VERSION "WangHu V1.0"

NS_ :

BS_:

BU_: SBCU MBCU Tester Monitor01

BO_ 2551357615 SBCU15_State_Inf6: 8 SBCU
 SG_ SBCU15_Reports_Set_Status : 18|3@0+ (1,0) [0|0] ""  MBCU
 SG_ SBCU15_Confirms_Faultcode : 7|16@0+ (1,0) [0|0] ""  MBCU

BO_ 2551357614 SBCU14_State_Inf6: 8 SBCU
 SG_ SBCU14_Reports_Set_Status : 18|3@0+ (1,0) [0|0] ""  MBCU
 SG_ SBCU14_Confirms_Faultcode : 7|16@0+ (1,0) [0|0] ""  MBCU

BO_ 2551357613 SBCU13_State_Inf6: 8 SBCU
 SG_ SBCU13_Reports_Set_Status : 18|3@0+ (1,0) [0|0] ""  MBCU
 SG_ SBCU13_Confirms_Faultcode : 7|16@0+ (1,0) [0|0] ""  MBCU

BO_ 2551357612 SBCU12_State_Inf6: 8 SBCU
 SG_ SBCU12_Reports_Set_Status : 18|3@0+ (1,0) [0|0] ""  MBCU
 SG_ SBCU12_Confirms_Faultcode : 7|16@0+ (1,0) [0|0] ""  MBCU

BO_ 2551357611 SBCU11_State_Inf6: 8 SBCU
 SG_ SBCU11_Reports_Set_Status : 18|3@0+ (1,0) [0|0] ""  MBCU
 SG_ SBCU11_Confirms_Faultcode : 7|16@0+ (1,0) [0|0] ""  MBCU

BO_ 2551357610 SBCU10_State_Inf6: 8 SBCU
 SG_ SBCU10_Reports_Set_Status : 18|3@0+ (1,0) [0|0] ""  MBCU
 SG_ SBCU10_Confirms_Faultcode : 7|16@0+ (1,0) [0|0] ""  MBCU

BO_ 2551357609 SBCU9_State_Inf6: 8 SBCU
 SG_ SBCU9_Reports_Set_Status : 18|3@0+ (1,0) [0|0] ""  MBCU
 SG_ SBCU9_Confirms_Faultcode : 7|16@0+ (1,0) [0|0] ""  MBCU

BO_ 2551357608 SBCU8_State_Inf6: 8 SBCU
 SG_ SBCU8_Reports_Set_Status : 18|3@0+ (1,0) [0|0] ""  MBCU
 SG_ SBCU8_Confirms_Faultcode : 7|16@0+ (1,0) [0|0] ""  MBCU

BO_ 2551357607 SBCU7_State_Inf6: 8 SBCU
 SG_ SBCU7_Reports_Set_Status : 18|3@0+ (1,0) [0|0] ""  MBCU
 SG_ SBCU7_Confirms_Faultcode : 7|16@0+ (1,0) [0|0] ""  MBCU

BO_ 2551357606 SBCU6_State_Inf6: 8 SBCU
 SG_ SBCU6_Reports_Set_Status : 18|3@0+ (1,0) [0|0] ""  MBCU
 SG_ SBCU6_Confirms_Faultcode : 7|16@0+ (1,0) [0|0] ""  MBCU

BO_ 2551357605 SBCU5_State_Inf6: 8 SBCU
 SG_ SBCU5_Reports_Set_Status : 18|3@0+ (1,0) [0|0] ""  MBCU
 SG_ SBCU5_Confirms_Faultcode : 7|16@0+ (1,0) [0|0] ""  MBCU

BO_ 2551357604 SBCU4_State_Inf6: 8 SBCU
 SG_ SBCU4_Reports_Set_Status : 18|3@0+ (1,0) [0|0] ""  MBCU
 SG_ SBCU4_Confirms_Faultcode : 7|16@0+ (1,0) [0|0] ""  MBCU

BO_ 2551357603 SBCU3_State_Inf6: 8 SBCU
 SG_ SBCU3_Reports_Set_Status : 18|3@0+ (1,0) [0|0] ""  MBCU
 SG_ SBCU3_Confirms_Faultcode : 7|16@0+ (1,0) [0|0] ""  MBCU

BO_ 2551357602 SBCU2_State_Inf6: 8 SBCU
 SG_ SBCU2_Reports_Set_Status : 18|3@0+ (1,0) [0|0] ""  MBCU
 SG_ SBCU2_Confirms_Faultcode : 7|16@0+ (1,0) [0|0] ""  MBCU

BO_ 2551357601 SBCU1_State_Inf6: 8 SBCU
 SG_ SBCU1_Reports_Set_Status : 18|3@0+ (1,0) [0|0] ""  MBCU
 SG_ SBCU1_Confirms_Faultcode : 7|16@0+ (1,0) [0|0] ""  MBCU

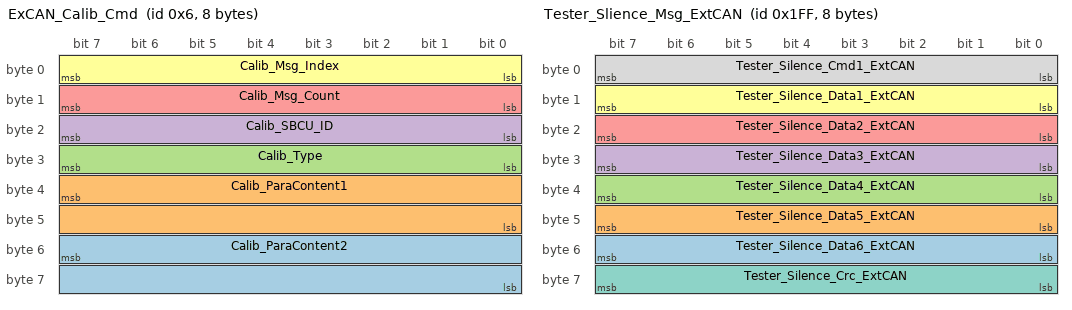
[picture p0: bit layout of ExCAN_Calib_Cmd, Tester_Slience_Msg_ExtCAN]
BO_ 6 ExCAN_Calib_Cmd: 8 MBCU
 SG_ Calib_ParaContent2 : 55|16@0+ (1,0) [0|0] ""  SBCU
 SG_ Calib_ParaContent1 : 39|16@0+ (1,0) [0|0] ""  SBCU
 SG_ Calib_Type : 31|8@0+ (1,0) [0|0] ""  SBCU
 SG_ Calib_SBCU_ID : 23|8@0+ (1,0) [0|0] ""  SBCU
 SG_ Calib_Msg_Count : 15|8@0+ (1,0) [0|0] ""  SBCU
 SG_ Calib_Msg_Index : 7|8@0+ (1,0) [0|0] ""  SBCU

BO_ 2551292079 SBCU15_State_Inf5: 8 SBCU
 SG_ SBCU15_ReleaseVersion : 7|32@0+ (1,0) [0|4294967295] ""  MBCU
 SG_ SBCU15_BMU_ReleaseVersion : 47|24@0+ (1,0) [0|0] ""  MBCU
 SG_ SBCU15_BMU_Index : 39|8@0+ (1,0) [0|0] ""  MBCU

BO_ 2551292078 SBCU14_State_Inf5: 8 SBCU
 SG_ SBCU14_ReleaseVersion : 7|32@0+ (1,0) [0|4294967295] ""  MBCU
 SG_ SBCU14_BMU_ReleaseVersion : 47|24@0+ (1,0) [0|0] ""  MBCU
 SG_ SBCU14_BMU_Index : 39|8@0+ (1,0) [0|0] ""  MBCU

BO_ 2551292077 SBCU13_State_Inf5: 8 SBCU
 SG_ SBCU13_ReleaseVersion : 7|32@0+ (1,0) [0|4294967295] ""  MBCU
 SG_ SBCU13_BMU_ReleaseVersion : 47|24@0+ (1,0) [0|0] ""  MBCU
 SG_ SBCU13_BMU_Index : 39|8@0+ (1,0) [0|0] ""  MBCU

BO_ 2551292076 SBCU12_State_Inf5: 8 SBCU
 SG_ SBCU12_ReleaseVersion : 7|32@0+ (1,0) [0|4294967295] ""  MBCU
 SG_ SBCU12_BMU_ReleaseVersion : 47|24@0+ (1,0) [0|0] ""  MBCU
 SG_ SBCU12_BMU_Index : 39|8@0+ (1,0) [0|0] ""  MBCU

BO_ 2551292075 SBCU11_State_Inf5: 8 SBCU
 SG_ SBCU11_ReleaseVersion : 7|32@0+ (1,0) [0|4294967295] ""  MBCU
 SG_ SBCU11_BMU_ReleaseVersion : 47|24@0+ (1,0) [0|0] ""  MBCU
 SG_ SBCU11_BMU_Index : 39|8@0+ (1,0) [0|0] ""  MBCU

BO_ 2551292074 SBCU10_State_Inf5: 8 SBCU
 SG_ SBCU10_ReleaseVersion : 7|32@0+ (1,0) [0|4294967295] ""  MBCU
 SG_ SBCU10_BMU_ReleaseVersion : 47|24@0+ (1,0) [0|0] ""  MBCU
 SG_ SBCU10_BMU_Index : 39|8@0+ (1,0) [0|0] ""  MBCU

BO_ 2551292073 SBCU9_State_Inf5: 8 SBCU
 SG_ SBCU9_ReleaseVersion : 7|32@0+ (1,0) [0|4294967295] ""  MBCU
 SG_ SBCU9_BMU_ReleaseVersion : 47|24@0+ (1,0) [0|0] ""  MBCU
 SG_ SBCU9_BMU_Index : 39|8@0+ (1,0) [0|0] ""  MBCU

BO_ 2551292072 SBCU8_State_Inf5: 8 SBCU
 SG_ SBCU8_ReleaseVersion : 7|32@0+ (1,0) [0|4294967295] ""  MBCU
 SG_ SBCU8_BMU_ReleaseVersion : 47|24@0+ (1,0) [0|0] ""  MBCU
 SG_ SBCU8_BMU_Index : 39|8@0+ (1,0) [0|0] ""  MBCU

BO_ 2551292071 SBCU7_State_Inf5: 8 SBCU
 SG_ SBCU7_ReleaseVersion : 7|32@0+ (1,0) [0|4294967295] ""  MBCU
 SG_ SBCU7_BMU_ReleaseVersion : 47|24@0+ (1,0) [0|0] ""  MBCU
 SG_ SBCU7_BMU_Index : 39|8@0+ (1,0) [0|0] ""  MBCU

BO_ 2551292070 SBCU6_State_Inf5: 8 SBCU
 SG_ SBCU6_ReleaseVersion : 7|32@0+ (1,0) [0|4294967295] ""  MBCU
 SG_ SBCU6_BMU_ReleaseVersion : 47|24@0+ (1,0) [0|0] ""  MBCU
 SG_ SBCU6_BMU_Index : 39|8@0+ (1,0) [0|0] ""  MBCU

BO_ 2551292069 SBCU5_State_Inf5: 8 SBCU
 SG_ SBCU5_ReleaseVersion : 7|32@0+ (1,0) [0|4294967295] ""  MBCU
 SG_ SBCU5_BMU_ReleaseVersion : 47|24@0+ (1,0) [0|0] ""  MBCU
 SG_ SBCU5_BMU_Index : 39|8@0+ (1,0) [0|0] ""  MBCU

BO_ 2551292068 SBCU4_State_Inf5: 8 SBCU
 SG_ SBCU4_ReleaseVersion : 7|32@0+ (1,0) [0|4294967295] ""  MBCU
 SG_ SBCU4_BMU_ReleaseVersion : 47|24@0+ (1,0) [0|0] ""  MBCU
 SG_ SBCU4_BMU_Index : 39|8@0+ (1,0) [0|0] ""  MBCU

BO_ 2551292067 SBCU3_State_Inf5: 8 SBCU
 SG_ SBCU3_ReleaseVersion : 7|32@0+ (1,0) [0|4294967295] ""  MBCU
 SG_ SBCU3_BMU_ReleaseVersion : 47|24@0+ (1,0) [0|0] ""  MBCU
 SG_ SBCU3_BMU_Index : 39|8@0+ (1,0) [0|0] ""  MBCU

BO_ 2551292066 SBCU2_State_Inf5: 8 SBCU
 SG_ SBCU2_ReleaseVersion : 7|32@0+ (1,0) [0|4294967295] ""  MBCU
 SG_ SBCU2_BMU_ReleaseVersion : 47|24@0+ (1,0) [0|0] ""  MBCU
 SG_ SBCU2_BMU_Index : 39|8@0+ (1,0) [0|0] ""  MBCU

BO_ 2551292065 SBCU1_State_Inf5: 8 SBCU
 SG_ SBCU1_BMU_ReleaseVersion : 47|24@0+ (1,0) [0|0] ""  MBCU
 SG_ SBCU1_BMU_Index : 39|8@0+ (1,0) [0|0] ""  MBCU
 SG_ SBCU1_ReleaseVersion : 7|32@0+ (1,0) [0|4294967295] ""  MBCU

BO_ 511 Tester_Slience_Msg_ExtCAN: 8 MBCU
 SG_ Tester_Silence_Data6_ExtCAN : 55|8@0+ (1,0) [0|0] ""  SBCU
 SG_ Tester_Silence_Data5_ExtCAN : 47|8@0+ (1,0) [0|0] ""  SBCU
 SG_ Tester_Silence_Data4_ExtCAN : 39|8@0+ (1,0) [0|0] ""  SBCU
 SG_ Tester_Silence_Data3_ExtCAN : 31|8@0+ (1,0) [0|0] ""  SBCU
 SG_ Tester_Silence_Data2_ExtCAN : 23|8@0+ (1,0) [0|0] ""  SBCU
 SG_ Tester_Silence_Data1_ExtCAN : 15|8@0+ (1,0) [0|0] ""  SBCU
 SG_ Tester_Silence_Crc_ExtCAN : 63|8@0+ (1,0) [0|0] ""  SBCU
 SG_ Tester_Silence_Cmd1_ExtCAN : 7|8@0+ (1,0) [0|0] ""  SBCU

BO_ 2551226543 SBCU15_State_Inf4: 8 SBCU
 SG_ SBCU15_CutOff_Relay_Pack_Volt : 23|16@0+ (0.1,0) [0|2000] "V"  MBCU
 SG_ SBCU15_CutOff_Relay_Current : 7|16@0+ (0.1,-3200) [0|0] "A"  MBCU

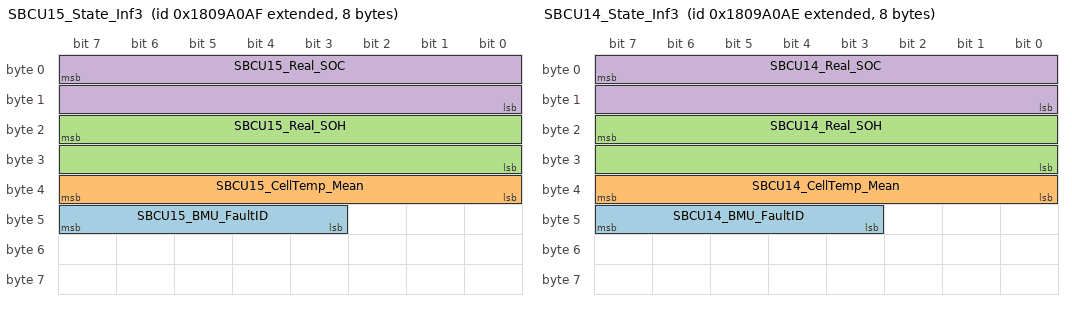
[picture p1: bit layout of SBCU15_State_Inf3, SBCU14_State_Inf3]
BO_ 2550767791 SBCU15_State_Inf3: 8 SBCU
 SG_ SBCU15_BMU_FaultID : 47|5@0+ (1,0) [0|0] ""  MBCU
 SG_ SBCU15_CellTemp_Mean : 39|8@0+ (1,-40) [0|0] "��"  MBCU
 SG_ SBCU15_Real_SOH : 23|16@0+ (0.1,0) [0|100] "%"  MBCU
 SG_ SBCU15_Real_SOC : 7|16@0+ (0.1,0) [0|100] "%"  MBCU

BO_ 2551226542 SBCU14_State_Inf4: 8 SBCU
 SG_ SBCU14_CutOff_Relay_Pack_Volt : 23|16@0+ (0.1,0) [0|2000] "V"  MBCU
 SG_ SBCU14_CutOff_Relay_Current : 7|16@0+ (0.1,-3200) [0|0] "A"  MBCU

BO_ 2550767790 SBCU14_State_Inf3: 8 SBCU
 SG_ SBCU14_BMU_FaultID : 47|5@0+ (1,0) [0|0] ""  MBCU
 SG_ SBCU14_CellTemp_Mean : 39|8@0+ (1,-40) [0|0] "��"  MBCU
 SG_ SBCU14_Real_SOH : 23|16@0+ (0.1,0) [0|100] "%"  MBCU
 SG_ SBCU14_Real_SOC : 7|16@0+ (0.1,0) [0|100] "%"  MBCU

BO_ 2551226541 SBCU13_State_Inf4: 8 SBCU
 SG_ SBCU13_CutOff_Relay_Pack_Volt : 23|16@0+ (0.1,0) [0|2000] "V"  MBCU
 SG_ SBCU13_CutOff_Relay_Current : 7|16@0+ (0.1,-3200) [0|0] "A"  MBCU

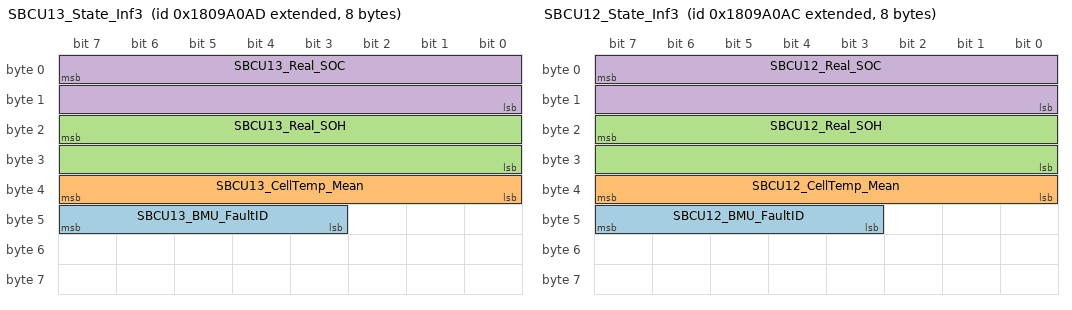
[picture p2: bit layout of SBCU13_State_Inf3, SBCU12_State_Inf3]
BO_ 2550767789 SBCU13_State_Inf3: 8 SBCU
 SG_ SBCU13_BMU_FaultID : 47|5@0+ (1,0) [0|0] ""  MBCU
 SG_ SBCU13_CellTemp_Mean : 39|8@0+ (1,-40) [0|0] "��"  MBCU
 SG_ SBCU13_Real_SOH : 23|16@0+ (0.1,0) [0|100] "%"  MBCU
 SG_ SBCU13_Real_SOC : 7|16@0+ (0.1,0) [0|100] "%"  MBCU

BO_ 2551226540 SBCU12_State_Inf4: 8 SBCU
 SG_ SBCU12_CutOff_Relay_Pack_Volt : 23|16@0+ (0.1,0) [0|2000] "V"  MBCU
 SG_ SBCU12_CutOff_Relay_Current : 7|16@0+ (0.1,-3200) [0|0] "A"  MBCU

BO_ 2550767788 SBCU12_State_Inf3: 8 SBCU
 SG_ SBCU12_BMU_FaultID : 47|5@0+ (1,0) [0|0] ""  MBCU
 SG_ SBCU12_CellTemp_Mean : 39|8@0+ (1,-40) [0|0] "��"  MBCU
 SG_ SBCU12_Real_SOH : 23|16@0+ (0.1,0) [0|100] "%"  MBCU
 SG_ SBCU12_Real_SOC : 7|16@0+ (0.1,0) [0|100] "%"  MBCU

BO_ 2551226539 SBCU11_State_Inf4: 8 SBCU
 SG_ SBCU11_CutOff_Relay_Pack_Volt : 23|16@0+ (0.1,0) [0|2000] "V"  MBCU
 SG_ SBCU11_CutOff_Relay_Current : 7|16@0+ (0.1,-3200) [0|0] "A"  MBCU

BO_ 2550767787 SBCU11_State_Inf3: 8 SBCU
 SG_ SBCU11_BMU_FaultID : 47|5@0+ (1,0) [0|0] ""  MBCU
 SG_ SBCU11_CellTemp_Mean : 39|8@0+ (1,-40) [0|0] "��"  MBCU
 SG_ SBCU11_Real_SOH : 23|16@0+ (0.1,0) [0|100] "%"  MBCU
 SG_ SBCU11_Real_SOC : 7|16@0+ (0.1,0) [0|100] "%"  MBCU

BO_ 2551226538 SBCU10_State_Inf4: 8 SBCU
 SG_ SBCU10_CutOff_Relay_Pack_Volt : 23|16@0+ (0.1,0) [0|2000] "V"  MBCU
 SG_ SBCU10_CutOff_Relay_Current : 7|16@0+ (0.1,-3200) [0|0] "A"  MBCU

BO_ 2550767786 SBCU10_State_Inf3: 8 SBCU
 SG_ SBCU10_BMU_FaultID : 47|5@0+ (1,0) [0|0] ""  MBCU
 SG_ SBCU10_CellTemp_Mean : 39|8@0+ (1,-40) [0|0] "��"  MBCU
 SG_ SBCU10_Real_SOH : 23|16@0+ (0.1,0) [0|100] "%"  MBCU
 SG_ SBCU10_Real_SOC : 7|16@0+ (0.1,0) [0|100] "%"  MBCU

BO_ 2551226537 SBCU9_State_Inf4: 8 SBCU
 SG_ SBCU9_CutOff_Relay_Pack_Volt : 23|16@0+ (0.1,0) [0|2000] "V"  MBCU
 SG_ SBCU9_CutOff_Relay_Current : 7|16@0+ (0.1,-3200) [0|0] "A"  MBCU

BO_ 2550767785 SBCU9_State_Inf3: 8 SBCU
 SG_ SBCU9_BMU_FaultID : 47|5@0+ (1,0) [0|0] ""  MBCU
 SG_ SBCU9_CellTemp_Mean : 39|8@0+ (1,-40) [0|0] "��"  MBCU
 SG_ SBCU9_Real_SOH : 23|16@0+ (0.1,0) [0|100] "%"  MBCU
 SG_ SBCU9_Real_SOC : 7|16@0+ (0.1,0) [0|100] "%"  MBCU

BO_ 2551226536 SBCU8_State_Inf4: 8 SBCU
 SG_ SBCU8_CutOff_Relay_Pack_Volt : 23|16@0+ (0.1,0) [0|2000] "V"  MBCU
 SG_ SBCU8_CutOff_Relay_Current : 7|16@0+ (0.1,-3200) [0|0] "A"  MBCU

BO_ 2550767784 SBCU8_State_Inf3: 8 SBCU
 SG_ SBCU8_BMU_FaultID : 47|5@0+ (1,0) [0|0] ""  MBCU
 SG_ SBCU8_CellTemp_Mean : 39|8@0+ (1,-40) [0|0] "��"  MBCU
 SG_ SBCU8_Real_SOH : 23|16@0+ (0.1,0) [0|100] "%"  MBCU
 SG_ SBCU8_Real_SOC : 7|16@0+ (0.1,0) [0|100] "%"  MBCU

BO_ 2551226535 SBCU7_State_Inf4: 8 SBCU
 SG_ SBCU7_CutOff_Relay_Pack_Volt : 23|16@0+ (0.1,0) [0|2000] "V"  MBCU
 SG_ SBCU7_CutOff_Relay_Current : 7|16@0+ (0.1,-3200) [0|0] "A"  MBCU

BO_ 2550767783 SBCU7_State_Inf3: 8 SBCU
 SG_ SBCU7_BMU_FaultID : 47|5@0+ (1,0) [0|0] ""  MBCU
 SG_ SBCU7_CellTemp_Mean : 39|8@0+ (1,-40) [0|0] "��"  MBCU
 SG_ SBCU7_Real_SOH : 23|16@0+ (0.1,0) [0|100] "%"  MBCU
 SG_ SBCU7_Real_SOC : 7|16@0+ (0.1,0) [0|100] "%"  MBCU

BO_ 2551226534 SBCU6_State_Inf4: 8 SBCU
 SG_ SBCU6_CutOff_Relay_Pack_Volt : 23|16@0+ (0.1,0) [0|2000] "V"  MBCU
 SG_ SBCU6_CutOff_Relay_Current : 7|16@0+ (0.1,-3200) [0|0] "A"  MBCU

BO_ 2550767782 SBCU6_State_Inf3: 8 SBCU
 SG_ SBCU6_BMU_FaultID : 47|5@0+ (1,0) [0|0] ""  MBCU
 SG_ SBCU6_CellTemp_Mean : 39|8@0+ (1,-40) [0|0] "��"  MBCU
 SG_ SBCU6_Real_SOH : 23|16@0+ (0.1,0) [0|100] "%"  MBCU
 SG_ SBCU6_Real_SOC : 7|16@0+ (0.1,0) [0|100] "%"  MBCU

BO_ 2551226533 SBCU5_State_Inf4: 8 SBCU
 SG_ SBCU5_CutOff_Relay_Pack_Volt : 23|16@0+ (0.1,0) [0|2000] "V"  MBCU
 SG_ SBCU5_CutOff_Relay_Current : 7|16@0+ (0.1,-3200) [0|0] "A"  MBCU

BO_ 2550767781 SBCU5_State_Inf3: 8 SBCU
 SG_ SBCU5_BMU_FaultID : 47|5@0+ (1,0) [0|0] ""  MBCU
 SG_ SBCU5_CellTemp_Mean : 39|8@0+ (1,-40) [0|0] "��"  MBCU
 SG_ SBCU5_Real_SOH : 23|16@0+ (0.1,0) [0|100] "%"  MBCU
 SG_ SBCU5_Real_SOC : 7|16@0+ (0.1,0) [0|100] "%"  MBCU

BO_ 2551226532 SBCU4_State_Inf4: 8 SBCU
 SG_ SBCU4_CutOff_Relay_Pack_Volt : 23|16@0+ (0.1,0) [0|2000] "V"  MBCU
 SG_ SBCU4_CutOff_Relay_Current : 7|16@0+ (0.1,-3200) [0|0] "A"  MBCU

BO_ 2550767780 SBCU4_State_Inf3: 8 SBCU
 SG_ SBCU4_BMU_FaultID : 47|5@0+ (1,0) [0|0] ""  MBCU
 SG_ SBCU4_CellTemp_Mean : 39|8@0+ (1,-40) [0|0] "��"  MBCU
 SG_ SBCU4_Real_SOH : 23|16@0+ (0.1,0) [0|100] "%"  MBCU
 SG_ SBCU4_Real_SOC : 7|16@0+ (0.1,0) [0|100] "%"  MBCU

BO_ 2551226531 SBCU3_State_Inf4: 8 SBCU
 SG_ SBCU3_CutOff_Relay_Pack_Volt : 23|16@0+ (0.1,0) [0|2000] "V"  MBCU
 SG_ SBCU3_CutOff_Relay_Current : 7|16@0+ (0.1,-3200) [0|0] "A"  MBCU

BO_ 2550767779 SBCU3_State_Inf3: 8 SBCU
 SG_ SBCU3_BMU_FaultID : 47|5@0+ (1,0) [0|0] ""  MBCU
 SG_ SBCU3_CellTemp_Mean : 39|8@0+ (1,-40) [0|0] "��"  MBCU
 SG_ SBCU3_Real_SOH : 23|16@0+ (0.1,0) [0|100] "%"  MBCU
 SG_ SBCU3_Real_SOC : 7|16@0+ (0.1,0) [0|100] "%"  MBCU

BO_ 2551226530 SBCU2_State_Inf4: 8 SBCU
 SG_ SBCU2_CutOff_Relay_Pack_Volt : 23|16@0+ (0.1,0) [0|2000] "V"  MBCU
 SG_ SBCU2_CutOff_Relay_Current : 7|16@0+ (0.1,-3200) [0|0] "A"  MBCU

BO_ 2550767778 SBCU2_State_Inf3: 8 SBCU
 SG_ SBCU2_BMU_FaultID : 47|5@0+ (1,0) [0|0] ""  MBCU
 SG_ SBCU2_CellTemp_Mean : 39|8@0+ (1,-40) [0|0] "��"  MBCU
 SG_ SBCU2_Real_SOH : 23|16@0+ (0.1,0) [0|100] "%"  MBCU
 SG_ SBCU2_Real_SOC : 7|16@0+ (0.1,0) [0|100] "%"  MBCU

BO_ 2551226529 SBCU1_State_Inf4: 8 SBCU
 SG_ SBCU1_CutOff_Relay_Pack_Volt : 23|16@0+ (0.1,0) [0|2000] "V"  MBCU
 SG_ SBCU1_CutOff_Relay_Current : 7|16@0+ (0.1,-3200) [0|0] "A"  MBCU

BO_ 2550767777 SBCU1_State_Inf3: 8 SBCU
 SG_ SBCU1_BMU_FaultID : 47|5@0+ (1,0) [0|0] ""  MBCU
 SG_ SBCU1_CellTemp_Mean : 39|8@0+ (1,-40) [0|0] "��"  MBCU
 SG_ SBCU1_Real_SOH : 23|16@0+ (0.1,0) [0|100] "%"  MBCU
 SG_ SBCU1_Real_SOC : 7|16@0+ (0.1,0) [0|100] "%"  MBCU

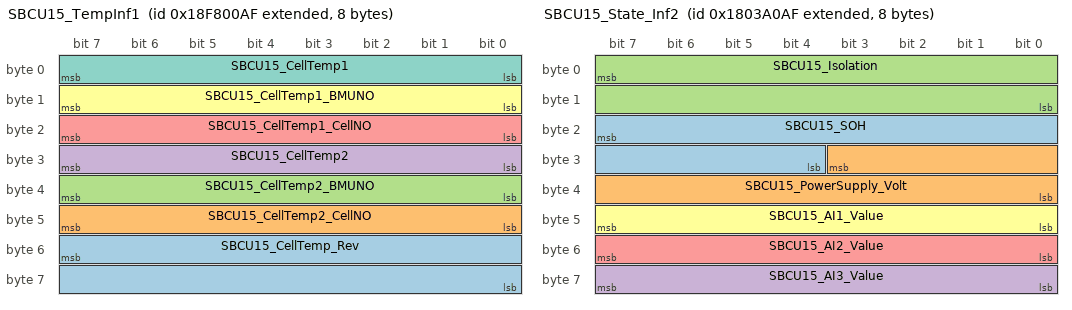
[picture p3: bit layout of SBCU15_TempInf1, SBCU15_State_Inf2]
BO_ 2566389935 SBCU15_TempInf1: 8 SBCU
 SG_ SBCU15_CellTemp_Rev : 55|16@0+ (1,0) [0|65535] ""  MBCU
 SG_ SBCU15_CellTemp2_CellNO : 47|8@0+ (1,0) [0|0] ""  MBCU
 SG_ SBCU15_CellTemp2_BMUNO : 39|8@0+ (1,0) [0|0] ""  MBCU
 SG_ SBCU15_CellTemp2 : 31|8@0+ (1,-40) [0|0] "��"  MBCU
 SG_ SBCU15_CellTemp1_CellNO : 23|8@0+ (1,0) [0|0] ""  MBCU
 SG_ SBCU15_CellTemp1_BMUNO : 15|8@0+ (1,0) [0|0] ""  MBCU
 SG_ SBCU15_CellTemp1 : 7|8@0+ (1,-40) [0|0] "��"  MBCU

BO_ 2550898863 SBCU15_Statis_AccumEng: 8 SBCU
 SG_ SBCU15_Accum_DchEng : 7|32@0+ (0.1,0) [0|4000000000] "kWh"  MBCU
 SG_ SBCU15_Accum_ChgEng : 39|32@0+ (0.1,0) [0|4000000000] "kWh"  MBCU

BO_ 2550833327 SBCU15_Statis_AccumCap: 8 SBCU
 SG_ SBCU15_Accum_DchCap : 7|32@0+ (0.1,0) [0|4000000000] "Ah"  MBCU
 SG_ SBCU15_Accum_ChgCap : 39|32@0+ (0.1,0) [0|4000000000] "Ah"  MBCU

BO_ 2550374575 SBCU15_State_Inf2: 8 SBCU
 SG_ SBCU15_SOH : 23|12@0+ (0.1,0) [0|0] "%"  MBCU
 SG_ SBCU15_PowerSupply_Volt : 27|12@0+ (0.1,0) [0|0] "V"  MBCU
 SG_ SBCU15_Isolation : 7|16@0+ (1,0) [0|65535] "kOhm"  MBCU
 SG_ SBCU15_AI3_Value : 63|8@0+ (1,0) [0|255] ""  MBCU
 SG_ SBCU15_AI2_Value : 55|8@0+ (1,0) [0|255] ""  MBCU
 SG_ SBCU15_AI1_Value : 47|8@0+ (1,0) [0|255] ""  MBCU

BO_ 2348982447 SBCU15_State_Inf1: 8 SBCU
 SG_ SBCU15_WorkMode : 11|4@0+ (1,0) [0|0] ""  MBCU
 SG_ SBCU15_Ready : 1|2@0+ (1,0) [0|0] ""  MBCU
 SG_ SBCU15_PreChgRelay_Status : 29|2@0+ (1,0) [0|0] ""  MBCU
 SG_ SBCU15_PosRelay_Status : 25|2@0+ (1,0) [0|0] ""  MBCU
 SG_ SBCU15_PosIso_Optical : 56|1@0+ (1,0) [0|0] ""  MBCU
 SG_ SBCU15_NegRelay_Status : 27|2@0+ (1,0) [0|0] ""  MBCU
 SG_ SBCU15_NegIso_Optical : 57|1@0+ (1,0) [0|0] ""  MBCU
 SG_ SBCU15_Life : 63|4@0+ (1,0) [0|0] ""  MBCU
 SG_ SBCU15_ISO_Status : 7|2@0+ (1,0) [0|3] ""  MBCU
 SG_ SBCU15_ISO_Allow : 5|2@0+ (1,0) [0|3] ""  MBCU
 SG_ SBCU15_HVOff_Req : 3|2@0+ (1,0) [0|0] ""  MBCU
 SG_ SBCU15_HV_Step : 15|4@0+ (1,0) [0|0] ""  MBCU
 SG_ SBCU15_HeatRelay_Status : 23|2@0+ (1,0) [0|0] ""  MBCU
 SG_ SBCU15_FcgRelay_Status : 31|2@0+ (1,0) [0|0] ""  MBCU
 SG_ SBCU15_FaultLevel : 59|2@0+ (1,0) [0|3] ""  MBCU
 SG_ SBCU15_FaultCode : 47|16@0+ (1,0) [0|65535] ""  MBCU
 SG_ SBCU15_FanRelay_Status : 21|2@0+ (1,0) [0|0] ""  MBCU
 SG_ SBCU15_DO3_Ctrl : 39|1@0+ (1,0) [0|0] ""  MBCU
 SG_ SBCU15_DO2_Ctrl : 38|1@0+ (1,0) [0|0] ""  MBCU
 SG_ SBCU15_DO1_Ctrl : 37|1@0+ (1,0) [0|0] ""  MBCU
 SG_ SBCU15_DI5_Status : 36|1@0+ (1,0) [0|0] ""  MBCU
 SG_ SBCU15_DI4_Status : 35|1@0+ (1,0) [0|0] ""  MBCU
 SG_ SBCU15_DI3_Status : 34|1@0+ (1,0) [0|0] ""  MBCU
 SG_ SBCU15_DI2_Status : 33|1@0+ (1,0) [0|0] ""  MBCU
 SG_ SBCU15_DI1_Status : 32|1@0+ (1,0) [0|0] ""  MBCU
 SG_ SBCU15_BMS_RunStatus : 19|4@0+ (1,0) [0|0] ""  MBCU

BO_ 2550505647 SBCU15_SOP_Inf2: 8 SBCU
 SG_ SBCU15_DchPeakPower_Limit : 7|16@0+ (0.1,0) [0|1000] "kW"  MBCU
 SG_ SBCU15_DchContinuousPower_Limit : 23|16@0+ (0.1,0) [0|1000] "kW"  MBCU
 SG_ SBCU15_ChgPeakPower_Limit : 39|16@0+ (0.1,0) [0|1000] "kW"  MBCU
 SG_ SBCU15_ChgContinuousPower_Limit : 55|16@0+ (0.1,0) [0|1000] "kW"  MBCU

BO_ 2550440111 SBCU15_SOP_Inf1: 8 SBCU
 SG_ SBCU15_DchPeakCurr_Limit : 7|16@0+ (0.1,0) [0|3200] "A"  MBCU
 SG_ SBCU15_DchContinuousCurr_Limit : 23|16@0+ (0.1,0) [0|3200] "A"  MBCU
 SG_ SBCU15_ChgPeakCurr_Limit : 39|16@0+ (0.1,0) [0|3200] "A"  MBCU
 SG_ SBCU15_ChgContinuousCurr_Limit : 55|16@0+ (0.1,0) [0|3200] "A"  MBCU

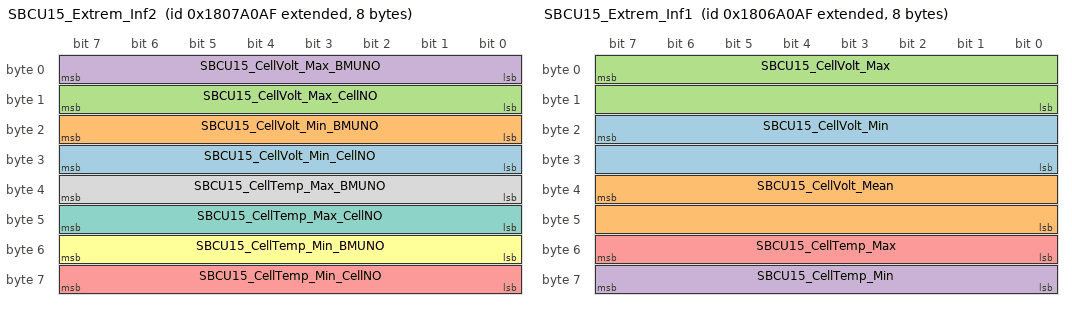
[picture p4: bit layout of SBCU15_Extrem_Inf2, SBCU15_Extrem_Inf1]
BO_ 2550636719 SBCU15_Extrem_Inf2: 8 SBCU
 SG_ SBCU15_CellVolt_Min_CellNO : 31|8@0+ (1,0) [0|255] ""  MBCU
 SG_ SBCU15_CellVolt_Min_BMUNO : 23|8@0+ (1,0) [0|16] ""  MBCU
 SG_ SBCU15_CellVolt_Max_CellNO : 15|8@0+ (1,0) [0|255] ""  MBCU
 SG_ SBCU15_CellVolt_Max_BMUNO : 7|8@0+ (1,0) [0|16] ""  MBCU
 SG_ SBCU15_CellTemp_Min_CellNO : 63|8@0+ (1,0) [0|255] ""  MBCU
 SG_ SBCU15_CellTemp_Min_BMUNO : 55|8@0+ (1,0) [0|16] ""  MBCU
 SG_ SBCU15_CellTemp_Max_CellNO : 47|8@0+ (1,0) [0|255] ""  MBCU
 SG_ SBCU15_CellTemp_Max_BMUNO : 39|8@0+ (1,0) [0|16] ""  MBCU

BO_ 2550571183 SBCU15_Extrem_Inf1: 8 SBCU
 SG_ SBCU15_CellVolt_Min : 23|16@0+ (0.001,0) [0|15] "V"  MBCU
 SG_ SBCU15_CellVolt_Mean : 39|16@0+ (0.001,0) [0|15] "V"  MBCU
 SG_ SBCU15_CellVolt_Max : 7|16@0+ (0.001,0) [0|15] "V"  MBCU
 SG_ SBCU15_CellTemp_Min : 63|8@0+ (1,-40) [0|0] "��"  MBCU
 SG_ SBCU15_CellTemp_Max : 55|8@0+ (1,-40) [0|0] "��"  MBCU

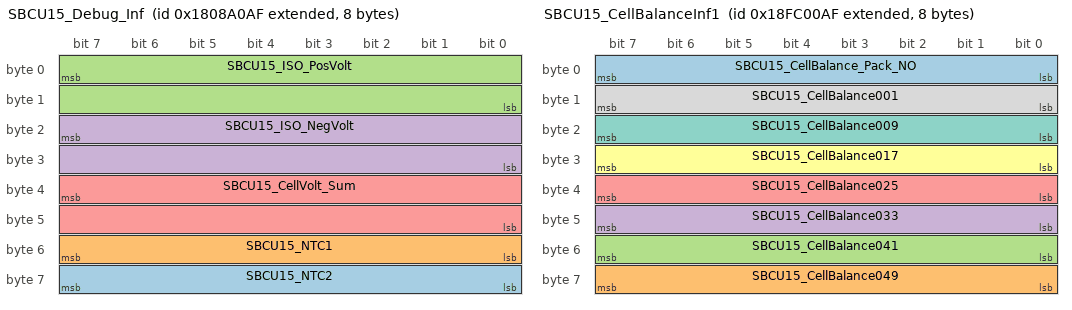
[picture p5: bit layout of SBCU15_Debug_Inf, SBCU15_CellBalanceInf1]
BO_ 2550702255 SBCU15_Debug_Inf: 8 SBCU
 SG_ SBCU15_NTC2 : 63|8@0+ (1,-40) [0|0] "��"  MBCU
 SG_ SBCU15_NTC1 : 55|8@0+ (1,-40) [0|0] "��"  MBCU
 SG_ SBCU15_ISO_PosVolt : 7|16@0+ (1,0) [0|65535] "mV"  MBCU
 SG_ SBCU15_ISO_NegVolt : 23|16@0+ (1,0) [0|65535] "mV"  MBCU
 SG_ SBCU15_CellVolt_Sum : 39|16@0+ (0.1,0) [0|0] "V"  MBCU

BO_ 2566652079 SBCU15_CellBalanceInf1: 8 SBCU
 SG_ SBCU15_CellBalance_Pack_NO : 7|8@0+ (1,0) [0|255] ""  MBCU
 SG_ SBCU15_CellBalance049 : 63|8@0+ (1,0) [0|255] ""  MBCU
 SG_ SBCU15_CellBalance041 : 55|8@0+ (1,0) [0|255] ""  MBCU
 SG_ SBCU15_CellBalance033 : 47|8@0+ (1,0) [0|255] ""  MBCU
 SG_ SBCU15_CellBalance025 : 39|8@0+ (1,0) [0|255] ""  MBCU
 SG_ SBCU15_CellBalance017 : 31|8@0+ (1,0) [0|255] ""  MBCU
 SG_ SBCU15_CellBalance009 : 23|8@0+ (1,0) [0|255] ""  MBCU
 SG_ SBCU15_CellBalance001 : 15|8@0+ (1,0) [0|255] ""  MBCU

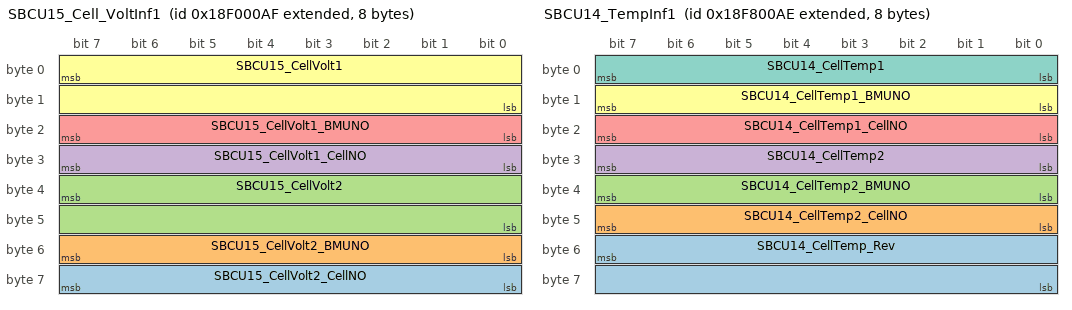
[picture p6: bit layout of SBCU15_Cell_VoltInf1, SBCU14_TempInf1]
BO_ 2565865647 SBCU15_Cell_VoltInf1: 8 SBCU
 SG_ SBCU15_CellVolt2_CellNO : 63|8@0+ (1,0) [0|0] ""  MBCU
 SG_ SBCU15_CellVolt2_BMUNO : 55|8@0+ (1,0) [0|0] ""  MBCU
 SG_ SBCU15_CellVolt2 : 39|16@0+ (0.001,0) [0|0] "V"  MBCU
 SG_ SBCU15_CellVolt1_CellNO : 31|8@0+ (1,0) [0|0] ""  MBCU
 SG_ SBCU15_CellVolt1_BMUNO : 23|8@0+ (1,0) [0|0] ""  MBCU
 SG_ SBCU15_CellVolt1 : 7|16@0+ (0.001,0) [0|0] "V"  MBCU

BO_ 2550243503 SBCU15_Basic_Inf: 8 SBCU
 SG_ SBCU15_SOC : 55|16@0+ (0.1,0) [0|100] "%"  MBCU
 SG_ SBCU15_Pack_Volt : 7|16@0+ (0.1,0) [0|2000] "V"  MBCU
 SG_ SBCU15_LinkVolt : 23|16@0+ (0.1,0) [0|2000] "V"  MBCU
 SG_ SBCU15_BusCurrent : 39|16@0+ (0.1,-3200) [0|0] "A"  MBCU

BO_ 2566389934 SBCU14_TempInf1: 8 SBCU
 SG_ SBCU14_CellTemp_Rev : 55|16@0+ (1,0) [0|65535] ""  MBCU
 SG_ SBCU14_CellTemp2_CellNO : 47|8@0+ (1,0) [0|0] ""  MBCU
 SG_ SBCU14_CellTemp2_BMUNO : 39|8@0+ (1,0) [0|0] ""  MBCU
 SG_ SBCU14_CellTemp2 : 31|8@0+ (1,-40) [0|0] "��"  MBCU
 SG_ SBCU14_CellTemp1_CellNO : 23|8@0+ (1,0) [0|0] ""  MBCU
 SG_ SBCU14_CellTemp1_BMUNO : 15|8@0+ (1,0) [0|0] ""  MBCU
 SG_ SBCU14_CellTemp1 : 7|8@0+ (1,-40) [0|0] "��"  MBCU

BO_ 2550898862 SBCU14_Statis_AccumEng: 8 SBCU
 SG_ SBCU14_Accum_DchEng : 7|32@0+ (0.1,0) [0|4000000000] "kWh"  MBCU
 SG_ SBCU14_Accum_ChgEng : 39|32@0+ (0.1,0) [0|4000000000] "kWh"  MBCU

BO_ 2550833326 SBCU14_Statis_AccumCap: 8 SBCU
 SG_ SBCU14_Accum_DchCap : 7|32@0+ (0.1,0) [0|4000000000] "Ah"  MBCU
 SG_ SBCU14_Accum_ChgCap : 39|32@0+ (0.1,0) [0|4000000000] "Ah"  MBCU

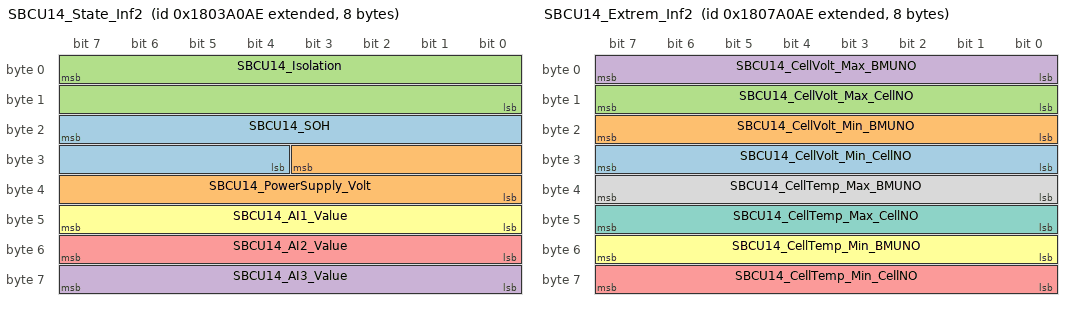
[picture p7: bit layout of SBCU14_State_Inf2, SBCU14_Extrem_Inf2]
BO_ 2550374574 SBCU14_State_Inf2: 8 SBCU
 SG_ SBCU14_SOH : 23|12@0+ (0.1,0) [0|0] "%"  MBCU
 SG_ SBCU14_PowerSupply_Volt : 27|12@0+ (0.1,0) [0|0] "V"  MBCU
 SG_ SBCU14_Isolation : 7|16@0+ (1,0) [0|65535] "kOhm"  MBCU
 SG_ SBCU14_AI3_Value : 63|8@0+ (1,0) [0|255] ""  MBCU
 SG_ SBCU14_AI2_Value : 55|8@0+ (1,0) [0|255] ""  MBCU
 SG_ SBCU14_AI1_Value : 47|8@0+ (1,0) [0|255] ""  MBCU

BO_ 2348982446 SBCU14_State_Inf1: 8 SBCU
 SG_ SBCU14_WorkMode : 11|4@0+ (1,0) [0|0] ""  MBCU
 SG_ SBCU14_Ready : 1|2@0+ (1,0) [0|0] ""  MBCU
 SG_ SBCU14_PreChgRelay_Status : 29|2@0+ (1,0) [0|0] ""  MBCU
 SG_ SBCU14_PosRelay_Status : 25|2@0+ (1,0) [0|0] ""  MBCU
 SG_ SBCU14_PosIso_Optical : 56|1@0+ (1,0) [0|0] ""  MBCU
 SG_ SBCU14_NegRelay_Status : 27|2@0+ (1,0) [0|0] ""  MBCU
 SG_ SBCU14_NegIso_Optical : 57|1@0+ (1,0) [0|0] ""  MBCU
 SG_ SBCU14_Life : 63|4@0+ (1,0) [0|0] ""  MBCU
 SG_ SBCU14_ISO_Status : 7|2@0+ (1,0) [0|3] ""  MBCU
 SG_ SBCU14_ISO_Allow : 5|2@0+ (1,0) [0|3] ""  MBCU
 SG_ SBCU14_HVOff_Req : 3|2@0+ (1,0) [0|0] ""  MBCU
 SG_ SBCU14_HV_Step : 15|4@0+ (1,0) [0|0] ""  MBCU
 SG_ SBCU14_HeatRelay_Status : 23|2@0+ (1,0) [0|0] ""  MBCU
 SG_ SBCU14_FcgRelay_Status : 31|2@0+ (1,0) [0|0] ""  MBCU
 SG_ SBCU14_FaultLevel : 59|2@0+ (1,0) [0|3] ""  MBCU
 SG_ SBCU14_FaultCode : 47|16@0+ (1,0) [0|65535] ""  MBCU
 SG_ SBCU14_FanRelay_Status : 21|2@0+ (1,0) [0|0] ""  MBCU
 SG_ SBCU14_DO3_Ctrl : 39|1@0+ (1,0) [0|0] ""  MBCU
 SG_ SBCU14_DO2_Ctrl : 38|1@0+ (1,0) [0|0] ""  MBCU
 SG_ SBCU14_DO1_Ctrl : 37|1@0+ (1,0) [0|0] ""  MBCU
 SG_ SBCU14_DI5_Status : 36|1@0+ (1,0) [0|0] ""  MBCU
 SG_ SBCU14_DI4_Status : 35|1@0+ (1,0) [0|0] ""  MBCU
 SG_ SBCU14_DI3_Status : 34|1@0+ (1,0) [0|0] ""  MBCU
 SG_ SBCU14_DI2_Status : 33|1@0+ (1,0) [0|0] ""  MBCU
 SG_ SBCU14_DI1_Status : 32|1@0+ (1,0) [0|0] ""  MBCU
 SG_ SBCU14_BMS_RunStatus : 19|4@0+ (1,0) [0|0] ""  MBCU

BO_ 2550505646 SBCU14_SOP_Inf2: 8 SBCU
 SG_ SBCU14_DchPeakPower_Limit : 7|16@0+ (0.1,0) [0|1000] "kW"  MBCU
 SG_ SBCU14_DchContinuousPower_Limit : 23|16@0+ (0.1,0) [0|1000] "kW"  MBCU
 SG_ SBCU14_ChgPeakPower_Limit : 39|16@0+ (0.1,0) [0|1000] "kW"  MBCU
 SG_ SBCU14_ChgContinuousPower_Limit : 55|16@0+ (0.1,0) [0|1000] "kW"  MBCU

BO_ 2550440110 SBCU14_SOP_Inf1: 8 SBCU
 SG_ SBCU14_DchPeakCurr_Limit : 7|16@0+ (0.1,0) [0|3200] "A"  MBCU
 SG_ SBCU14_DchContinuousCurr_Limit : 23|16@0+ (0.1,0) [0|3200] "A"  MBCU
 SG_ SBCU14_ChgPeakCurr_Limit : 39|16@0+ (0.1,0) [0|3200] "A"  MBCU
 SG_ SBCU14_ChgContinuousCurr_Limit : 55|16@0+ (0.1,0) [0|3200] "A"  MBCU

BO_ 2550636718 SBCU14_Extrem_Inf2: 8 SBCU
 SG_ SBCU14_CellVolt_Min_CellNO : 31|8@0+ (1,0) [0|255] ""  MBCU
 SG_ SBCU14_CellVolt_Min_BMUNO : 23|8@0+ (1,0) [0|16] ""  MBCU
 SG_ SBCU14_CellVolt_Max_CellNO : 15|8@0+ (1,0) [0|255] ""  MBCU
 SG_ SBCU14_CellVolt_Max_BMUNO : 7|8@0+ (1,0) [0|16] ""  MBCU
 SG_ SBCU14_CellTemp_Min_CellNO : 63|8@0+ (1,0) [0|255] ""  MBCU
 SG_ SBCU14_CellTemp_Min_BMUNO : 55|8@0+ (1,0) [0|16] ""  MBCU
 SG_ SBCU14_CellTemp_Max_CellNO : 47|8@0+ (1,0) [0|255] ""  MBCU
 SG_ SBCU14_CellTemp_Max_BMUNO : 39|8@0+ (1,0) [0|16] ""  MBCU

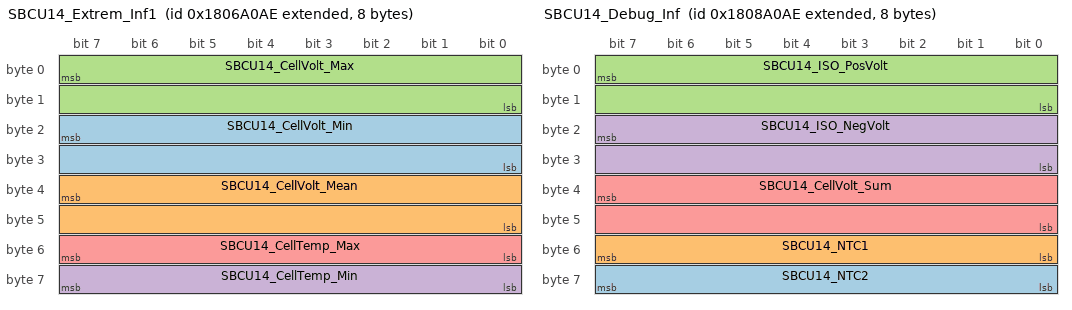
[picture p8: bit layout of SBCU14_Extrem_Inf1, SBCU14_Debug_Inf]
BO_ 2550571182 SBCU14_Extrem_Inf1: 8 SBCU
 SG_ SBCU14_CellVolt_Min : 23|16@0+ (0.001,0) [0|15] "V"  MBCU
 SG_ SBCU14_CellVolt_Mean : 39|16@0+ (0.001,0) [0|15] "V"  MBCU
 SG_ SBCU14_CellVolt_Max : 7|16@0+ (0.001,0) [0|15] "V"  MBCU
 SG_ SBCU14_CellTemp_Min : 63|8@0+ (1,-40) [0|0] "��"  MBCU
 SG_ SBCU14_CellTemp_Max : 55|8@0+ (1,-40) [0|0] "��"  MBCU

BO_ 2550702254 SBCU14_Debug_Inf: 8 SBCU
 SG_ SBCU14_NTC2 : 63|8@0+ (1,-40) [0|0] "��"  MBCU
 SG_ SBCU14_NTC1 : 55|8@0+ (1,-40) [0|0] "��"  MBCU
 SG_ SBCU14_ISO_PosVolt : 7|16@0+ (1,0) [0|65535] "mV"  MBCU
 SG_ SBCU14_ISO_NegVolt : 23|16@0+ (1,0) [0|65535] "mV"  MBCU
 SG_ SBCU14_CellVolt_Sum : 39|16@0+ (0.1,0) [0|0] "V"  MBCU

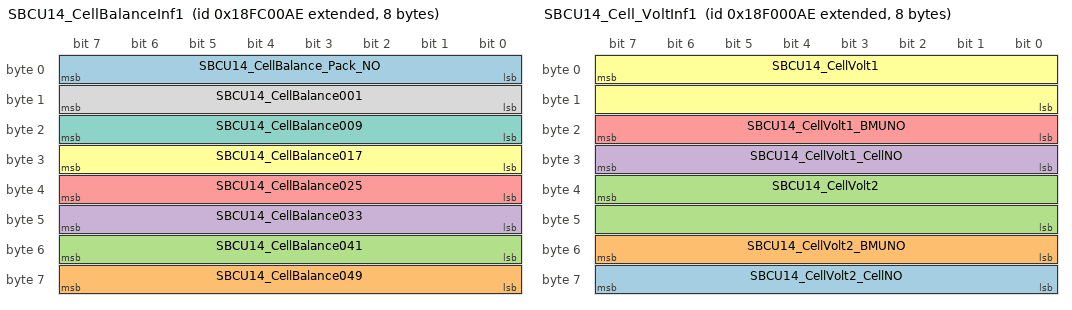
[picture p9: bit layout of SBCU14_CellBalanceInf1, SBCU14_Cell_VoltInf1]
BO_ 2566652078 SBCU14_CellBalanceInf1: 8 SBCU
 SG_ SBCU14_CellBalance_Pack_NO : 7|8@0+ (1,0) [0|255] ""  MBCU
 SG_ SBCU14_CellBalance049 : 63|8@0+ (1,0) [0|255] ""  MBCU
 SG_ SBCU14_CellBalance041 : 55|8@0+ (1,0) [0|255] ""  MBCU
 SG_ SBCU14_CellBalance033 : 47|8@0+ (1,0) [0|255] ""  MBCU
 SG_ SBCU14_CellBalance025 : 39|8@0+ (1,0) [0|255] ""  MBCU
 SG_ SBCU14_CellBalance017 : 31|8@0+ (1,0) [0|255] ""  MBCU
 SG_ SBCU14_CellBalance009 : 23|8@0+ (1,0) [0|255] ""  MBCU
 SG_ SBCU14_CellBalance001 : 15|8@0+ (1,0) [0|255] ""  MBCU

BO_ 2565865646 SBCU14_Cell_VoltInf1: 8 SBCU
 SG_ SBCU14_CellVolt2_CellNO : 63|8@0+ (1,0) [0|0] ""  MBCU
 SG_ SBCU14_CellVolt2_BMUNO : 55|8@0+ (1,0) [0|0] ""  MBCU
 SG_ SBCU14_CellVolt2 : 39|16@0+ (0.001,0) [0|0] "V"  MBCU
 SG_ SBCU14_CellVolt1_CellNO : 31|8@0+ (1,0) [0|0] ""  MBCU
 SG_ SBCU14_CellVolt1_BMUNO : 23|8@0+ (1,0) [0|0] ""  MBCU
 SG_ SBCU14_CellVolt1 : 7|16@0+ (0.001,0) [0|0] "V"  MBCU

BO_ 2550243502 SBCU14_Basic_Inf: 8 SBCU
 SG_ SBCU14_SOC : 55|16@0+ (0.1,0) [0|100] "%"  MBCU
 SG_ SBCU14_Pack_Volt : 7|16@0+ (0.1,0) [0|2000] "V"  MBCU
 SG_ SBCU14_LinkVolt : 23|16@0+ (0.1,0) [0|2000] "V"  MBCU
 SG_ SBCU14_BusCurrent : 39|16@0+ (0.1,-3200) [0|0] "A"  MBCU

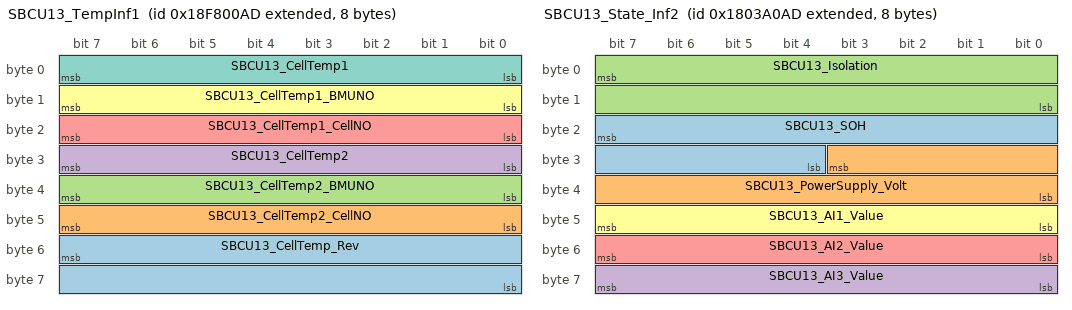
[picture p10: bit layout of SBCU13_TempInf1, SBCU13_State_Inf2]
BO_ 2566389933 SBCU13_TempInf1: 8 SBCU
 SG_ SBCU13_CellTemp_Rev : 55|16@0+ (1,0) [0|65535] ""  MBCU
 SG_ SBCU13_CellTemp2_CellNO : 47|8@0+ (1,0) [0|0] ""  MBCU
 SG_ SBCU13_CellTemp2_BMUNO : 39|8@0+ (1,0) [0|0] ""  MBCU
 SG_ SBCU13_CellTemp2 : 31|8@0+ (1,-40) [0|0] "��"  MBCU
 SG_ SBCU13_CellTemp1_CellNO : 23|8@0+ (1,0) [0|0] ""  MBCU
 SG_ SBCU13_CellTemp1_BMUNO : 15|8@0+ (1,0) [0|0] ""  MBCU
 SG_ SBCU13_CellTemp1 : 7|8@0+ (1,-40) [0|0] "��"  MBCU

BO_ 2550898861 SBCU13_Statis_AccumEng: 8 SBCU
 SG_ SBCU13_Accum_DchEng : 7|32@0+ (0.1,0) [0|4000000000] "kWh"  MBCU
 SG_ SBCU13_Accum_ChgEng : 39|32@0+ (0.1,0) [0|4000000000] "kWh"  MBCU

BO_ 2550833325 SBCU13_Statis_AccumCap: 8 SBCU
 SG_ SBCU13_Accum_DchCap : 7|32@0+ (0.1,0) [0|4000000000] "Ah"  MBCU
 SG_ SBCU13_Accum_ChgCap : 39|32@0+ (0.1,0) [0|4000000000] "Ah"  MBCU

BO_ 2550374573 SBCU13_State_Inf2: 8 SBCU
 SG_ SBCU13_SOH : 23|12@0+ (0.1,0) [0|0] "%"  MBCU
 SG_ SBCU13_PowerSupply_Volt : 27|12@0+ (0.1,0) [0|0] "V"  MBCU
 SG_ SBCU13_Isolation : 7|16@0+ (1,0) [0|65535] "kOhm"  MBCU
 SG_ SBCU13_AI3_Value : 63|8@0+ (1,0) [0|255] ""  MBCU
 SG_ SBCU13_AI2_Value : 55|8@0+ (1,0) [0|255] ""  MBCU
 SG_ SBCU13_AI1_Value : 47|8@0+ (1,0) [0|255] ""  MBCU

BO_ 2348982445 SBCU13_State_Inf1: 8 SBCU
 SG_ SBCU13_WorkMode : 11|4@0+ (1,0) [0|0] ""  MBCU
 SG_ SBCU13_Ready : 1|2@0+ (1,0) [0|0] ""  MBCU
 SG_ SBCU13_PreChgRelay_Status : 29|2@0+ (1,0) [0|0] ""  MBCU
 SG_ SBCU13_PosRelay_Status : 25|2@0+ (1,0) [0|0] ""  MBCU
 SG_ SBCU13_PosIso_Optical : 56|1@0+ (1,0) [0|0] ""  MBCU
 SG_ SBCU13_NegRelay_Status : 27|2@0+ (1,0) [0|0] ""  MBCU
 SG_ SBCU13_NegIso_Optical : 57|1@0+ (1,0) [0|0] ""  MBCU
 SG_ SBCU13_Life : 63|4@0+ (1,0) [0|0] ""  MBCU
 SG_ SBCU13_ISO_Status : 7|2@0+ (1,0) [0|3] ""  MBCU
 SG_ SBCU13_ISO_Allow : 5|2@0+ (1,0) [0|3] ""  MBCU
 SG_ SBCU13_HVOff_Req : 3|2@0+ (1,0) [0|0] ""  MBCU
 SG_ SBCU13_HV_Step : 15|4@0+ (1,0) [0|0] ""  MBCU
 SG_ SBCU13_HeatRelay_Status : 23|2@0+ (1,0) [0|0] ""  MBCU
 SG_ SBCU13_FcgRelay_Status : 31|2@0+ (1,0) [0|0] ""  MBCU
 SG_ SBCU13_FaultLevel : 59|2@0+ (1,0) [0|3] ""  MBCU
 SG_ SBCU13_FaultCode : 47|16@0+ (1,0) [0|65535] ""  MBCU
 SG_ SBCU13_FanRelay_Status : 21|2@0+ (1,0) [0|0] ""  MBCU
 SG_ SBCU13_DO3_Ctrl : 39|1@0+ (1,0) [0|0] ""  MBCU
 SG_ SBCU13_DO2_Ctrl : 38|1@0+ (1,0) [0|0] ""  MBCU
 SG_ SBCU13_DO1_Ctrl : 37|1@0+ (1,0) [0|0] ""  MBCU
 SG_ SBCU13_DI5_Status : 36|1@0+ (1,0) [0|0] ""  MBCU
 SG_ SBCU13_DI4_Status : 35|1@0+ (1,0) [0|0] ""  MBCU
 SG_ SBCU13_DI3_Status : 34|1@0+ (1,0) [0|0] ""  MBCU
 SG_ SBCU13_DI2_Status : 33|1@0+ (1,0) [0|0] ""  MBCU
 SG_ SBCU13_DI1_Status : 32|1@0+ (1,0) [0|0] ""  MBCU
 SG_ SBCU13_BMS_RunStatus : 19|4@0+ (1,0) [0|0] ""  MBCU

BO_ 2550505645 SBCU13_SOP_Inf2: 8 SBCU
 SG_ SBCU13_DchPeakPower_Limit : 7|16@0+ (0.1,0) [0|1000] "kW"  MBCU
 SG_ SBCU13_DchContinuousPower_Limit : 23|16@0+ (0.1,0) [0|1000] "kW"  MBCU
 SG_ SBCU13_ChgPeakPower_Limit : 39|16@0+ (0.1,0) [0|1000] "kW"  MBCU
 SG_ SBCU13_ChgContinuousPower_Limit : 55|16@0+ (0.1,0) [0|1000] "kW"  MBCU

BO_ 2550440109 SBCU13_SOP_Inf1: 8 SBCU
 SG_ SBCU13_DchPeakCurr_Limit : 7|16@0+ (0.1,0) [0|3200] "A"  MBCU
 SG_ SBCU13_DchContinuousCurr_Limit : 23|16@0+ (0.1,0) [0|3200] "A"  MBCU
 SG_ SBCU13_ChgPeakCurr_Limit : 39|16@0+ (0.1,0) [0|3200] "A"  MBCU
 SG_ SBCU13_ChgContinuousCurr_Limit : 55|16@0+ (0.1,0) [0|3200] "A"  MBCU

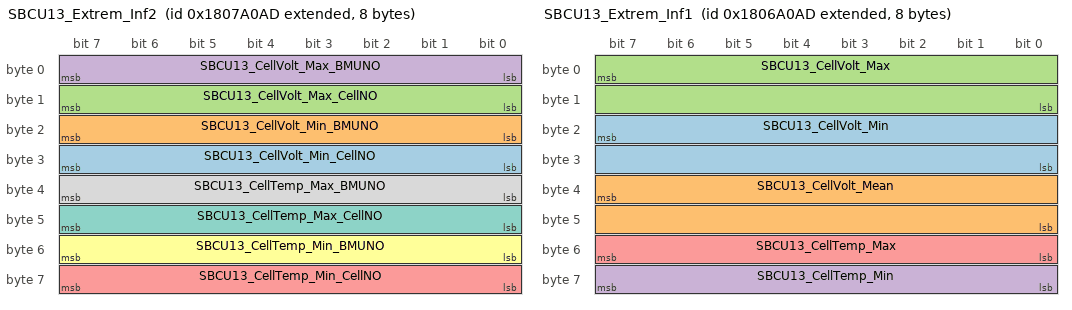
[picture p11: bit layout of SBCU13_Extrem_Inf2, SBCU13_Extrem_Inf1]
BO_ 2550636717 SBCU13_Extrem_Inf2: 8 SBCU
 SG_ SBCU13_CellVolt_Min_CellNO : 31|8@0+ (1,0) [0|255] ""  MBCU
 SG_ SBCU13_CellVolt_Min_BMUNO : 23|8@0+ (1,0) [0|16] ""  MBCU
 SG_ SBCU13_CellVolt_Max_CellNO : 15|8@0+ (1,0) [0|255] ""  MBCU
 SG_ SBCU13_CellVolt_Max_BMUNO : 7|8@0+ (1,0) [0|16] ""  MBCU
 SG_ SBCU13_CellTemp_Min_CellNO : 63|8@0+ (1,0) [0|255] ""  MBCU
 SG_ SBCU13_CellTemp_Min_BMUNO : 55|8@0+ (1,0) [0|16] ""  MBCU
 SG_ SBCU13_CellTemp_Max_CellNO : 47|8@0+ (1,0) [0|255] ""  MBCU
 SG_ SBCU13_CellTemp_Max_BMUNO : 39|8@0+ (1,0) [0|16] ""  MBCU

BO_ 2550571181 SBCU13_Extrem_Inf1: 8 SBCU
 SG_ SBCU13_CellVolt_Min : 23|16@0+ (0.001,0) [0|15] "V"  MBCU
 SG_ SBCU13_CellVolt_Mean : 39|16@0+ (0.001,0) [0|15] "V"  MBCU
 SG_ SBCU13_CellVolt_Max : 7|16@0+ (0.001,0) [0|15] "V"  MBCU
 SG_ SBCU13_CellTemp_Min : 63|8@0+ (1,-40) [0|0] "��"  MBCU
 SG_ SBCU13_CellTemp_Max : 55|8@0+ (1,-40) [0|0] "��"  MBCU

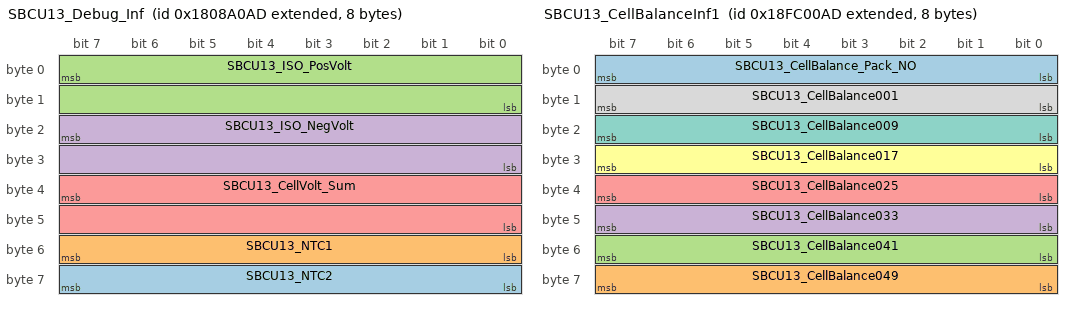
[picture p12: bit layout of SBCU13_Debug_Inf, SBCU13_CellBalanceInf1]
BO_ 2550702253 SBCU13_Debug_Inf: 8 SBCU
 SG_ SBCU13_NTC2 : 63|8@0+ (1,-40) [0|0] "��"  MBCU
 SG_ SBCU13_NTC1 : 55|8@0+ (1,-40) [0|0] "��"  MBCU
 SG_ SBCU13_ISO_PosVolt : 7|16@0+ (1,0) [0|65535] "mV"  MBCU
 SG_ SBCU13_ISO_NegVolt : 23|16@0+ (1,0) [0|65535] "mV"  MBCU
 SG_ SBCU13_CellVolt_Sum : 39|16@0+ (0.1,0) [0|0] "V"  MBCU

BO_ 2566652077 SBCU13_CellBalanceInf1: 8 SBCU
 SG_ SBCU13_CellBalance_Pack_NO : 7|8@0+ (1,0) [0|255] ""  MBCU
 SG_ SBCU13_CellBalance049 : 63|8@0+ (1,0) [0|255] ""  MBCU
 SG_ SBCU13_CellBalance041 : 55|8@0+ (1,0) [0|255] ""  MBCU
 SG_ SBCU13_CellBalance033 : 47|8@0+ (1,0) [0|255] ""  MBCU
 SG_ SBCU13_CellBalance025 : 39|8@0+ (1,0) [0|255] ""  MBCU
 SG_ SBCU13_CellBalance017 : 31|8@0+ (1,0) [0|255] ""  MBCU
 SG_ SBCU13_CellBalance009 : 23|8@0+ (1,0) [0|255] ""  MBCU
 SG_ SBCU13_CellBalance001 : 15|8@0+ (1,0) [0|255] ""  MBCU

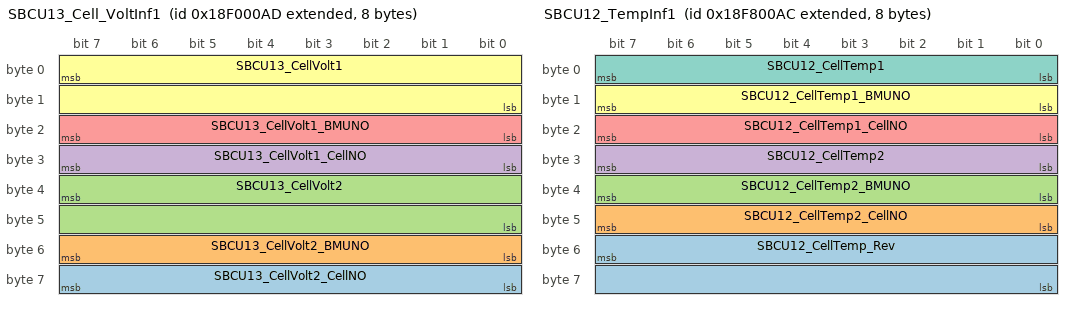
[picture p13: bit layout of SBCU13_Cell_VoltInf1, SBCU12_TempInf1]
BO_ 2565865645 SBCU13_Cell_VoltInf1: 8 SBCU
 SG_ SBCU13_CellVolt2_CellNO : 63|8@0+ (1,0) [0|0] ""  MBCU
 SG_ SBCU13_CellVolt2_BMUNO : 55|8@0+ (1,0) [0|0] ""  MBCU
 SG_ SBCU13_CellVolt2 : 39|16@0+ (0.001,0) [0|0] "V"  MBCU
 SG_ SBCU13_CellVolt1_CellNO : 31|8@0+ (1,0) [0|0] ""  MBCU
 SG_ SBCU13_CellVolt1_BMUNO : 23|8@0+ (1,0) [0|0] ""  MBCU
 SG_ SBCU13_CellVolt1 : 7|16@0+ (0.001,0) [0|0] "V"  MBCU

BO_ 2550243501 SBCU13_Basic_Inf: 8 SBCU
 SG_ SBCU13_SOC : 55|16@0+ (0.1,0) [0|100] "%"  MBCU
 SG_ SBCU13_Pack_Volt : 7|16@0+ (0.1,0) [0|2000] "V"  MBCU
 SG_ SBCU13_LinkVolt : 23|16@0+ (0.1,0) [0|2000] "V"  MBCU
 SG_ SBCU13_BusCurrent : 39|16@0+ (0.1,-3200) [0|0] "A"  MBCU

BO_ 2566389932 SBCU12_TempInf1: 8 SBCU
 SG_ SBCU12_CellTemp_Rev : 55|16@0+ (1,0) [0|65535] ""  MBCU
 SG_ SBCU12_CellTemp2_CellNO : 47|8@0+ (1,0) [0|0] ""  MBCU
 SG_ SBCU12_CellTemp2_BMUNO : 39|8@0+ (1,0) [0|0] ""  MBCU
 SG_ SBCU12_CellTemp2 : 31|8@0+ (1,-40) [0|0] "��"  MBCU
 SG_ SBCU12_CellTemp1_CellNO : 23|8@0+ (1,0) [0|0] ""  MBCU
 SG_ SBCU12_CellTemp1_BMUNO : 15|8@0+ (1,0) [0|0] ""  MBCU
 SG_ SBCU12_CellTemp1 : 7|8@0+ (1,-40) [0|0] "��"  MBCU

BO_ 2550898860 SBCU12_Statis_AccumEng: 8 SBCU
 SG_ SBCU12_Accum_DchEng : 7|32@0+ (0.1,0) [0|4000000000] "kWh"  MBCU
 SG_ SBCU12_Accum_ChgEng : 39|32@0+ (0.1,0) [0|4000000000] "kWh"  MBCU

BO_ 2550833324 SBCU12_Statis_AccumCap: 8 SBCU
 SG_ SBCU12_Accum_DchCap : 7|32@0+ (0.1,0) [0|4000000000] "Ah"  MBCU
 SG_ SBCU12_Accum_ChgCap : 39|32@0+ (0.1,0) [0|4000000000] "Ah"  MBCU

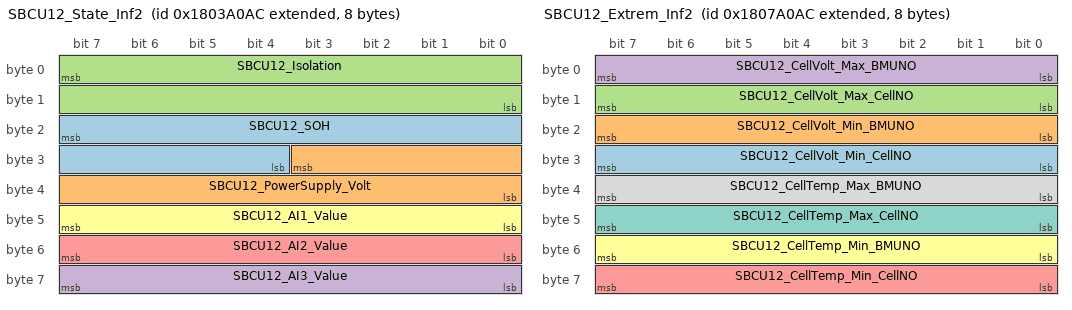
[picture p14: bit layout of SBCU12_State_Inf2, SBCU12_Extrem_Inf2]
BO_ 2550374572 SBCU12_State_Inf2: 8 SBCU
 SG_ SBCU12_SOH : 23|12@0+ (0.1,0) [0|0] "%"  MBCU
 SG_ SBCU12_PowerSupply_Volt : 27|12@0+ (0.1,0) [0|0] "V"  MBCU
 SG_ SBCU12_Isolation : 7|16@0+ (1,0) [0|65535] "kOhm"  MBCU
 SG_ SBCU12_AI3_Value : 63|8@0+ (1,0) [0|255] ""  MBCU
 SG_ SBCU12_AI2_Value : 55|8@0+ (1,0) [0|255] ""  MBCU
 SG_ SBCU12_AI1_Value : 47|8@0+ (1,0) [0|255] ""  MBCU

BO_ 2348982444 SBCU12_State_Inf1: 8 SBCU
 SG_ SBCU12_WorkMode : 11|4@0+ (1,0) [0|0] ""  MBCU
 SG_ SBCU12_Ready : 1|2@0+ (1,0) [0|0] ""  MBCU
 SG_ SBCU12_PreChgRelay_Status : 29|2@0+ (1,0) [0|0] ""  MBCU
 SG_ SBCU12_PosRelay_Status : 25|2@0+ (1,0) [0|0] ""  MBCU
 SG_ SBCU12_PosIso_Optical : 56|1@0+ (1,0) [0|0] ""  MBCU
 SG_ SBCU12_NegRelay_Status : 27|2@0+ (1,0) [0|0] ""  MBCU
 SG_ SBCU12_NegIso_Optical : 57|1@0+ (1,0) [0|0] ""  MBCU
 SG_ SBCU12_Life : 63|4@0+ (1,0) [0|0] ""  MBCU
 SG_ SBCU12_ISO_Status : 7|2@0+ (1,0) [0|3] ""  MBCU
 SG_ SBCU12_ISO_Allow : 5|2@0+ (1,0) [0|3] ""  MBCU
 SG_ SBCU12_HVOff_Req : 3|2@0+ (1,0) [0|0] ""  MBCU
 SG_ SBCU12_HV_Step : 15|4@0+ (1,0) [0|0] ""  MBCU
 SG_ SBCU12_HeatRelay_Status : 23|2@0+ (1,0) [0|0] ""  MBCU
 SG_ SBCU12_FcgRelay_Status : 31|2@0+ (1,0) [0|0] ""  MBCU
 SG_ SBCU12_FaultLevel : 59|2@0+ (1,0) [0|3] ""  MBCU
 SG_ SBCU12_FaultCode : 47|16@0+ (1,0) [0|65535] ""  MBCU
 SG_ SBCU12_FanRelay_Status : 21|2@0+ (1,0) [0|0] ""  MBCU
 SG_ SBCU12_DO3_Ctrl : 39|1@0+ (1,0) [0|0] ""  MBCU
 SG_ SBCU12_DO2_Ctrl : 38|1@0+ (1,0) [0|0] ""  MBCU
 SG_ SBCU12_DO1_Ctrl : 37|1@0+ (1,0) [0|0] ""  MBCU
 SG_ SBCU12_DI5_Status : 36|1@0+ (1,0) [0|0] ""  MBCU
 SG_ SBCU12_DI4_Status : 35|1@0+ (1,0) [0|0] ""  MBCU
 SG_ SBCU12_DI3_Status : 34|1@0+ (1,0) [0|0] ""  MBCU
 SG_ SBCU12_DI2_Status : 33|1@0+ (1,0) [0|0] ""  MBCU
 SG_ SBCU12_DI1_Status : 32|1@0+ (1,0) [0|0] ""  MBCU
 SG_ SBCU12_BMS_RunStatus : 19|4@0+ (1,0) [0|0] ""  MBCU

BO_ 2550505644 SBCU12_SOP_Inf2: 8 SBCU
 SG_ SBCU12_DchPeakPower_Limit : 7|16@0+ (0.1,0) [0|1000] "kW"  MBCU
 SG_ SBCU12_DchContinuousPower_Limit : 23|16@0+ (0.1,0) [0|1000] "kW"  MBCU
 SG_ SBCU12_ChgPeakPower_Limit : 39|16@0+ (0.1,0) [0|1000] "kW"  MBCU
 SG_ SBCU12_ChgContinuousPower_Limit : 55|16@0+ (0.1,0) [0|1000] "kW"  MBCU

BO_ 2550440108 SBCU12_SOP_Inf1: 8 SBCU
 SG_ SBCU12_DchPeakCurr_Limit : 7|16@0+ (0.1,0) [0|3200] "A"  MBCU
 SG_ SBCU12_DchContinuousCurr_Limit : 23|16@0+ (0.1,0) [0|3200] "A"  MBCU
 SG_ SBCU12_ChgPeakCurr_Limit : 39|16@0+ (0.1,0) [0|3200] "A"  MBCU
 SG_ SBCU12_ChgContinuousCurr_Limit : 55|16@0+ (0.1,0) [0|3200] "A"  MBCU

BO_ 2550636716 SBCU12_Extrem_Inf2: 8 SBCU
 SG_ SBCU12_CellVolt_Min_CellNO : 31|8@0+ (1,0) [0|255] ""  MBCU
 SG_ SBCU12_CellVolt_Min_BMUNO : 23|8@0+ (1,0) [0|16] ""  MBCU
 SG_ SBCU12_CellVolt_Max_CellNO : 15|8@0+ (1,0) [0|255] ""  MBCU
 SG_ SBCU12_CellVolt_Max_BMUNO : 7|8@0+ (1,0) [0|16] ""  MBCU
 SG_ SBCU12_CellTemp_Min_CellNO : 63|8@0+ (1,0) [0|255] ""  MBCU
 SG_ SBCU12_CellTemp_Min_BMUNO : 55|8@0+ (1,0) [0|16] ""  MBCU
 SG_ SBCU12_CellTemp_Max_CellNO : 47|8@0+ (1,0) [0|255] ""  MBCU
 SG_ SBCU12_CellTemp_Max_BMUNO : 39|8@0+ (1,0) [0|16] ""  MBCU

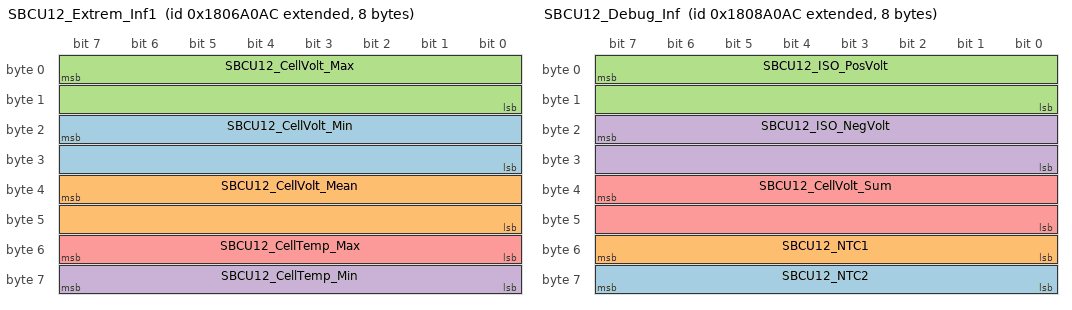
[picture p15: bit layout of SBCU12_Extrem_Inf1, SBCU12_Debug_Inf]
BO_ 2550571180 SBCU12_Extrem_Inf1: 8 SBCU
 SG_ SBCU12_CellVolt_Min : 23|16@0+ (0.001,0) [0|15] "V"  MBCU
 SG_ SBCU12_CellVolt_Mean : 39|16@0+ (0.001,0) [0|15] "V"  MBCU
 SG_ SBCU12_CellVolt_Max : 7|16@0+ (0.001,0) [0|15] "V"  MBCU
 SG_ SBCU12_CellTemp_Min : 63|8@0+ (1,-40) [0|0] "��"  MBCU
 SG_ SBCU12_CellTemp_Max : 55|8@0+ (1,-40) [0|0] "��"  MBCU

BO_ 2550702252 SBCU12_Debug_Inf: 8 SBCU
 SG_ SBCU12_NTC2 : 63|8@0+ (1,-40) [0|0] "��"  MBCU
 SG_ SBCU12_NTC1 : 55|8@0+ (1,-40) [0|0] "��"  MBCU
 SG_ SBCU12_ISO_PosVolt : 7|16@0+ (1,0) [0|65535] "mV"  MBCU
 SG_ SBCU12_ISO_NegVolt : 23|16@0+ (1,0) [0|65535] "mV"  MBCU
 SG_ SBCU12_CellVolt_Sum : 39|16@0+ (0.1,0) [0|0] "V"  MBCU

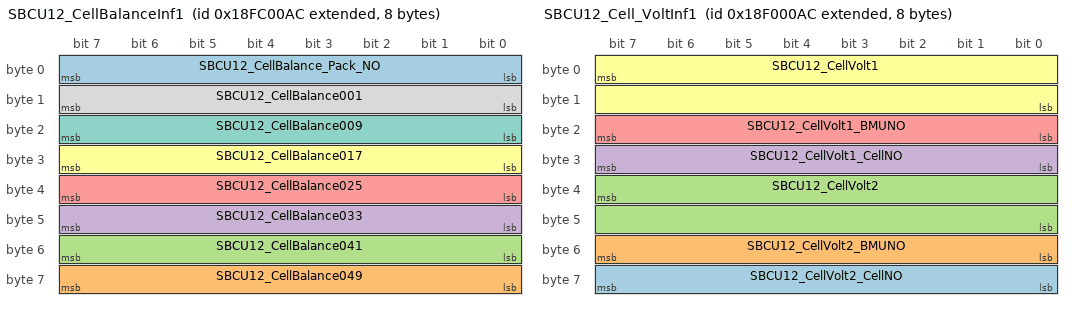
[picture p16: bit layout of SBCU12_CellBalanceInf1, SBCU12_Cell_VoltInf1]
BO_ 2566652076 SBCU12_CellBalanceInf1: 8 SBCU
 SG_ SBCU12_CellBalance_Pack_NO : 7|8@0+ (1,0) [0|255] ""  MBCU
 SG_ SBCU12_CellBalance049 : 63|8@0+ (1,0) [0|255] ""  MBCU
 SG_ SBCU12_CellBalance041 : 55|8@0+ (1,0) [0|255] ""  MBCU
 SG_ SBCU12_CellBalance033 : 47|8@0+ (1,0) [0|255] ""  MBCU
 SG_ SBCU12_CellBalance025 : 39|8@0+ (1,0) [0|255] ""  MBCU
 SG_ SBCU12_CellBalance017 : 31|8@0+ (1,0) [0|255] ""  MBCU
 SG_ SBCU12_CellBalance009 : 23|8@0+ (1,0) [0|255] ""  MBCU
 SG_ SBCU12_CellBalance001 : 15|8@0+ (1,0) [0|255] ""  MBCU

BO_ 2565865644 SBCU12_Cell_VoltInf1: 8 SBCU
 SG_ SBCU12_CellVolt2_CellNO : 63|8@0+ (1,0) [0|0] ""  MBCU
 SG_ SBCU12_CellVolt2_BMUNO : 55|8@0+ (1,0) [0|0] ""  MBCU
 SG_ SBCU12_CellVolt2 : 39|16@0+ (0.001,0) [0|0] "V"  MBCU
 SG_ SBCU12_CellVolt1_CellNO : 31|8@0+ (1,0) [0|0] ""  MBCU
 SG_ SBCU12_CellVolt1_BMUNO : 23|8@0+ (1,0) [0|0] ""  MBCU
 SG_ SBCU12_CellVolt1 : 7|16@0+ (0.001,0) [0|0] "V"  MBCU

BO_ 2550243500 SBCU12_Basic_Inf: 8 SBCU
 SG_ SBCU12_SOC : 55|16@0+ (0.1,0) [0|100] "%"  MBCU
 SG_ SBCU12_Pack_Volt : 7|16@0+ (0.1,0) [0|2000] "V"  MBCU
 SG_ SBCU12_LinkVolt : 23|16@0+ (0.1,0) [0|2000] "V"  MBCU
 SG_ SBCU12_BusCurrent : 39|16@0+ (0.1,-3200) [0|0] "A"  MBCU

BO_ 2550898859 SBCU11_Statis_AccumEng: 8 SBCU
 SG_ SBCU11_Accum_DchEng : 7|32@0+ (0.1,0) [0|4000000000] "kWh"  MBCU
 SG_ SBCU11_Accum_ChgEng : 39|32@0+ (0.1,0) [0|4000000000] "kWh"  MBCU

BO_ 2550833323 SBCU11_Statis_AccumCap: 8 SBCU
 SG_ SBCU11_Accum_DchCap : 7|32@0+ (0.1,0) [0|4000000000] "Ah"  MBCU
 SG_ SBCU11_Accum_ChgCap : 39|32@0+ (0.1,0) [0|4000000000] "Ah"  MBCU

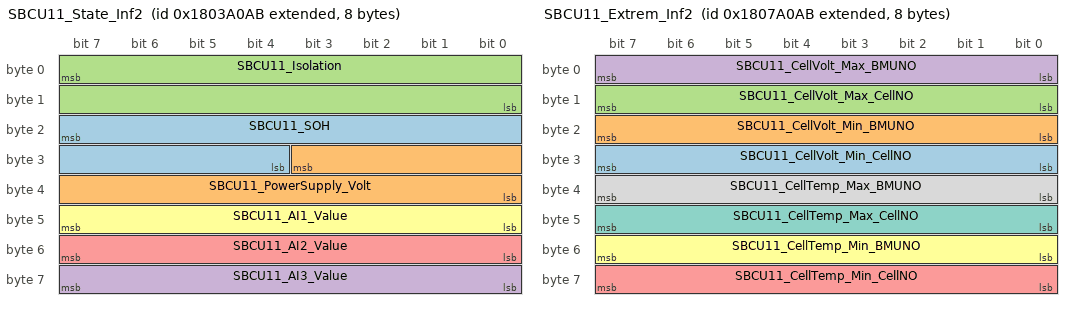
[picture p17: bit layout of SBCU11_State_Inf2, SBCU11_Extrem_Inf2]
BO_ 2550374571 SBCU11_State_Inf2: 8 SBCU
 SG_ SBCU11_SOH : 23|12@0+ (0.1,0) [0|0] "%"  MBCU
 SG_ SBCU11_PowerSupply_Volt : 27|12@0+ (0.1,0) [0|0] "V"  MBCU
 SG_ SBCU11_Isolation : 7|16@0+ (1,0) [0|65535] "kOhm"  MBCU
 SG_ SBCU11_AI3_Value : 63|8@0+ (1,0) [0|255] ""  MBCU
 SG_ SBCU11_AI2_Value : 55|8@0+ (1,0) [0|255] ""  MBCU
 SG_ SBCU11_AI1_Value : 47|8@0+ (1,0) [0|255] ""  MBCU

BO_ 2348982443 SBCU11_State_Inf1: 8 SBCU
 SG_ SBCU11_WorkMode : 11|4@0+ (1,0) [0|0] ""  MBCU
 SG_ SBCU11_Ready : 1|2@0+ (1,0) [0|0] ""  MBCU
 SG_ SBCU11_PreChgRelay_Status : 29|2@0+ (1,0) [0|0] ""  MBCU
 SG_ SBCU11_PosRelay_Status : 25|2@0+ (1,0) [0|0] ""  MBCU
 SG_ SBCU11_PosIso_Optical : 56|1@0+ (1,0) [0|0] ""  MBCU
 SG_ SBCU11_NegRelay_Status : 27|2@0+ (1,0) [0|0] ""  MBCU
 SG_ SBCU11_NegIso_Optical : 57|1@0+ (1,0) [0|0] ""  MBCU
 SG_ SBCU11_Life : 63|4@0+ (1,0) [0|0] ""  MBCU
 SG_ SBCU11_ISO_Status : 7|2@0+ (1,0) [0|3] ""  MBCU
 SG_ SBCU11_ISO_Allow : 5|2@0+ (1,0) [0|3] ""  MBCU
 SG_ SBCU11_HVOff_Req : 3|2@0+ (1,0) [0|0] ""  MBCU
 SG_ SBCU11_HV_Step : 15|4@0+ (1,0) [0|0] ""  MBCU
 SG_ SBCU11_HeatRelay_Status : 23|2@0+ (1,0) [0|0] ""  MBCU
 SG_ SBCU11_FcgRelay_Status : 31|2@0+ (1,0) [0|0] ""  MBCU
 SG_ SBCU11_FaultLevel : 59|2@0+ (1,0) [0|3] ""  MBCU
 SG_ SBCU11_FaultCode : 47|16@0+ (1,0) [0|65535] ""  MBCU
 SG_ SBCU11_FanRelay_Status : 21|2@0+ (1,0) [0|0] ""  MBCU
 SG_ SBCU11_DO3_Ctrl : 39|1@0+ (1,0) [0|0] ""  MBCU
 SG_ SBCU11_DO2_Ctrl : 38|1@0+ (1,0) [0|0] ""  MBCU
 SG_ SBCU11_DO1_Ctrl : 37|1@0+ (1,0) [0|0] ""  MBCU
 SG_ SBCU11_DI5_Status : 36|1@0+ (1,0) [0|0] ""  MBCU
 SG_ SBCU11_DI4_Status : 35|1@0+ (1,0) [0|0] ""  MBCU
 SG_ SBCU11_DI3_Status : 34|1@0+ (1,0) [0|0] ""  MBCU
 SG_ SBCU11_DI2_Status : 33|1@0+ (1,0) [0|0] ""  MBCU
 SG_ SBCU11_DI1_Status : 32|1@0+ (1,0) [0|0] ""  MBCU
 SG_ SBCU11_BMS_RunStatus : 19|4@0+ (1,0) [0|0] ""  MBCU

BO_ 2550505643 SBCU11_SOP_Inf2: 8 SBCU
 SG_ SBCU11_DchPeakPower_Limit : 7|16@0+ (0.1,0) [0|1000] "kW"  MBCU
 SG_ SBCU11_DchContinuousPower_Limit : 23|16@0+ (0.1,0) [0|1000] "kW"  MBCU
 SG_ SBCU11_ChgPeakPower_Limit : 39|16@0+ (0.1,0) [0|1000] "kW"  MBCU
 SG_ SBCU11_ChgContinuousPower_Limit : 55|16@0+ (0.1,0) [0|1000] "kW"  MBCU

BO_ 2550440107 SBCU11_SOP_Inf1: 8 SBCU
 SG_ SBCU11_DchPeakCurr_Limit : 7|16@0+ (0.1,0) [0|3200] "A"  MBCU
 SG_ SBCU11_DchContinuousCurr_Limit : 23|16@0+ (0.1,0) [0|3200] "A"  MBCU
 SG_ SBCU11_ChgPeakCurr_Limit : 39|16@0+ (0.1,0) [0|3200] "A"  MBCU
 SG_ SBCU11_ChgContinuousCurr_Limit : 55|16@0+ (0.1,0) [0|3200] "A"  MBCU

BO_ 2550636715 SBCU11_Extrem_Inf2: 8 SBCU
 SG_ SBCU11_CellVolt_Min_CellNO : 31|8@0+ (1,0) [0|255] ""  MBCU
 SG_ SBCU11_CellVolt_Min_BMUNO : 23|8@0+ (1,0) [0|16] ""  MBCU
 SG_ SBCU11_CellVolt_Max_CellNO : 15|8@0+ (1,0) [0|255] ""  MBCU
 SG_ SBCU11_CellVolt_Max_BMUNO : 7|8@0+ (1,0) [0|16] ""  MBCU
 SG_ SBCU11_CellTemp_Min_CellNO : 63|8@0+ (1,0) [0|255] ""  MBCU
 SG_ SBCU11_CellTemp_Min_BMUNO : 55|8@0+ (1,0) [0|16] ""  MBCU
 SG_ SBCU11_CellTemp_Max_CellNO : 47|8@0+ (1,0) [0|255] ""  MBCU
 SG_ SBCU11_CellTemp_Max_BMUNO : 39|8@0+ (1,0) [0|16] ""  MBCU

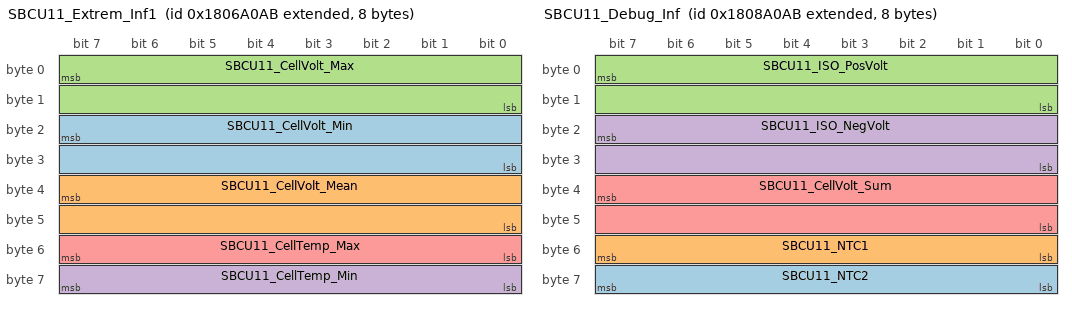
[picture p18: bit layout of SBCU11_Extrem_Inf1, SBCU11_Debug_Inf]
BO_ 2550571179 SBCU11_Extrem_Inf1: 8 SBCU
 SG_ SBCU11_CellVolt_Min : 23|16@0+ (0.001,0) [0|15] "V"  MBCU
 SG_ SBCU11_CellVolt_Mean : 39|16@0+ (0.001,0) [0|15] "V"  MBCU
 SG_ SBCU11_CellVolt_Max : 7|16@0+ (0.001,0) [0|15] "V"  MBCU
 SG_ SBCU11_CellTemp_Min : 63|8@0+ (1,-40) [0|0] "��"  MBCU
 SG_ SBCU11_CellTemp_Max : 55|8@0+ (1,-40) [0|0] "��"  MBCU

BO_ 2550702251 SBCU11_Debug_Inf: 8 SBCU
 SG_ SBCU11_NTC2 : 63|8@0+ (1,-40) [0|0] "��"  MBCU
 SG_ SBCU11_NTC1 : 55|8@0+ (1,-40) [0|0] "��"  MBCU
 SG_ SBCU11_ISO_PosVolt : 7|16@0+ (1,0) [0|65535] "mV"  MBCU
 SG_ SBCU11_ISO_NegVolt : 23|16@0+ (1,0) [0|65535] "mV"  MBCU
 SG_ SBCU11_CellVolt_Sum : 39|16@0+ (0.1,0) [0|0] "V"  MBCU

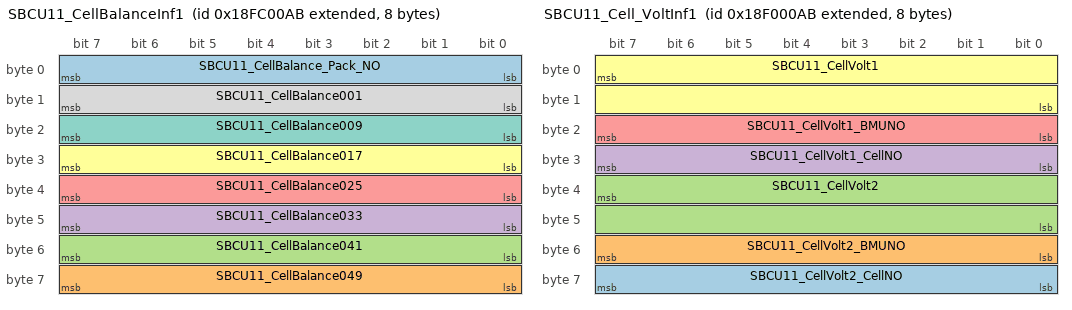
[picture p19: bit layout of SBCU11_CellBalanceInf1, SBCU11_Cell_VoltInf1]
BO_ 2566652075 SBCU11_CellBalanceInf1: 8 SBCU
 SG_ SBCU11_CellBalance_Pack_NO : 7|8@0+ (1,0) [0|255] ""  MBCU
 SG_ SBCU11_CellBalance049 : 63|8@0+ (1,0) [0|255] ""  MBCU
 SG_ SBCU11_CellBalance041 : 55|8@0+ (1,0) [0|255] ""  MBCU
 SG_ SBCU11_CellBalance033 : 47|8@0+ (1,0) [0|255] ""  MBCU
 SG_ SBCU11_CellBalance025 : 39|8@0+ (1,0) [0|255] ""  MBCU
 SG_ SBCU11_CellBalance017 : 31|8@0+ (1,0) [0|255] ""  MBCU
 SG_ SBCU11_CellBalance009 : 23|8@0+ (1,0) [0|255] ""  MBCU
 SG_ SBCU11_CellBalance001 : 15|8@0+ (1,0) [0|255] ""  MBCU

BO_ 2565865643 SBCU11_Cell_VoltInf1: 8 SBCU
 SG_ SBCU11_CellVolt2_CellNO : 63|8@0+ (1,0) [0|0] ""  MBCU
 SG_ SBCU11_CellVolt2_BMUNO : 55|8@0+ (1,0) [0|0] ""  MBCU
 SG_ SBCU11_CellVolt2 : 39|16@0+ (0.001,0) [0|0] "V"  MBCU
 SG_ SBCU11_CellVolt1_CellNO : 31|8@0+ (1,0) [0|0] ""  MBCU
 SG_ SBCU11_CellVolt1_BMUNO : 23|8@0+ (1,0) [0|0] ""  MBCU
 SG_ SBCU11_CellVolt1 : 7|16@0+ (0.001,0) [0|0] "V"  MBCU

BO_ 2550243499 SBCU11_Basic_Inf: 8 SBCU
 SG_ SBCU11_SOC : 55|16@0+ (0.1,0) [0|100] "%"  MBCU
 SG_ SBCU11_Pack_Volt : 7|16@0+ (0.1,0) [0|2000] "V"  MBCU
 SG_ SBCU11_LinkVolt : 23|16@0+ (0.1,0) [0|2000] "V"  MBCU
 SG_ SBCU11_BusCurrent : 39|16@0+ (0.1,-3200) [0|0] "A"  MBCU

CM_ SG_ 2551357601 SBCU1_Reports_Set_Status "SBCU��������״̬ 0-���óɹ���1-����ʧ�ܡ�";
CM_ SG_ 2551357601 SBCU1_Confirms_Faultcode "SBCUȷ�ϵ�ǰ���ù����� �����ϲ�������ʱ�ظ���Ӧ�����룬�����궨���ͻظ�0";
CM_ BO_ 6 "��CAN�궨";
CM_ SG_ 6 Calib_ParaContent2 "�궨����2";
CM_ SG_ 6 Calib_ParaContent1 "�궨����1";
CM_ SG_ 6 Calib_Type "�궨����";
CM_ SG_ 6 Calib_SBCU_ID "SBCU ID��0��ʼ��";
CM_ SG_ 6 Calib_Msg_Count "������Ч����";
CM_ SG_ 6 Calib_Msg_Index "��������";
CM_ SG_ 2551292079 SBCU15_ReleaseVersion "SBCU�����汾��Ϣ �������汾��+��������ţ�ʹ�����ͱ�ʾ�����磺V106��ʾΪ106�������B.C.000012345������Ϊ10612345";
CM_ SG_ 2551292065 SBCU1_BMU_ReleaseVersion "BMU�����汾��Ϣ �Ӱ�����������ţ�ʹ�����ͱ�ʾ�����磺�����B.C.000012345������Ϊ12345";
CM_ SG_ 2551292065 SBCU1_BMU_Index "BMU��� ����0-25��Ӧbmu1-26��������Ч";
CM_ SG_ 2551292065 SBCU1_ReleaseVersion "SBCU�����汾��Ϣ �������汾��+��������ţ�ʹ�����ͱ�ʾ�����磺V106��ʾΪ106�������B.C.000012345������Ϊ10612345";
CM_ SG_ 511 Tester_Silence_Crc_ExtCAN "Crc = Byte0^Byte1^Byte2^Byte3^Byte4^Byte5^Byte6";
CM_ SG_ 511 Tester_Silence_Cmd1_ExtCAN "Ŀ��ˢдID����Ŀ��ID�⣬����SBCU����ֹ�������Ϸ��ͱ��ģ��� ֵOxFFʱ������ID�˳���Ĭģʽ";
CM_ SG_ 2551226529 SBCU1_CutOff_Relay_Pack_Volt "����·�̵����ж�ʱ��pack��ѹ";
CM_ SG_ 2551226529 SBCU1_CutOff_Relay_Current "����·�̵����ж�ʱ�ĵ���";
CM_ SG_ 2550767777 SBCU1_BMU_FaultID "BMU����ID ����0-25��Ӧbmu1-26��������Ч";
CM_ SG_ 2550767777 SBCU1_CellTemp_Mean "��ش�ƽ���¶�";
CM_ SG_ 2550767777 SBCU1_Real_SOH "��ʵ��SOH��";
CM_ SG_ 2550767777 SBCU1_Real_SOC "��ʵ��SOC��";
BA_DEF_ SG_  "GenSigStartValue" FLOAT 0 1215752192;
BA_DEF_ SG_  "GenSigMaxValue" INT 0 2147483647;
BA_DEF_ SG_  "GenSigSendType" ENUM  "NoMsgSendType","NoSigSendType","Cyclic";
BA_DEF_ SG_  "GenSigEnvVarType" ENUM  "int","float","undef";
BA_DEF_ BO_  "GenMsgCycleTime" INT 0 65535;
BA_DEF_ BO_  "VFrameFormat" ENUM  "StandardCAN","ExtendedCAN","reserved","J1939PG","reserved","reserved","reserved","reserved","reserved","reserved","reserved","reserved","reserved","reserved","StandardCAN_FD","ExtendedCAN_FD";
BA_DEF_ BO_  "GenMsgSendType" ENUM  "NoMsgSendType","NoSigSendType","Cyclic";
BA_DEF_  "BusType" STRING ;
BA_DEF_  "GenEnvVarPrefix" STRING ;
BA_DEF_  "GenEnvVarEndingSnd" STRING ;
BA_DEF_  "GenEnvVarEndingDsp" STRING ;
BA_DEF_  "DBName" STRING ;
BA_DEF_DEF_  "GenSigStartValue" 0;
BA_DEF_DEF_  "GenSigMaxValue" 0;
BA_DEF_DEF_  "GenSigSendType" "NoMsgSendType";
BA_DEF_DEF_  "GenSigEnvVarType" "undef";
BA_DEF_DEF_  "GenMsgCycleTime" 0;
BA_DEF_DEF_  "VFrameFormat" "StandardCAN";
BA_DEF_DEF_  "GenMsgSendType" "NoMsgSendType";
BA_DEF_DEF_  "BusType" "CAN";
BA_DEF_DEF_  "GenEnvVarPrefix" "PE";
BA_DEF_DEF_  "GenEnvVarEndingSnd" "_Ps";
BA_DEF_DEF_  "GenEnvVarEndingDsp" "_Pd";
BA_DEF_DEF_  "DBName" "";
BA_ "DBName" "CanMatrix";
BA_ "VFrameFormat" BO_ 2551357615 1;
BA_ "VFrameFormat" BO_ 2551357614 1;
BA_ "VFrameFormat" BO_ 2551357613 1;
BA_ "VFrameFormat" BO_ 2551357612 1;
BA_ "VFrameFormat" BO_ 2551357611 1;
BA_ "VFrameFormat" BO_ 2551357610 1;
BA_ "VFrameFormat" BO_ 2551357609 1;
BA_ "VFrameFormat" BO_ 2551357608 1;
BA_ "VFrameFormat" BO_ 2551357607 1;
BA_ "VFrameFormat" BO_ 2551357606 1;
BA_ "VFrameFormat" BO_ 2551357605 1;
BA_ "VFrameFormat" BO_ 2551357604 1;
BA_ "VFrameFormat" BO_ 2551357603 1;
BA_ "VFrameFormat" BO_ 2551357602 1;
BA_ "VFrameFormat" BO_ 2551357601 1;
BA_ "GenMsgSendType" BO_ 2551292079 2;
BA_ "GenMsgCycleTime" BO_ 2551292079 1000;
BA_ "VFrameFormat" BO_ 2551292079 1;
BA_ "GenMsgSendType" BO_ 2551292078 2;
BA_ "GenMsgCycleTime" BO_ 2551292078 1000;
BA_ "VFrameFormat" BO_ 2551292078 1;
BA_ "GenMsgSendType" BO_ 2551292077 2;
BA_ "GenMsgCycleTime" BO_ 2551292077 1000;
BA_ "VFrameFormat" BO_ 2551292077 1;
BA_ "GenMsgSendType" BO_ 2551292076 2;
BA_ "GenMsgCycleTime" BO_ 2551292076 1000;
BA_ "VFrameFormat" BO_ 2551292076 1;
BA_ "GenMsgSendType" BO_ 2551292075 2;
BA_ "GenMsgCycleTime" BO_ 2551292075 1000;
BA_ "VFrameFormat" BO_ 2551292075 1;
BA_ "GenMsgSendType" BO_ 2551292074 2;
BA_ "GenMsgCycleTime" BO_ 2551292074 1000;
BA_ "VFrameFormat" BO_ 2551292074 1;
BA_ "GenMsgSendType" BO_ 2551292073 2;
BA_ "GenMsgCycleTime" BO_ 2551292073 1000;
BA_ "VFrameFormat" BO_ 2551292073 1;
BA_ "GenMsgSendType" BO_ 2551292072 2;
BA_ "GenMsgCycleTime" BO_ 2551292072 1000;
BA_ "VFrameFormat" BO_ 2551292072 1;
BA_ "GenMsgSendType" BO_ 2551292071 2;
BA_ "GenMsgCycleTime" BO_ 2551292071 1000;
BA_ "VFrameFormat" BO_ 2551292071 1;
BA_ "GenMsgSendType" BO_ 2551292070 2;
BA_ "GenMsgCycleTime" BO_ 2551292070 1000;
BA_ "VFrameFormat" BO_ 2551292070 1;
BA_ "GenMsgSendType" BO_ 2551292069 2;
BA_ "GenMsgCycleTime" BO_ 2551292069 1000;
BA_ "VFrameFormat" BO_ 2551292069 1;
BA_ "GenMsgSendType" BO_ 2551292068 2;
BA_ "GenMsgCycleTime" BO_ 2551292068 1000;
BA_ "VFrameFormat" BO_ 2551292068 1;
BA_ "GenMsgSendType" BO_ 2551292067 2;
BA_ "GenMsgCycleTime" BO_ 2551292067 1000;
BA_ "VFrameFormat" BO_ 2551292067 1;
BA_ "GenMsgSendType" BO_ 2551292066 2;
BA_ "GenMsgCycleTime" BO_ 2551292066 1000;
BA_ "VFrameFormat" BO_ 2551292066 1;
BA_ "GenMsgSendType" BO_ 2551292065 2;
BA_ "GenMsgCycleTime" BO_ 2551292065 1000;
BA_ "VFrameFormat" BO_ 2551292065 1;
BA_ "VFrameFormat" BO_ 2551226543 1;
BA_ "GenMsgSendType" BO_ 2550767791 2;
BA_ "GenMsgCycleTime" BO_ 2550767791 100;
BA_ "VFrameFormat" BO_ 2550767791 1;
BA_ "VFrameFormat" BO_ 2551226542 1;
BA_ "GenMsgSendType" BO_ 2550767790 2;
BA_ "GenMsgCycleTime" BO_ 2550767790 100;
BA_ "VFrameFormat" BO_ 2550767790 1;
BA_ "VFrameFormat" BO_ 2551226541 1;
BA_ "GenMsgSendType" BO_ 2550767789 2;
BA_ "GenMsgCycleTime" BO_ 2550767789 100;
BA_ "VFrameFormat" BO_ 2550767789 1;
BA_ "VFrameFormat" BO_ 2551226540 1;
BA_ "GenMsgSendType" BO_ 2550767788 2;
BA_ "GenMsgCycleTime" BO_ 2550767788 100;
BA_ "VFrameFormat" BO_ 2550767788 1;
BA_ "VFrameFormat" BO_ 2551226539 1;
BA_ "GenMsgSendType" BO_ 2550767787 2;
BA_ "GenMsgCycleTime" BO_ 2550767787 100;
BA_ "VFrameFormat" BO_ 2550767787 1;
BA_ "VFrameFormat" BO_ 2551226538 1;
BA_ "GenMsgSendType" BO_ 2550767786 2;
BA_ "GenMsgCycleTime" BO_ 2550767786 100;
BA_ "VFrameFormat" BO_ 2550767786 1;
BA_ "VFrameFormat" BO_ 2551226537 1;
BA_ "GenMsgSendType" BO_ 2550767785 2;
BA_ "GenMsgCycleTime" BO_ 2550767785 100;
BA_ "VFrameFormat" BO_ 2550767785 1;
BA_ "VFrameFormat" BO_ 2551226536 1;
BA_ "GenMsgSendType" BO_ 2550767784 2;
BA_ "GenMsgCycleTime" BO_ 2550767784 100;
BA_ "VFrameFormat" BO_ 2550767784 1;
BA_ "VFrameFormat" BO_ 2551226535 1;
BA_ "GenMsgSendType" BO_ 2550767783 2;
BA_ "GenMsgCycleTime" BO_ 2550767783 100;
BA_ "VFrameFormat" BO_ 2550767783 1;
BA_ "VFrameFormat" BO_ 2551226534 1;
BA_ "GenMsgSendType" BO_ 2550767782 2;
BA_ "GenMsgCycleTime" BO_ 2550767782 100;
BA_ "VFrameFormat" BO_ 2550767782 1;
BA_ "VFrameFormat" BO_ 2551226533 1;
BA_ "GenMsgSendType" BO_ 2550767781 2;
BA_ "GenMsgCycleTime" BO_ 2550767781 100;
BA_ "VFrameFormat" BO_ 2550767781 1;
BA_ "VFrameFormat" BO_ 2551226532 1;
BA_ "GenMsgSendType" BO_ 2550767780 2;
BA_ "GenMsgCycleTime" BO_ 2550767780 100;
BA_ "VFrameFormat" BO_ 2550767780 1;
BA_ "VFrameFormat" BO_ 2551226531 1;
BA_ "GenMsgSendType" BO_ 2550767779 2;
BA_ "GenMsgCycleTime" BO_ 2550767779 100;
BA_ "VFrameFormat" BO_ 2550767779 1;
BA_ "VFrameFormat" BO_ 2551226530 1;
BA_ "GenMsgSendType" BO_ 2550767778 2;
BA_ "GenMsgCycleTime" BO_ 2550767778 100;
BA_ "VFrameFormat" BO_ 2550767778 1;
BA_ "VFrameFormat" BO_ 2551226529 1;
BA_ "GenMsgSendType" BO_ 2550767777 2;
BA_ "GenMsgCycleTime" BO_ 2550767777 100;
BA_ "VFrameFormat" BO_ 2550767777 1;
BA_ "GenMsgSendType" BO_ 2566389935 2;
BA_ "GenMsgCycleTime" BO_ 2566389935 50;
BA_ "VFrameFormat" BO_ 2566389935 1;
BA_ "GenMsgSendType" BO_ 2550898863 2;
BA_ "GenMsgCycleTime" BO_ 2550898863 10000;
BA_ "VFrameFormat" BO_ 2550898863 1;
BA_ "GenMsgSendType" BO_ 2550833327 2;
BA_ "GenMsgCycleTime" BO_ 2550833327 10000;
BA_ "VFrameFormat" BO_ 2550833327 1;
BA_ "GenMsgSendType" BO_ 2550374575 2;
BA_ "GenMsgCycleTime" BO_ 2550374575 200;
BA_ "VFrameFormat" BO_ 2550374575 1;
BA_ "GenMsgSendType" BO_ 2348982447 2;
BA_ "GenMsgCycleTime" BO_ 2348982447 100;
BA_ "VFrameFormat" BO_ 2348982447 1;
BA_ "GenMsgSendType" BO_ 2550505647 2;
BA_ "GenMsgCycleTime" BO_ 2550505647 100;
BA_ "VFrameFormat" BO_ 2550505647 1;
BA_ "GenMsgSendType" BO_ 2550440111 2;
BA_ "GenMsgCycleTime" BO_ 2550440111 100;
BA_ "VFrameFormat" BO_ 2550440111 1;
BA_ "GenMsgSendType" BO_ 2550636719 2;
BA_ "GenMsgCycleTime" BO_ 2550636719 200;
BA_ "VFrameFormat" BO_ 2550636719 1;
BA_ "GenMsgSendType" BO_ 2550571183 2;
BA_ "GenMsgCycleTime" BO_ 2550571183 200;
BA_ "VFrameFormat" BO_ 2550571183 1;
BA_ "GenMsgSendType" BO_ 2550702255 2;
BA_ "GenMsgCycleTime" BO_ 2550702255 1000;
BA_ "VFrameFormat" BO_ 2550702255 1;
BA_ "GenMsgSendType" BO_ 2566652079 2;
BA_ "GenMsgCycleTime" BO_ 2566652079 1000;
BA_ "VFrameFormat" BO_ 2566652079 1;
BA_ "GenMsgSendType" BO_ 2565865647 2;
BA_ "GenMsgCycleTime" BO_ 2565865647 50;
BA_ "VFrameFormat" BO_ 2565865647 1;
BA_ "GenMsgSendType" BO_ 2550243503 2;
BA_ "GenMsgCycleTime" BO_ 2550243503 50;
BA_ "VFrameFormat" BO_ 2550243503 1;
BA_ "GenMsgSendType" BO_ 2566389934 2;
BA_ "GenMsgCycleTime" BO_ 2566389934 50;
BA_ "VFrameFormat" BO_ 2566389934 1;
BA_ "GenMsgSendType" BO_ 2550898862 2;
BA_ "GenMsgCycleTime" BO_ 2550898862 10000;
BA_ "VFrameFormat" BO_ 2550898862 1;
BA_ "GenMsgSendType" BO_ 2550833326 2;
BA_ "GenMsgCycleTime" BO_ 2550833326 10000;
BA_ "VFrameFormat" BO_ 2550833326 1;
BA_ "GenMsgSendType" BO_ 2550374574 2;
BA_ "GenMsgCycleTime" BO_ 2550374574 200;
BA_ "VFrameFormat" BO_ 2550374574 1;
BA_ "GenMsgSendType" BO_ 2348982446 2;
BA_ "GenMsgCycleTime" BO_ 2348982446 100;
BA_ "VFrameFormat" BO_ 2348982446 1;
BA_ "GenMsgSendType" BO_ 2550505646 2;
BA_ "GenMsgCycleTime" BO_ 2550505646 100;
BA_ "VFrameFormat" BO_ 2550505646 1;
BA_ "GenMsgSendType" BO_ 2550440110 2;
BA_ "GenMsgCycleTime" BO_ 2550440110 100;
BA_ "VFrameFormat" BO_ 2550440110 1;
BA_ "GenMsgSendType" BO_ 2550636718 2;
BA_ "GenMsgCycleTime" BO_ 2550636718 200;
BA_ "VFrameFormat" BO_ 2550636718 1;
BA_ "GenMsgSendType" BO_ 2550571182 2;
BA_ "GenMsgCycleTime" BO_ 2550571182 200;
BA_ "VFrameFormat" BO_ 2550571182 1;
BA_ "GenMsgSendType" BO_ 2550702254 2;
BA_ "GenMsgCycleTime" BO_ 2550702254 1000;
BA_ "VFrameFormat" BO_ 2550702254 1;
BA_ "GenMsgSendType" BO_ 2566652078 2;
BA_ "GenMsgCycleTime" BO_ 2566652078 1000;
BA_ "VFrameFormat" BO_ 2566652078 1;
BA_ "GenMsgSendType" BO_ 2565865646 2;
BA_ "GenMsgCycleTime" BO_ 2565865646 50;
BA_ "VFrameFormat" BO_ 2565865646 1;
BA_ "GenMsgSendType" BO_ 2550243502 2;
BA_ "GenMsgCycleTime" BO_ 2550243502 50;
BA_ "VFrameFormat" BO_ 2550243502 1;
BA_ "GenMsgSendType" BO_ 2566389933 2;
BA_ "GenMsgCycleTime" BO_ 2566389933 50;
BA_ "VFrameFormat" BO_ 2566389933 1;
BA_ "GenMsgSendType" BO_ 2550898861 2;
BA_ "GenMsgCycleTime" BO_ 2550898861 10000;
BA_ "VFrameFormat" BO_ 2550898861 1;
BA_ "GenMsgSendType" BO_ 2550833325 2;
BA_ "GenMsgCycleTime" BO_ 2550833325 10000;
BA_ "VFrameFormat" BO_ 2550833325 1;
BA_ "GenMsgSendType" BO_ 2550374573 2;
BA_ "GenMsgCycleTime" BO_ 2550374573 200;
BA_ "VFrameFormat" BO_ 2550374573 1;
BA_ "GenMsgSendType" BO_ 2348982445 2;
BA_ "GenMsgCycleTime" BO_ 2348982445 100;
BA_ "VFrameFormat" BO_ 2348982445 1;
BA_ "GenMsgSendType" BO_ 2550505645 2;
BA_ "GenMsgCycleTime" BO_ 2550505645 100;
BA_ "VFrameFormat" BO_ 2550505645 1;
BA_ "GenMsgSendType" BO_ 2550440109 2;
BA_ "GenMsgCycleTime" BO_ 2550440109 100;
BA_ "VFrameFormat" BO_ 2550440109 1;
BA_ "GenMsgSendType" BO_ 2550636717 2;
BA_ "GenMsgCycleTime" BO_ 2550636717 200;
BA_ "VFrameFormat" BO_ 2550636717 1;
BA_ "GenMsgSendType" BO_ 2550571181 2;
BA_ "GenMsgCycleTime" BO_ 2550571181 200;
BA_ "VFrameFormat" BO_ 2550571181 1;
BA_ "GenMsgSendType" BO_ 2550702253 2;
BA_ "GenMsgCycleTime" BO_ 2550702253 1000;
BA_ "VFrameFormat" BO_ 2550702253 1;
BA_ "GenMsgSendType" BO_ 2566652077 2;
BA_ "GenMsgCycleTime" BO_ 2566652077 1000;
BA_ "VFrameFormat" BO_ 2566652077 1;
BA_ "GenMsgSendType" BO_ 2565865645 2;
BA_ "GenMsgCycleTime" BO_ 2565865645 50;
BA_ "VFrameFormat" BO_ 2565865645 1;
BA_ "GenMsgSendType" BO_ 2550243501 2;
BA_ "GenMsgCycleTime" BO_ 2550243501 50;
BA_ "VFrameFormat" BO_ 2550243501 1;
BA_ "GenMsgSendType" BO_ 2566389932 2;
BA_ "GenMsgCycleTime" BO_ 2566389932 50;
BA_ "VFrameFormat" BO_ 2566389932 1;
BA_ "GenMsgSendType" BO_ 2550898860 2;
BA_ "GenMsgCycleTime" BO_ 2550898860 10000;
BA_ "VFrameFormat" BO_ 2550898860 1;
BA_ "GenMsgSendType" BO_ 2550833324 2;
BA_ "GenMsgCycleTime" BO_ 2550833324 10000;
BA_ "VFrameFormat" BO_ 2550833324 1;
BA_ "GenMsgSendType" BO_ 2550374572 2;
BA_ "GenMsgCycleTime" BO_ 2550374572 200;
BA_ "VFrameFormat" BO_ 2550374572 1;
BA_ "GenMsgSendType" BO_ 2348982444 2;
BA_ "GenMsgCycleTime" BO_ 2348982444 100;
BA_ "VFrameFormat" BO_ 2348982444 1;
BA_ "GenMsgSendType" BO_ 2550505644 2;
BA_ "GenMsgCycleTime" BO_ 2550505644 100;
BA_ "VFrameFormat" BO_ 2550505644 1;
BA_ "GenMsgSendType" BO_ 2550440108 2;
BA_ "GenMsgCycleTime" BO_ 2550440108 100;
BA_ "VFrameFormat" BO_ 2550440108 1;
BA_ "GenMsgSendType" BO_ 2550636716 2;
BA_ "GenMsgCycleTime" BO_ 2550636716 200;
BA_ "VFrameFormat" BO_ 2550636716 1;
BA_ "GenMsgSendType" BO_ 2550571180 2;
BA_ "GenMsgCycleTime" BO_ 2550571180 200;
BA_ "VFrameFormat" BO_ 2550571180 1;
BA_ "GenMsgSendType" BO_ 2550702252 2;
BA_ "GenMsgCycleTime" BO_ 2550702252 1000;
BA_ "VFrameFormat" BO_ 2550702252 1;
BA_ "GenMsgSendType" BO_ 2566652076 2;
BA_ "GenMsgCycleTime" BO_ 2566652076 1000;
BA_ "VFrameFormat" BO_ 2566652076 1;
BA_ "GenMsgSendType" BO_ 2565865644 2;
BA_ "GenMsgCycleTime" BO_ 2565865644 50;
BA_ "VFrameFormat" BO_ 2565865644 1;
BA_ "GenMsgSendType" BO_ 2550243500 2;
BA_ "GenMsgCycleTime" BO_ 2550243500 50;
BA_ "VFrameFormat" BO_ 2550243500 1;
BA_ "GenMsgSendType" BO_ 2550898859 2;
BA_ "GenMsgCycleTime" BO_ 2550898859 10000;
BA_ "VFrameFormat" BO_ 2550898859 1;
BA_ "GenMsgSendType" BO_ 2550833323 2;
BA_ "GenMsgCycleTime" BO_ 2550833323 10000;
BA_ "VFrameFormat" BO_ 2550833323 1;
BA_ "GenMsgSendType" BO_ 2550374571 2;
BA_ "GenMsgCycleTime" BO_ 2550374571 200;
BA_ "VFrameFormat" BO_ 2550374571 1;
BA_ "GenMsgSendType" BO_ 2348982443 2;
BA_ "GenMsgCycleTime" BO_ 2348982443 100;
BA_ "VFrameFormat" BO_ 2348982443 1;
BA_ "GenMsgSendType" BO_ 2550505643 2;
BA_ "GenMsgCycleTime" BO_ 2550505643 100;
BA_ "VFrameFormat" BO_ 2550505643 1;
BA_ "GenMsgSendType" BO_ 2550440107 2;
BA_ "GenMsgCycleTime" BO_ 2550440107 100;
BA_ "VFrameFormat" BO_ 2550440107 1;
BA_ "GenMsgSendType" BO_ 2550636715 2;
BA_ "GenMsgCycleTime" BO_ 2550636715 200;
BA_ "VFrameFormat" BO_ 2550636715 1;
BA_ "GenMsgSendType" BO_ 2550571179 2;
BA_ "GenMsgCycleTime" BO_ 2550571179 200;
BA_ "VFrameFormat" BO_ 2550571179 1;
BA_ "GenMsgSendType" BO_ 2550702251 2;
BA_ "GenMsgCycleTime" BO_ 2550702251 1000;
BA_ "VFrameFormat" BO_ 2550702251 1;
BA_ "GenMsgSendType" BO_ 2566652075 2;
BA_ "GenMsgCycleTime" BO_ 2566652075 1000;
BA_ "VFrameFormat" BO_ 2566652075 1;
BA_ "GenMsgSendType" BO_ 2565865643 2;
BA_ "GenMsgCycleTime" BO_ 2565865643 50;
BA_ "VFrameFormat" BO_ 2565865643 1;
BA_ "GenMsgSendType" BO_ 2550243499 2;
BA_ "GenMsgCycleTime" BO_ 2550243499 50;
BA_ "VFrameFormat" BO_ 2550243499 1;
BA_ "GenSigSendType" SG_ 2551357615 SBCU15_Reports_Set_Status 1;
BA_ "GenSigMaxValue" SG_ 2551357615 SBCU15_Reports_Set_Status 7;
BA_ "GenSigSendType" SG_ 2551357615 SBCU15_Confirms_Faultcode 1;
BA_ "GenSigMaxValue" SG_ 2551357615 SBCU15_Confirms_Faultcode 65535;
BA_ "GenSigSendType" SG_ 2551357614 SBCU14_Reports_Set_Status 1;
BA_ "GenSigMaxValue" SG_ 2551357614 SBCU14_Reports_Set_Status 7;
BA_ "GenSigSendType" SG_ 2551357614 SBCU14_Confirms_Faultcode 1;
BA_ "GenSigMaxValue" SG_ 2551357614 SBCU14_Confirms_Faultcode 65535;
BA_ "GenSigSendType" SG_ 2551357613 SBCU13_Reports_Set_Status 1;
BA_ "GenSigMaxValue" SG_ 2551357613 SBCU13_Reports_Set_Status 7;
BA_ "GenSigSendType" SG_ 2551357613 SBCU13_Confirms_Faultcode 1;
BA_ "GenSigMaxValue" SG_ 2551357613 SBCU13_Confirms_Faultcode 65535;
BA_ "GenSigSendType" SG_ 2551357612 SBCU12_Reports_Set_Status 1;
BA_ "GenSigMaxValue" SG_ 2551357612 SBCU12_Reports_Set_Status 7;
BA_ "GenSigSendType" SG_ 2551357612 SBCU12_Confirms_Faultcode 1;
BA_ "GenSigMaxValue" SG_ 2551357612 SBCU12_Confirms_Faultcode 65535;
BA_ "GenSigSendType" SG_ 2551357611 SBCU11_Reports_Set_Status 1;
BA_ "GenSigMaxValue" SG_ 2551357611 SBCU11_Reports_Set_Status 7;
BA_ "GenSigSendType" SG_ 2551357611 SBCU11_Confirms_Faultcode 1;
BA_ "GenSigMaxValue" SG_ 2551357611 SBCU11_Confirms_Faultcode 65535;
BA_ "GenSigSendType" SG_ 2551357610 SBCU10_Reports_Set_Status 1;
BA_ "GenSigMaxValue" SG_ 2551357610 SBCU10_Reports_Set_Status 7;
BA_ "GenSigSendType" SG_ 2551357610 SBCU10_Confirms_Faultcode 1;
BA_ "GenSigMaxValue" SG_ 2551357610 SBCU10_Confirms_Faultcode 65535;
BA_ "GenSigSendType" SG_ 2551357609 SBCU9_Reports_Set_Status 1;
BA_ "GenSigMaxValue" SG_ 2551357609 SBCU9_Reports_Set_Status 7;
BA_ "GenSigSendType" SG_ 2551357609 SBCU9_Confirms_Faultcode 1;
BA_ "GenSigMaxValue" SG_ 2551357609 SBCU9_Confirms_Faultcode 65535;
BA_ "GenSigSendType" SG_ 2551357608 SBCU8_Reports_Set_Status 1;
BA_ "GenSigMaxValue" SG_ 2551357608 SBCU8_Reports_Set_Status 7;
BA_ "GenSigSendType" SG_ 2551357608 SBCU8_Confirms_Faultcode 1;
BA_ "GenSigMaxValue" SG_ 2551357608 SBCU8_Confirms_Faultcode 65535;
BA_ "GenSigSendType" SG_ 2551357607 SBCU7_Reports_Set_Status 1;
BA_ "GenSigMaxValue" SG_ 2551357607 SBCU7_Reports_Set_Status 7;
BA_ "GenSigSendType" SG_ 2551357607 SBCU7_Confirms_Faultcode 1;
BA_ "GenSigMaxValue" SG_ 2551357607 SBCU7_Confirms_Faultcode 65535;
BA_ "GenSigSendType" SG_ 2551357606 SBCU6_Reports_Set_Status 1;
BA_ "GenSigMaxValue" SG_ 2551357606 SBCU6_Reports_Set_Status 7;
BA_ "GenSigSendType" SG_ 2551357606 SBCU6_Confirms_Faultcode 1;
BA_ "GenSigMaxValue" SG_ 2551357606 SBCU6_Confirms_Faultcode 65535;
BA_ "GenSigSendType" SG_ 2551357605 SBCU5_Reports_Set_Status 1;
BA_ "GenSigMaxValue" SG_ 2551357605 SBCU5_Reports_Set_Status 7;
BA_ "GenSigSendType" SG_ 2551357605 SBCU5_Confirms_Faultcode 1;
BA_ "GenSigMaxValue" SG_ 2551357605 SBCU5_Confirms_Faultcode 65535;
BA_ "GenSigSendType" SG_ 2551357604 SBCU4_Reports_Set_Status 1;
BA_ "GenSigMaxValue" SG_ 2551357604 SBCU4_Reports_Set_Status 7;
BA_ "GenSigSendType" SG_ 2551357604 SBCU4_Confirms_Faultcode 1;
BA_ "GenSigMaxValue" SG_ 2551357604 SBCU4_Confirms_Faultcode 65535;
BA_ "GenSigSendType" SG_ 2551357603 SBCU3_Reports_Set_Status 1;
BA_ "GenSigMaxValue" SG_ 2551357603 SBCU3_Reports_Set_Status 7;
BA_ "GenSigSendType" SG_ 2551357603 SBCU3_Confirms_Faultcode 1;
BA_ "GenSigMaxValue" SG_ 2551357603 SBCU3_Confirms_Faultcode 65535;
BA_ "GenSigSendType" SG_ 2551357602 SBCU2_Reports_Set_Status 1;
BA_ "GenSigMaxValue" SG_ 2551357602 SBCU2_Reports_Set_Status 7;
BA_ "GenSigSendType" SG_ 2551357602 SBCU2_Confirms_Faultcode 1;
BA_ "GenSigMaxValue" SG_ 2551357602 SBCU2_Confirms_Faultcode 65535;
BA_ "GenSigSendType" SG_ 2551357601 SBCU1_Reports_Set_Status 1;
BA_ "GenSigMaxValue" SG_ 2551357601 SBCU1_Reports_Set_Status 7;
BA_ "GenSigSendType" SG_ 2551357601 SBCU1_Confirms_Faultcode 1;
BA_ "GenSigMaxValue" SG_ 2551357601 SBCU1_Confirms_Faultcode 65535;
BA_ "GenSigSendType" SG_ 6 Calib_ParaContent2 1;
BA_ "GenSigMaxValue" SG_ 6 Calib_ParaContent2 65535;
BA_ "GenSigSendType" SG_ 6 Calib_ParaContent1 1;
BA_ "GenSigMaxValue" SG_ 6 Calib_ParaContent1 65535;
BA_ "GenSigSendType" SG_ 6 Calib_Type 1;
BA_ "GenSigMaxValue" SG_ 6 Calib_Type 255;
BA_ "GenSigSendType" SG_ 6 Calib_SBCU_ID 1;
BA_ "GenSigMaxValue" SG_ 6 Calib_SBCU_ID 255;
BA_ "GenSigSendType" SG_ 6 Calib_Msg_Count 1;
BA_ "GenSigMaxValue" SG_ 6 Calib_Msg_Count 255;
BA_ "GenSigSendType" SG_ 6 Calib_Msg_Index 1;
BA_ "GenSigMaxValue" SG_ 6 Calib_Msg_Index 255;
BA_ "GenSigSendType" SG_ 2551292079 SBCU15_ReleaseVersion 1;
BA_ "GenSigMaxValue" SG_ 2551292079 SBCU15_ReleaseVersion 2147483647;
BA_ "GenSigSendType" SG_ 2551292079 SBCU15_BMU_ReleaseVersion 1;
BA_ "GenSigMaxValue" SG_ 2551292079 SBCU15_BMU_ReleaseVersion 16777215;
BA_ "GenSigSendType" SG_ 2551292079 SBCU15_BMU_Index 1;
BA_ "GenSigMaxValue" SG_ 2551292079 SBCU15_BMU_Index 255;
BA_ "GenSigSendType" SG_ 2551292078 SBCU14_ReleaseVersion 1;
BA_ "GenSigMaxValue" SG_ 2551292078 SBCU14_ReleaseVersion 2147483647;
BA_ "GenSigSendType" SG_ 2551292078 SBCU14_BMU_ReleaseVersion 1;
BA_ "GenSigMaxValue" SG_ 2551292078 SBCU14_BMU_ReleaseVersion 16777215;
BA_ "GenSigSendType" SG_ 2551292078 SBCU14_BMU_Index 1;
BA_ "GenSigMaxValue" SG_ 2551292078 SBCU14_BMU_Index 255;
BA_ "GenSigSendType" SG_ 2551292077 SBCU13_ReleaseVersion 1;
BA_ "GenSigMaxValue" SG_ 2551292077 SBCU13_ReleaseVersion 2147483647;
BA_ "GenSigSendType" SG_ 2551292077 SBCU13_BMU_ReleaseVersion 1;
BA_ "GenSigMaxValue" SG_ 2551292077 SBCU13_BMU_ReleaseVersion 16777215;
BA_ "GenSigSendType" SG_ 2551292077 SBCU13_BMU_Index 1;
BA_ "GenSigMaxValue" SG_ 2551292077 SBCU13_BMU_Index 255;
BA_ "GenSigSendType" SG_ 2551292076 SBCU12_ReleaseVersion 1;
BA_ "GenSigMaxValue" SG_ 2551292076 SBCU12_ReleaseVersion 2147483647;
BA_ "GenSigSendType" SG_ 2551292076 SBCU12_BMU_ReleaseVersion 1;
BA_ "GenSigMaxValue" SG_ 2551292076 SBCU12_BMU_ReleaseVersion 16777215;
BA_ "GenSigSendType" SG_ 2551292076 SBCU12_BMU_Index 1;
BA_ "GenSigMaxValue" SG_ 2551292076 SBCU12_BMU_Index 255;
BA_ "GenSigSendType" SG_ 2551292075 SBCU11_ReleaseVersion 1;
BA_ "GenSigMaxValue" SG_ 2551292075 SBCU11_ReleaseVersion 2147483647;
BA_ "GenSigSendType" SG_ 2551292075 SBCU11_BMU_ReleaseVersion 1;
BA_ "GenSigMaxValue" SG_ 2551292075 SBCU11_BMU_ReleaseVersion 16777215;
BA_ "GenSigSendType" SG_ 2551292075 SBCU11_BMU_Index 1;
BA_ "GenSigMaxValue" SG_ 2551292075 SBCU11_BMU_Index 255;
BA_ "GenSigSendType" SG_ 2551292074 SBCU10_ReleaseVersion 1;
BA_ "GenSigMaxValue" SG_ 2551292074 SBCU10_ReleaseVersion 2147483647;
BA_ "GenSigSendType" SG_ 2551292074 SBCU10_BMU_ReleaseVersion 1;
BA_ "GenSigMaxValue" SG_ 2551292074 SBCU10_BMU_ReleaseVersion 16777215;
BA_ "GenSigSendType" SG_ 2551292074 SBCU10_BMU_Index 1;
BA_ "GenSigMaxValue" SG_ 2551292074 SBCU10_BMU_Index 255;
BA_ "GenSigSendType" SG_ 2551292073 SBCU9_ReleaseVersion 1;
BA_ "GenSigMaxValue" SG_ 2551292073 SBCU9_ReleaseVersion 2147483647;
BA_ "GenSigSendType" SG_ 2551292073 SBCU9_BMU_ReleaseVersion 1;
BA_ "GenSigMaxValue" SG_ 2551292073 SBCU9_BMU_ReleaseVersion 16777215;
BA_ "GenSigSendType" SG_ 2551292073 SBCU9_BMU_Index 1;
BA_ "GenSigMaxValue" SG_ 2551292073 SBCU9_BMU_Index 255;
BA_ "GenSigSendType" SG_ 2551292072 SBCU8_ReleaseVersion 1;
BA_ "GenSigMaxValue" SG_ 2551292072 SBCU8_ReleaseVersion 2147483647;
BA_ "GenSigSendType" SG_ 2551292072 SBCU8_BMU_ReleaseVersion 1;
BA_ "GenSigMaxValue" SG_ 2551292072 SBCU8_BMU_ReleaseVersion 16777215;
BA_ "GenSigSendType" SG_ 2551292072 SBCU8_BMU_Index 1;
BA_ "GenSigMaxValue" SG_ 2551292072 SBCU8_BMU_Index 255;
BA_ "GenSigSendType" SG_ 2551292071 SBCU7_ReleaseVersion 1;
BA_ "GenSigMaxValue" SG_ 2551292071 SBCU7_ReleaseVersion 2147483647;
BA_ "GenSigSendType" SG_ 2551292071 SBCU7_BMU_ReleaseVersion 1;
BA_ "GenSigMaxValue" SG_ 2551292071 SBCU7_BMU_ReleaseVersion 16777215;
BA_ "GenSigSendType" SG_ 2551292071 SBCU7_BMU_Index 1;
BA_ "GenSigMaxValue" SG_ 2551292071 SBCU7_BMU_Index 255;
BA_ "GenSigSendType" SG_ 2551292070 SBCU6_ReleaseVersion 1;
BA_ "GenSigMaxValue" SG_ 2551292070 SBCU6_ReleaseVersion 2147483647;
BA_ "GenSigSendType" SG_ 2551292070 SBCU6_BMU_ReleaseVersion 1;
BA_ "GenSigMaxValue" SG_ 2551292070 SBCU6_BMU_ReleaseVersion 16777215;
BA_ "GenSigSendType" SG_ 2551292070 SBCU6_BMU_Index 1;
BA_ "GenSigMaxValue" SG_ 2551292070 SBCU6_BMU_Index 255;
BA_ "GenSigSendType" SG_ 2551292069 SBCU5_ReleaseVersion 1;
BA_ "GenSigMaxValue" SG_ 2551292069 SBCU5_ReleaseVersion 2147483647;
BA_ "GenSigSendType" SG_ 2551292069 SBCU5_BMU_ReleaseVersion 1;
BA_ "GenSigMaxValue" SG_ 2551292069 SBCU5_BMU_ReleaseVersion 16777215;
BA_ "GenSigSendType" SG_ 2551292069 SBCU5_BMU_Index 1;
BA_ "GenSigMaxValue" SG_ 2551292069 SBCU5_BMU_Index 255;
BA_ "GenSigSendType" SG_ 2551292068 SBCU4_ReleaseVersion 1;
BA_ "GenSigMaxValue" SG_ 2551292068 SBCU4_ReleaseVersion 2147483647;
BA_ "GenSigSendType" SG_ 2551292068 SBCU4_BMU_ReleaseVersion 1;
BA_ "GenSigMaxValue" SG_ 2551292068 SBCU4_BMU_ReleaseVersion 16777215;
BA_ "GenSigSendType" SG_ 2551292068 SBCU4_BMU_Index 1;
BA_ "GenSigMaxValue" SG_ 2551292068 SBCU4_BMU_Index 255;
BA_ "GenSigSendType" SG_ 2551292067 SBCU3_ReleaseVersion 1;
BA_ "GenSigMaxValue" SG_ 2551292067 SBCU3_ReleaseVersion 2147483647;
BA_ "GenSigSendType" SG_ 2551292067 SBCU3_BMU_ReleaseVersion 1;
BA_ "GenSigMaxValue" SG_ 2551292067 SBCU3_BMU_ReleaseVersion 16777215;
BA_ "GenSigSendType" SG_ 2551292067 SBCU3_BMU_Index 1;
BA_ "GenSigMaxValue" SG_ 2551292067 SBCU3_BMU_Index 255;
BA_ "GenSigSendType" SG_ 2551292066 SBCU2_ReleaseVersion 1;
BA_ "GenSigMaxValue" SG_ 2551292066 SBCU2_ReleaseVersion 2147483647;
BA_ "GenSigSendType" SG_ 2551292066 SBCU2_BMU_ReleaseVersion 1;
BA_ "GenSigMaxValue" SG_ 2551292066 SBCU2_BMU_ReleaseVersion 16777215;
BA_ "GenSigSendType" SG_ 2551292066 SBCU2_BMU_Index 1;
BA_ "GenSigMaxValue" SG_ 2551292066 SBCU2_BMU_Index 255;
BA_ "GenSigSendType" SG_ 2551292065 SBCU1_BMU_ReleaseVersion 1;
BA_ "GenSigMaxValue" SG_ 2551292065 SBCU1_BMU_ReleaseVersion 16777215;
BA_ "GenSigSendType" SG_ 2551292065 SBCU1_BMU_Index 1;
BA_ "GenSigMaxValue" SG_ 2551292065 SBCU1_BMU_Index 255;
BA_ "GenSigSendType" SG_ 2551292065 SBCU1_ReleaseVersion 1;
BA_ "GenSigMaxValue" SG_ 2551292065 SBCU1_ReleaseVersion 2147483647;
BA_ "GenSigSendType" SG_ 511 Tester_Silence_Data6_ExtCAN 1;
BA_ "GenSigMaxValue" SG_ 511 Tester_Silence_Data6_ExtCAN 255;
BA_ "GenSigSendType" SG_ 511 Tester_Silence_Data5_ExtCAN 1;
BA_ "GenSigMaxValue" SG_ 511 Tester_Silence_Data5_ExtCAN 255;
BA_ "GenSigSendType" SG_ 511 Tester_Silence_Data4_ExtCAN 1;
BA_ "GenSigMaxValue" SG_ 511 Tester_Silence_Data4_ExtCAN 255;
BA_ "GenSigSendType" SG_ 511 Tester_Silence_Data3_ExtCAN 1;
BA_ "GenSigMaxValue" SG_ 511 Tester_Silence_Data3_ExtCAN 255;
BA_ "GenSigSendType" SG_ 511 Tester_Silence_Data2_ExtCAN 1;
BA_ "GenSigMaxValue" SG_ 511 Tester_Silence_Data2_ExtCAN 255;
BA_ "GenSigSendType" SG_ 511 Tester_Silence_Data1_ExtCAN 1;
BA_ "GenSigMaxValue" SG_ 511 Tester_Silence_Data1_ExtCAN 255;
BA_ "GenSigSendType" SG_ 511 Tester_Silence_Crc_ExtCAN 1;
BA_ "GenSigMaxValue" SG_ 511 Tester_Silence_Crc_ExtCAN 255;
BA_ "GenSigSendType" SG_ 511 Tester_Silence_Cmd1_ExtCAN 1;
BA_ "GenSigMaxValue" SG_ 511 Tester_Silence_Cmd1_ExtCAN 255;
BA_ "GenSigSendType" SG_ 2551226543 SBCU15_CutOff_Relay_Pack_Volt 1;
BA_ "GenSigMaxValue" SG_ 2551226543 SBCU15_CutOff_Relay_Pack_Volt 65535;
BA_ "GenSigSendType" SG_ 2551226543 SBCU15_CutOff_Relay_Current 1;
BA_ "GenSigMaxValue" SG_ 2551226543 SBCU15_CutOff_Relay_Current 65535;
BA_ "GenSigStartValue" SG_ 2551226543 SBCU15_CutOff_Relay_Current 32000;
BA_ "GenSigSendType" SG_ 2550767791 SBCU15_BMU_FaultID 1;
BA_ "GenSigMaxValue" SG_ 2550767791 SBCU15_BMU_FaultID 31;
BA_ "GenSigSendType" SG_ 2550767791 SBCU15_CellTemp_Mean 1;
BA_ "GenSigMaxValue" SG_ 2550767791 SBCU15_CellTemp_Mean 255;
BA_ "GenSigSendType" SG_ 2550767791 SBCU15_Real_SOH 1;
BA_ "GenSigMaxValue" SG_ 2550767791 SBCU15_Real_SOH 65535;
BA_ "GenSigSendType" SG_ 2550767791 SBCU15_Real_SOC 1;
BA_ "GenSigMaxValue" SG_ 2550767791 SBCU15_Real_SOC 65535;
BA_ "GenSigSendType" SG_ 2551226542 SBCU14_CutOff_Relay_Pack_Volt 1;
BA_ "GenSigMaxValue" SG_ 2551226542 SBCU14_CutOff_Relay_Pack_Volt 65535;
BA_ "GenSigSendType" SG_ 2551226542 SBCU14_CutOff_Relay_Current 1;
BA_ "GenSigMaxValue" SG_ 2551226542 SBCU14_CutOff_Relay_Current 65535;
BA_ "GenSigStartValue" SG_ 2551226542 SBCU14_CutOff_Relay_Current 32000;
BA_ "GenSigSendType" SG_ 2550767790 SBCU14_BMU_FaultID 1;
BA_ "GenSigMaxValue" SG_ 2550767790 SBCU14_BMU_FaultID 31;
BA_ "GenSigSendType" SG_ 2550767790 SBCU14_CellTemp_Mean 1;
BA_ "GenSigMaxValue" SG_ 2550767790 SBCU14_CellTemp_Mean 255;
BA_ "GenSigSendType" SG_ 2550767790 SBCU14_Real_SOH 1;
BA_ "GenSigMaxValue" SG_ 2550767790 SBCU14_Real_SOH 65535;
BA_ "GenSigSendType" SG_ 2550767790 SBCU14_Real_SOC 1;
BA_ "GenSigMaxValue" SG_ 2550767790 SBCU14_Real_SOC 65535;
BA_ "GenSigSendType" SG_ 2551226541 SBCU13_CutOff_Relay_Pack_Volt 1;
BA_ "GenSigMaxValue" SG_ 2551226541 SBCU13_CutOff_Relay_Pack_Volt 65535;
BA_ "GenSigSendType" SG_ 2551226541 SBCU13_CutOff_Relay_Current 1;
BA_ "GenSigMaxValue" SG_ 2551226541 SBCU13_CutOff_Relay_Current 65535;
BA_ "GenSigStartValue" SG_ 2551226541 SBCU13_CutOff_Relay_Current 32000;
BA_ "GenSigSendType" SG_ 2550767789 SBCU13_BMU_FaultID 1;
BA_ "GenSigMaxValue" SG_ 2550767789 SBCU13_BMU_FaultID 31;
BA_ "GenSigSendType" SG_ 2550767789 SBCU13_CellTemp_Mean 1;
BA_ "GenSigMaxValue" SG_ 2550767789 SBCU13_CellTemp_Mean 255;
BA_ "GenSigSendType" SG_ 2550767789 SBCU13_Real_SOH 1;
BA_ "GenSigMaxValue" SG_ 2550767789 SBCU13_Real_SOH 65535;
BA_ "GenSigSendType" SG_ 2550767789 SBCU13_Real_SOC 1;
BA_ "GenSigMaxValue" SG_ 2550767789 SBCU13_Real_SOC 65535;
BA_ "GenSigSendType" SG_ 2551226540 SBCU12_CutOff_Relay_Pack_Volt 1;
BA_ "GenSigMaxValue" SG_ 2551226540 SBCU12_CutOff_Relay_Pack_Volt 65535;
BA_ "GenSigSendType" SG_ 2551226540 SBCU12_CutOff_Relay_Current 1;
BA_ "GenSigMaxValue" SG_ 2551226540 SBCU12_CutOff_Relay_Current 65535;
BA_ "GenSigStartValue" SG_ 2551226540 SBCU12_CutOff_Relay_Current 32000;
BA_ "GenSigSendType" SG_ 2550767788 SBCU12_BMU_FaultID 1;
BA_ "GenSigMaxValue" SG_ 2550767788 SBCU12_BMU_FaultID 31;
BA_ "GenSigSendType" SG_ 2550767788 SBCU12_CellTemp_Mean 1;
BA_ "GenSigMaxValue" SG_ 2550767788 SBCU12_CellTemp_Mean 255;
BA_ "GenSigSendType" SG_ 2550767788 SBCU12_Real_SOH 1;
BA_ "GenSigMaxValue" SG_ 2550767788 SBCU12_Real_SOH 65535;
BA_ "GenSigSendType" SG_ 2550767788 SBCU12_Real_SOC 1;
BA_ "GenSigMaxValue" SG_ 2550767788 SBCU12_Real_SOC 65535;
BA_ "GenSigSendType" SG_ 2551226539 SBCU11_CutOff_Relay_Pack_Volt 1;
BA_ "GenSigMaxValue" SG_ 2551226539 SBCU11_CutOff_Relay_Pack_Volt 65535;
BA_ "GenSigSendType" SG_ 2551226539 SBCU11_CutOff_Relay_Current 1;
BA_ "GenSigMaxValue" SG_ 2551226539 SBCU11_CutOff_Relay_Current 65535;
BA_ "GenSigStartValue" SG_ 2551226539 SBCU11_CutOff_Relay_Current 32000;
BA_ "GenSigSendType" SG_ 2550767787 SBCU11_BMU_FaultID 1;
BA_ "GenSigMaxValue" SG_ 2550767787 SBCU11_BMU_FaultID 31;
BA_ "GenSigSendType" SG_ 2550767787 SBCU11_CellTemp_Mean 1;
BA_ "GenSigMaxValue" SG_ 2550767787 SBCU11_CellTemp_Mean 255;
BA_ "GenSigSendType" SG_ 2550767787 SBCU11_Real_SOH 1;
BA_ "GenSigMaxValue" SG_ 2550767787 SBCU11_Real_SOH 65535;
BA_ "GenSigSendType" SG_ 2550767787 SBCU11_Real_SOC 1;
BA_ "GenSigMaxValue" SG_ 2550767787 SBCU11_Real_SOC 65535;
BA_ "GenSigSendType" SG_ 2551226538 SBCU10_CutOff_Relay_Pack_Volt 1;
BA_ "GenSigMaxValue" SG_ 2551226538 SBCU10_CutOff_Relay_Pack_Volt 65535;
BA_ "GenSigSendType" SG_ 2551226538 SBCU10_CutOff_Relay_Current 1;
BA_ "GenSigMaxValue" SG_ 2551226538 SBCU10_CutOff_Relay_Current 65535;
BA_ "GenSigStartValue" SG_ 2551226538 SBCU10_CutOff_Relay_Current 32000;
BA_ "GenSigSendType" SG_ 2550767786 SBCU10_BMU_FaultID 1;
BA_ "GenSigMaxValue" SG_ 2550767786 SBCU10_BMU_FaultID 31;
BA_ "GenSigSendType" SG_ 2550767786 SBCU10_CellTemp_Mean 1;
BA_ "GenSigMaxValue" SG_ 2550767786 SBCU10_CellTemp_Mean 255;
BA_ "GenSigSendType" SG_ 2550767786 SBCU10_Real_SOH 1;
BA_ "GenSigMaxValue" SG_ 2550767786 SBCU10_Real_SOH 65535;
BA_ "GenSigSendType" SG_ 2550767786 SBCU10_Real_SOC 1;
BA_ "GenSigMaxValue" SG_ 2550767786 SBCU10_Real_SOC 65535;
BA_ "GenSigSendType" SG_ 2551226537 SBCU9_CutOff_Relay_Pack_Volt 1;
BA_ "GenSigMaxValue" SG_ 2551226537 SBCU9_CutOff_Relay_Pack_Volt 65535;
BA_ "GenSigSendType" SG_ 2551226537 SBCU9_CutOff_Relay_Current 1;
BA_ "GenSigMaxValue" SG_ 2551226537 SBCU9_CutOff_Relay_Current 65535;
BA_ "GenSigStartValue" SG_ 2551226537 SBCU9_CutOff_Relay_Current 32000;
BA_ "GenSigSendType" SG_ 2550767785 SBCU9_BMU_FaultID 1;
BA_ "GenSigMaxValue" SG_ 2550767785 SBCU9_BMU_FaultID 31;
BA_ "GenSigSendType" SG_ 2550767785 SBCU9_CellTemp_Mean 1;
BA_ "GenSigMaxValue" SG_ 2550767785 SBCU9_CellTemp_Mean 255;
BA_ "GenSigSendType" SG_ 2550767785 SBCU9_Real_SOH 1;
BA_ "GenSigMaxValue" SG_ 2550767785 SBCU9_Real_SOH 65535;
BA_ "GenSigSendType" SG_ 2550767785 SBCU9_Real_SOC 1;
BA_ "GenSigMaxValue" SG_ 2550767785 SBCU9_Real_SOC 65535;
BA_ "GenSigSendType" SG_ 2551226536 SBCU8_CutOff_Relay_Pack_Volt 1;
BA_ "GenSigMaxValue" SG_ 2551226536 SBCU8_CutOff_Relay_Pack_Volt 65535;
BA_ "GenSigSendType" SG_ 2551226536 SBCU8_CutOff_Relay_Current 1;
BA_ "GenSigMaxValue" SG_ 2551226536 SBCU8_CutOff_Relay_Current 65535;
BA_ "GenSigStartValue" SG_ 2551226536 SBCU8_CutOff_Relay_Current 32000;
BA_ "GenSigSendType" SG_ 2550767784 SBCU8_BMU_FaultID 1;
BA_ "GenSigMaxValue" SG_ 2550767784 SBCU8_BMU_FaultID 31;
BA_ "GenSigSendType" SG_ 2550767784 SBCU8_CellTemp_Mean 1;
BA_ "GenSigMaxValue" SG_ 2550767784 SBCU8_CellTemp_Mean 255;
BA_ "GenSigSendType" SG_ 2550767784 SBCU8_Real_SOH 1;
BA_ "GenSigMaxValue" SG_ 2550767784 SBCU8_Real_SOH 65535;
BA_ "GenSigSendType" SG_ 2550767784 SBCU8_Real_SOC 1;
BA_ "GenSigMaxValue" SG_ 2550767784 SBCU8_Real_SOC 65535;
BA_ "GenSigSendType" SG_ 2551226535 SBCU7_CutOff_Relay_Pack_Volt 1;
BA_ "GenSigMaxValue" SG_ 2551226535 SBCU7_CutOff_Relay_Pack_Volt 65535;
BA_ "GenSigSendType" SG_ 2551226535 SBCU7_CutOff_Relay_Current 1;
BA_ "GenSigMaxValue" SG_ 2551226535 SBCU7_CutOff_Relay_Current 65535;
BA_ "GenSigStartValue" SG_ 2551226535 SBCU7_CutOff_Relay_Current 32000;
BA_ "GenSigSendType" SG_ 2550767783 SBCU7_BMU_FaultID 1;
BA_ "GenSigMaxValue" SG_ 2550767783 SBCU7_BMU_FaultID 31;
BA_ "GenSigSendType" SG_ 2550767783 SBCU7_CellTemp_Mean 1;
BA_ "GenSigMaxValue" SG_ 2550767783 SBCU7_CellTemp_Mean 255;
BA_ "GenSigSendType" SG_ 2550767783 SBCU7_Real_SOH 1;
BA_ "GenSigMaxValue" SG_ 2550767783 SBCU7_Real_SOH 65535;
BA_ "GenSigSendType" SG_ 2550767783 SBCU7_Real_SOC 1;
BA_ "GenSigMaxValue" SG_ 2550767783 SBCU7_Real_SOC 65535;
BA_ "GenSigSendType" SG_ 2551226534 SBCU6_CutOff_Relay_Pack_Volt 1;
BA_ "GenSigMaxValue" SG_ 2551226534 SBCU6_CutOff_Relay_Pack_Volt 65535;
BA_ "GenSigSendType" SG_ 2551226534 SBCU6_CutOff_Relay_Current 1;
BA_ "GenSigMaxValue" SG_ 2551226534 SBCU6_CutOff_Relay_Current 65535;
BA_ "GenSigStartValue" SG_ 2551226534 SBCU6_CutOff_Relay_Current 32000;
BA_ "GenSigSendType" SG_ 2550767782 SBCU6_BMU_FaultID 1;
BA_ "GenSigMaxValue" SG_ 2550767782 SBCU6_BMU_FaultID 31;
BA_ "GenSigSendType" SG_ 2550767782 SBCU6_CellTemp_Mean 1;
BA_ "GenSigMaxValue" SG_ 2550767782 SBCU6_CellTemp_Mean 255;
BA_ "GenSigSendType" SG_ 2550767782 SBCU6_Real_SOH 1;
BA_ "GenSigMaxValue" SG_ 2550767782 SBCU6_Real_SOH 65535;
BA_ "GenSigSendType" SG_ 2550767782 SBCU6_Real_SOC 1;
BA_ "GenSigMaxValue" SG_ 2550767782 SBCU6_Real_SOC 65535;
BA_ "GenSigSendType" SG_ 2551226533 SBCU5_CutOff_Relay_Pack_Volt 1;
BA_ "GenSigMaxValue" SG_ 2551226533 SBCU5_CutOff_Relay_Pack_Volt 65535;
BA_ "GenSigSendType" SG_ 2551226533 SBCU5_CutOff_Relay_Current 1;
BA_ "GenSigMaxValue" SG_ 2551226533 SBCU5_CutOff_Relay_Current 65535;
BA_ "GenSigStartValue" SG_ 2551226533 SBCU5_CutOff_Relay_Current 32000;
BA_ "GenSigSendType" SG_ 2550767781 SBCU5_BMU_FaultID 1;
BA_ "GenSigMaxValue" SG_ 2550767781 SBCU5_BMU_FaultID 31;
BA_ "GenSigSendType" SG_ 2550767781 SBCU5_CellTemp_Mean 1;
BA_ "GenSigMaxValue" SG_ 2550767781 SBCU5_CellTemp_Mean 255;
BA_ "GenSigSendType" SG_ 2550767781 SBCU5_Real_SOH 1;
BA_ "GenSigMaxValue" SG_ 2550767781 SBCU5_Real_SOH 65535;
BA_ "GenSigSendType" SG_ 2550767781 SBCU5_Real_SOC 1;
BA_ "GenSigMaxValue" SG_ 2550767781 SBCU5_Real_SOC 65535;
BA_ "GenSigSendType" SG_ 2551226532 SBCU4_CutOff_Relay_Pack_Volt 1;
BA_ "GenSigMaxValue" SG_ 2551226532 SBCU4_CutOff_Relay_Pack_Volt 65535;
BA_ "GenSigSendType" SG_ 2551226532 SBCU4_CutOff_Relay_Current 1;
BA_ "GenSigMaxValue" SG_ 2551226532 SBCU4_CutOff_Relay_Current 65535;
BA_ "GenSigStartValue" SG_ 2551226532 SBCU4_CutOff_Relay_Current 32000;
BA_ "GenSigSendType" SG_ 2550767780 SBCU4_BMU_FaultID 1;
BA_ "GenSigMaxValue" SG_ 2550767780 SBCU4_BMU_FaultID 31;
BA_ "GenSigSendType" SG_ 2550767780 SBCU4_CellTemp_Mean 1;
BA_ "GenSigMaxValue" SG_ 2550767780 SBCU4_CellTemp_Mean 255;
BA_ "GenSigSendType" SG_ 2550767780 SBCU4_Real_SOH 1;
BA_ "GenSigMaxValue" SG_ 2550767780 SBCU4_Real_SOH 65535;
BA_ "GenSigSendType" SG_ 2550767780 SBCU4_Real_SOC 1;
BA_ "GenSigMaxValue" SG_ 2550767780 SBCU4_Real_SOC 65535;
BA_ "GenSigSendType" SG_ 2551226531 SBCU3_CutOff_Relay_Pack_Volt 1;
BA_ "GenSigMaxValue" SG_ 2551226531 SBCU3_CutOff_Relay_Pack_Volt 65535;
BA_ "GenSigSendType" SG_ 2551226531 SBCU3_CutOff_Relay_Current 1;
BA_ "GenSigMaxValue" SG_ 2551226531 SBCU3_CutOff_Relay_Current 65535;
BA_ "GenSigStartValue" SG_ 2551226531 SBCU3_CutOff_Relay_Current 32000;
BA_ "GenSigSendType" SG_ 2550767779 SBCU3_BMU_FaultID 1;
BA_ "GenSigMaxValue" SG_ 2550767779 SBCU3_BMU_FaultID 31;
BA_ "GenSigSendType" SG_ 2550767779 SBCU3_CellTemp_Mean 1;
BA_ "GenSigMaxValue" SG_ 2550767779 SBCU3_CellTemp_Mean 255;
BA_ "GenSigSendType" SG_ 2550767779 SBCU3_Real_SOH 1;
BA_ "GenSigMaxValue" SG_ 2550767779 SBCU3_Real_SOH 65535;
BA_ "GenSigSendType" SG_ 2550767779 SBCU3_Real_SOC 1;
BA_ "GenSigMaxValue" SG_ 2550767779 SBCU3_Real_SOC 65535;
BA_ "GenSigSendType" SG_ 2551226530 SBCU2_CutOff_Relay_Pack_Volt 1;
BA_ "GenSigMaxValue" SG_ 2551226530 SBCU2_CutOff_Relay_Pack_Volt 65535;
BA_ "GenSigSendType" SG_ 2551226530 SBCU2_CutOff_Relay_Current 1;
BA_ "GenSigMaxValue" SG_ 2551226530 SBCU2_CutOff_Relay_Current 65535;
BA_ "GenSigStartValue" SG_ 2551226530 SBCU2_CutOff_Relay_Current 32000;
BA_ "GenSigSendType" SG_ 2550767778 SBCU2_BMU_FaultID 1;
BA_ "GenSigMaxValue" SG_ 2550767778 SBCU2_BMU_FaultID 31;
BA_ "GenSigSendType" SG_ 2550767778 SBCU2_CellTemp_Mean 1;
BA_ "GenSigMaxValue" SG_ 2550767778 SBCU2_CellTemp_Mean 255;
BA_ "GenSigSendType" SG_ 2550767778 SBCU2_Real_SOH 1;
BA_ "GenSigMaxValue" SG_ 2550767778 SBCU2_Real_SOH 65535;
BA_ "GenSigSendType" SG_ 2550767778 SBCU2_Real_SOC 1;
BA_ "GenSigMaxValue" SG_ 2550767778 SBCU2_Real_SOC 65535;
BA_ "GenSigSendType" SG_ 2551226529 SBCU1_CutOff_Relay_Pack_Volt 1;
BA_ "GenSigMaxValue" SG_ 2551226529 SBCU1_CutOff_Relay_Pack_Volt 65535;
BA_ "GenSigSendType" SG_ 2551226529 SBCU1_CutOff_Relay_Current 1;
BA_ "GenSigMaxValue" SG_ 2551226529 SBCU1_CutOff_Relay_Current 65535;
BA_ "GenSigStartValue" SG_ 2551226529 SBCU1_CutOff_Relay_Current 32000;
BA_ "GenSigSendType" SG_ 2550767777 SBCU1_BMU_FaultID 1;
BA_ "GenSigMaxValue" SG_ 2550767777 SBCU1_BMU_FaultID 31;
BA_ "GenSigSendType" SG_ 2550767777 SBCU1_CellTemp_Mean 1;
BA_ "GenSigMaxValue" SG_ 2550767777 SBCU1_CellTemp_Mean 255;
BA_ "GenSigSendType" SG_ 2550767777 SBCU1_Real_SOH 1;
BA_ "GenSigMaxValue" SG_ 2550767777 SBCU1_Real_SOH 65535;
BA_ "GenSigSendType" SG_ 2550767777 SBCU1_Real_SOC 1;
BA_ "GenSigMaxValue" SG_ 2550767777 SBCU1_Real_SOC 65535;
BA_ "GenSigSendType" SG_ 2566389935 SBCU15_CellTemp_Rev 1;
BA_ "GenSigMaxValue" SG_ 2566389935 SBCU15_CellTemp_Rev 65535;
BA_ "GenSigSendType" SG_ 2566389935 SBCU15_CellTemp2_CellNO 1;
BA_ "GenSigMaxValue" SG_ 2566389935 SBCU15_CellTemp2_CellNO 255;
BA_ "GenSigSendType" SG_ 2566389935 SBCU15_CellTemp2_BMUNO 1;
BA_ "GenSigMaxValue" SG_ 2566389935 SBCU15_CellTemp2_BMUNO 255;
BA_ "GenSigSendType" SG_ 2566389935 SBCU15_CellTemp2 1;
BA_ "GenSigMaxValue" SG_ 2566389935 SBCU15_CellTemp2 255;
BA_ "GenSigSendType" SG_ 2566389935 SBCU15_CellTemp1_CellNO 1;
BA_ "GenSigMaxValue" SG_ 2566389935 SBCU15_CellTemp1_CellNO 255;
BA_ "GenSigSendType" SG_ 2566389935 SBCU15_CellTemp1_BMUNO 1;
BA_ "GenSigMaxValue" SG_ 2566389935 SBCU15_CellTemp1_BMUNO 255;
BA_ "GenSigSendType" SG_ 2566389935 SBCU15_CellTemp1 1;
BA_ "GenSigMaxValue" SG_ 2566389935 SBCU15_CellTemp1 255;
BA_ "GenSigSendType" SG_ 2550898863 SBCU15_Accum_DchEng 1;
BA_ "GenSigMaxValue" SG_ 2550898863 SBCU15_Accum_DchEng 2147483647;
BA_ "GenSigSendType" SG_ 2550898863 SBCU15_Accum_ChgEng 1;
BA_ "GenSigMaxValue" SG_ 2550898863 SBCU15_Accum_ChgEng 2147483647;
BA_ "GenSigSendType" SG_ 2550833327 SBCU15_Accum_DchCap 1;
BA_ "GenSigMaxValue" SG_ 2550833327 SBCU15_Accum_DchCap 2147483647;
BA_ "GenSigSendType" SG_ 2550833327 SBCU15_Accum_ChgCap 1;
BA_ "GenSigMaxValue" SG_ 2550833327 SBCU15_Accum_ChgCap 2147483647;
BA_ "GenSigSendType" SG_ 2550374575 SBCU15_SOH 1;
BA_ "GenSigMaxValue" SG_ 2550374575 SBCU15_SOH 4095;
BA_ "GenSigSendType" SG_ 2550374575 SBCU15_PowerSupply_Volt 1;
BA_ "GenSigMaxValue" SG_ 2550374575 SBCU15_PowerSupply_Volt 4095;
BA_ "GenSigSendType" SG_ 2550374575 SBCU15_Isolation 1;
BA_ "GenSigMaxValue" SG_ 2550374575 SBCU15_Isolation 65535;
BA_ "GenSigSendType" SG_ 2550374575 SBCU15_AI3_Value 1;
BA_ "GenSigMaxValue" SG_ 2550374575 SBCU15_AI3_Value 255;
BA_ "GenSigSendType" SG_ 2550374575 SBCU15_AI2_Value 1;
BA_ "GenSigMaxValue" SG_ 2550374575 SBCU15_AI2_Value 255;
BA_ "GenSigSendType" SG_ 2550374575 SBCU15_AI1_Value 1;
BA_ "GenSigMaxValue" SG_ 2550374575 SBCU15_AI1_Value 255;
BA_ "GenSigSendType" SG_ 2348982447 SBCU15_WorkMode 1;
BA_ "GenSigMaxValue" SG_ 2348982447 SBCU15_WorkMode 15;
BA_ "GenSigSendType" SG_ 2348982447 SBCU15_Ready 1;
BA_ "GenSigMaxValue" SG_ 2348982447 SBCU15_Ready 3;
BA_ "GenSigSendType" SG_ 2348982447 SBCU15_PreChgRelay_Status 1;
BA_ "GenSigMaxValue" SG_ 2348982447 SBCU15_PreChgRelay_Status 3;
BA_ "GenSigSendType" SG_ 2348982447 SBCU15_PosRelay_Status 1;
BA_ "GenSigMaxValue" SG_ 2348982447 SBCU15_PosRelay_Status 3;
BA_ "GenSigSendType" SG_ 2348982447 SBCU15_PosIso_Optical 1;
BA_ "GenSigMaxValue" SG_ 2348982447 SBCU15_PosIso_Optical 1;
BA_ "GenSigSendType" SG_ 2348982447 SBCU15_NegRelay_Status 1;
BA_ "GenSigMaxValue" SG_ 2348982447 SBCU15_NegRelay_Status 3;
BA_ "GenSigSendType" SG_ 2348982447 SBCU15_NegIso_Optical 1;
BA_ "GenSigMaxValue" SG_ 2348982447 SBCU15_NegIso_Optical 1;
BA_ "GenSigSendType" SG_ 2348982447 SBCU15_Life 1;
BA_ "GenSigMaxValue" SG_ 2348982447 SBCU15_Life 15;
BA_ "GenSigSendType" SG_ 2348982447 SBCU15_ISO_Status 1;
BA_ "GenSigMaxValue" SG_ 2348982447 SBCU15_ISO_Status 3;
BA_ "GenSigSendType" SG_ 2348982447 SBCU15_ISO_Allow 1;
BA_ "GenSigMaxValue" SG_ 2348982447 SBCU15_ISO_Allow 3;
BA_ "GenSigSendType" SG_ 2348982447 SBCU15_HVOff_Req 1;
BA_ "GenSigMaxValue" SG_ 2348982447 SBCU15_HVOff_Req 3;
BA_ "GenSigSendType" SG_ 2348982447 SBCU15_HV_Step 1;
BA_ "GenSigMaxValue" SG_ 2348982447 SBCU15_HV_Step 15;
BA_ "GenSigSendType" SG_ 2348982447 SBCU15_HeatRelay_Status 1;
BA_ "GenSigMaxValue" SG_ 2348982447 SBCU15_HeatRelay_Status 3;
BA_ "GenSigSendType" SG_ 2348982447 SBCU15_FcgRelay_Status 1;
BA_ "GenSigMaxValue" SG_ 2348982447 SBCU15_FcgRelay_Status 3;
BA_ "GenSigSendType" SG_ 2348982447 SBCU15_FaultLevel 1;
BA_ "GenSigMaxValue" SG_ 2348982447 SBCU15_FaultLevel 3;
BA_ "GenSigSendType" SG_ 2348982447 SBCU15_FaultCode 1;
BA_ "GenSigMaxValue" SG_ 2348982447 SBCU15_FaultCode 65535;
BA_ "GenSigSendType" SG_ 2348982447 SBCU15_FanRelay_Status 1;
BA_ "GenSigMaxValue" SG_ 2348982447 SBCU15_FanRelay_Status 3;
BA_ "GenSigSendType" SG_ 2348982447 SBCU15_DO3_Ctrl 1;
BA_ "GenSigMaxValue" SG_ 2348982447 SBCU15_DO3_Ctrl 1;
BA_ "GenSigSendType" SG_ 2348982447 SBCU15_DO2_Ctrl 1;
BA_ "GenSigMaxValue" SG_ 2348982447 SBCU15_DO2_Ctrl 1;
BA_ "GenSigSendType" SG_ 2348982447 SBCU15_DO1_Ctrl 1;
BA_ "GenSigMaxValue" SG_ 2348982447 SBCU15_DO1_Ctrl 1;
BA_ "GenSigSendType" SG_ 2348982447 SBCU15_DI5_Status 1;
BA_ "GenSigMaxValue" SG_ 2348982447 SBCU15_DI5_Status 1;
BA_ "GenSigSendType" SG_ 2348982447 SBCU15_DI4_Status 1;
BA_ "GenSigMaxValue" SG_ 2348982447 SBCU15_DI4_Status 1;
BA_ "GenSigSendType" SG_ 2348982447 SBCU15_DI3_Status 1;
BA_ "GenSigMaxValue" SG_ 2348982447 SBCU15_DI3_Status 1;
BA_ "GenSigSendType" SG_ 2348982447 SBCU15_DI2_Status 1;
BA_ "GenSigMaxValue" SG_ 2348982447 SBCU15_DI2_Status 1;
BA_ "GenSigSendType" SG_ 2348982447 SBCU15_DI1_Status 1;
BA_ "GenSigMaxValue" SG_ 2348982447 SBCU15_DI1_Status 1;
BA_ "GenSigSendType" SG_ 2348982447 SBCU15_BMS_RunStatus 1;
BA_ "GenSigMaxValue" SG_ 2348982447 SBCU15_BMS_RunStatus 15;
BA_ "GenSigSendType" SG_ 2550505647 SBCU15_DchPeakPower_Limit 1;
BA_ "GenSigMaxValue" SG_ 2550505647 SBCU15_DchPeakPower_Limit 65535;
BA_ "GenSigSendType" SG_ 2550505647 SBCU15_DchContinuousPower_Limit 1;
BA_ "GenSigMaxValue" SG_ 2550505647 SBCU15_DchContinuousPower_Limit 65535;
BA_ "GenSigSendType" SG_ 2550505647 SBCU15_ChgPeakPower_Limit 1;
BA_ "GenSigMaxValue" SG_ 2550505647 SBCU15_ChgPeakPower_Limit 65535;
BA_ "GenSigSendType" SG_ 2550505647 SBCU15_ChgContinuousPower_Limit 1;
BA_ "GenSigMaxValue" SG_ 2550505647 SBCU15_ChgContinuousPower_Limit 65535;
BA_ "GenSigSendType" SG_ 2550440111 SBCU15_DchPeakCurr_Limit 1;
BA_ "GenSigMaxValue" SG_ 2550440111 SBCU15_DchPeakCurr_Limit 65535;
BA_ "GenSigSendType" SG_ 2550440111 SBCU15_DchContinuousCurr_Limit 1;
BA_ "GenSigMaxValue" SG_ 2550440111 SBCU15_DchContinuousCurr_Limit 65535;
BA_ "GenSigSendType" SG_ 2550440111 SBCU15_ChgPeakCurr_Limit 1;
BA_ "GenSigMaxValue" SG_ 2550440111 SBCU15_ChgPeakCurr_Limit 65535;
BA_ "GenSigSendType" SG_ 2550440111 SBCU15_ChgContinuousCurr_Limit 1;
BA_ "GenSigMaxValue" SG_ 2550440111 SBCU15_ChgContinuousCurr_Limit 65535;
BA_ "GenSigSendType" SG_ 2550636719 SBCU15_CellVolt_Min_CellNO 1;
BA_ "GenSigMaxValue" SG_ 2550636719 SBCU15_CellVolt_Min_CellNO 255;
BA_ "GenSigSendType" SG_ 2550636719 SBCU15_CellVolt_Min_BMUNO 1;
BA_ "GenSigMaxValue" SG_ 2550636719 SBCU15_CellVolt_Min_BMUNO 255;
BA_ "GenSigSendType" SG_ 2550636719 SBCU15_CellVolt_Max_CellNO 1;
BA_ "GenSigMaxValue" SG_ 2550636719 SBCU15_CellVolt_Max_CellNO 255;
BA_ "GenSigSendType" SG_ 2550636719 SBCU15_CellVolt_Max_BMUNO 1;
BA_ "GenSigMaxValue" SG_ 2550636719 SBCU15_CellVolt_Max_BMUNO 255;
BA_ "GenSigSendType" SG_ 2550636719 SBCU15_CellTemp_Min_CellNO 1;
BA_ "GenSigMaxValue" SG_ 2550636719 SBCU15_CellTemp_Min_CellNO 255;
BA_ "GenSigSendType" SG_ 2550636719 SBCU15_CellTemp_Min_BMUNO 1;
BA_ "GenSigMaxValue" SG_ 2550636719 SBCU15_CellTemp_Min_BMUNO 255;
BA_ "GenSigSendType" SG_ 2550636719 SBCU15_CellTemp_Max_CellNO 1;
BA_ "GenSigMaxValue" SG_ 2550636719 SBCU15_CellTemp_Max_CellNO 255;
BA_ "GenSigSendType" SG_ 2550636719 SBCU15_CellTemp_Max_BMUNO 1;
BA_ "GenSigMaxValue" SG_ 2550636719 SBCU15_CellTemp_Max_BMUNO 255;
BA_ "GenSigSendType" SG_ 2550571183 SBCU15_CellVolt_Min 1;
BA_ "GenSigMaxValue" SG_ 2550571183 SBCU15_CellVolt_Min 65535;
BA_ "GenSigSendType" SG_ 2550571183 SBCU15_CellVolt_Mean 1;
BA_ "GenSigMaxValue" SG_ 2550571183 SBCU15_CellVolt_Mean 65535;
BA_ "GenSigSendType" SG_ 2550571183 SBCU15_CellVolt_Max 1;
BA_ "GenSigMaxValue" SG_ 2550571183 SBCU15_CellVolt_Max 65535;
BA_ "GenSigSendType" SG_ 2550571183 SBCU15_CellTemp_Min 1;
BA_ "GenSigMaxValue" SG_ 2550571183 SBCU15_CellTemp_Min 255;
BA_ "GenSigSendType" SG_ 2550571183 SBCU15_CellTemp_Max 1;
BA_ "GenSigMaxValue" SG_ 2550571183 SBCU15_CellTemp_Max 255;
BA_ "GenSigSendType" SG_ 2550702255 SBCU15_NTC2 1;
BA_ "GenSigMaxValue" SG_ 2550702255 SBCU15_NTC2 255;
BA_ "GenSigSendType" SG_ 2550702255 SBCU15_NTC1 1;
BA_ "GenSigMaxValue" SG_ 2550702255 SBCU15_NTC1 255;
BA_ "GenSigSendType" SG_ 2550702255 SBCU15_ISO_PosVolt 1;
BA_ "GenSigMaxValue" SG_ 2550702255 SBCU15_ISO_PosVolt 65535;
BA_ "GenSigSendType" SG_ 2550702255 SBCU15_ISO_NegVolt 1;
BA_ "GenSigMaxValue" SG_ 2550702255 SBCU15_ISO_NegVolt 65535;
BA_ "GenSigSendType" SG_ 2550702255 SBCU15_CellVolt_Sum 1;
BA_ "GenSigMaxValue" SG_ 2550702255 SBCU15_CellVolt_Sum 65535;
BA_ "GenSigSendType" SG_ 2566652079 SBCU15_CellBalance_Pack_NO 1;
BA_ "GenSigMaxValue" SG_ 2566652079 SBCU15_CellBalance_Pack_NO 255;
BA_ "GenSigSendType" SG_ 2566652079 SBCU15_CellBalance049 1;
BA_ "GenSigMaxValue" SG_ 2566652079 SBCU15_CellBalance049 255;
BA_ "GenSigSendType" SG_ 2566652079 SBCU15_CellBalance041 1;
BA_ "GenSigMaxValue" SG_ 2566652079 SBCU15_CellBalance041 255;
BA_ "GenSigSendType" SG_ 2566652079 SBCU15_CellBalance033 1;
BA_ "GenSigMaxValue" SG_ 2566652079 SBCU15_CellBalance033 255;
BA_ "GenSigSendType" SG_ 2566652079 SBCU15_CellBalance025 1;
BA_ "GenSigMaxValue" SG_ 2566652079 SBCU15_CellBalance025 255;
BA_ "GenSigSendType" SG_ 2566652079 SBCU15_CellBalance017 1;
BA_ "GenSigMaxValue" SG_ 2566652079 SBCU15_CellBalance017 255;
BA_ "GenSigSendType" SG_ 2566652079 SBCU15_CellBalance009 1;
BA_ "GenSigMaxValue" SG_ 2566652079 SBCU15_CellBalance009 255;
BA_ "GenSigSendType" SG_ 2566652079 SBCU15_CellBalance001 1;
BA_ "GenSigMaxValue" SG_ 2566652079 SBCU15_CellBalance001 255;
BA_ "GenSigSendType" SG_ 2565865647 SBCU15_CellVolt2_CellNO 1;
BA_ "GenSigMaxValue" SG_ 2565865647 SBCU15_CellVolt2_CellNO 255;
BA_ "GenSigSendType" SG_ 2565865647 SBCU15_CellVolt2_BMUNO 1;
BA_ "GenSigMaxValue" SG_ 2565865647 SBCU15_CellVolt2_BMUNO 255;
BA_ "GenSigSendType" SG_ 2565865647 SBCU15_CellVolt2 1;
BA_ "GenSigMaxValue" SG_ 2565865647 SBCU15_CellVolt2 65535;
BA_ "GenSigSendType" SG_ 2565865647 SBCU15_CellVolt1_CellNO 1;
BA_ "GenSigMaxValue" SG_ 2565865647 SBCU15_CellVolt1_CellNO 255;
BA_ "GenSigSendType" SG_ 2565865647 SBCU15_CellVolt1_BMUNO 1;
BA_ "GenSigMaxValue" SG_ 2565865647 SBCU15_CellVolt1_BMUNO 255;
BA_ "GenSigSendType" SG_ 2565865647 SBCU15_CellVolt1 1;
BA_ "GenSigMaxValue" SG_ 2565865647 SBCU15_CellVolt1 65535;
BA_ "GenSigSendType" SG_ 2550243503 SBCU15_SOC 1;
BA_ "GenSigMaxValue" SG_ 2550243503 SBCU15_SOC 65535;
BA_ "GenSigSendType" SG_ 2550243503 SBCU15_Pack_Volt 1;
BA_ "GenSigMaxValue" SG_ 2550243503 SBCU15_Pack_Volt 65535;
BA_ "GenSigSendType" SG_ 2550243503 SBCU15_LinkVolt 1;
BA_ "GenSigMaxValue" SG_ 2550243503 SBCU15_LinkVolt 65535;
BA_ "GenSigSendType" SG_ 2550243503 SBCU15_BusCurrent 1;
BA_ "GenSigMaxValue" SG_ 2550243503 SBCU15_BusCurrent 65535;
BA_ "GenSigStartValue" SG_ 2550243503 SBCU15_BusCurrent 32000;
BA_ "GenSigSendType" SG_ 2566389934 SBCU14_CellTemp_Rev 1;
BA_ "GenSigMaxValue" SG_ 2566389934 SBCU14_CellTemp_Rev 65535;
BA_ "GenSigSendType" SG_ 2566389934 SBCU14_CellTemp2_CellNO 1;
BA_ "GenSigMaxValue" SG_ 2566389934 SBCU14_CellTemp2_CellNO 255;
BA_ "GenSigSendType" SG_ 2566389934 SBCU14_CellTemp2_BMUNO 1;
BA_ "GenSigMaxValue" SG_ 2566389934 SBCU14_CellTemp2_BMUNO 255;
BA_ "GenSigSendType" SG_ 2566389934 SBCU14_CellTemp2 1;
BA_ "GenSigMaxValue" SG_ 2566389934 SBCU14_CellTemp2 255;
BA_ "GenSigSendType" SG_ 2566389934 SBCU14_CellTemp1_CellNO 1;
BA_ "GenSigMaxValue" SG_ 2566389934 SBCU14_CellTemp1_CellNO 255;
BA_ "GenSigSendType" SG_ 2566389934 SBCU14_CellTemp1_BMUNO 1;
BA_ "GenSigMaxValue" SG_ 2566389934 SBCU14_CellTemp1_BMUNO 255;
BA_ "GenSigSendType" SG_ 2566389934 SBCU14_CellTemp1 1;
BA_ "GenSigMaxValue" SG_ 2566389934 SBCU14_CellTemp1 255;
BA_ "GenSigSendType" SG_ 2550898862 SBCU14_Accum_DchEng 1;
BA_ "GenSigMaxValue" SG_ 2550898862 SBCU14_Accum_DchEng 2147483647;
BA_ "GenSigSendType" SG_ 2550898862 SBCU14_Accum_ChgEng 1;
BA_ "GenSigMaxValue" SG_ 2550898862 SBCU14_Accum_ChgEng 2147483647;
BA_ "GenSigSendType" SG_ 2550833326 SBCU14_Accum_DchCap 1;
BA_ "GenSigMaxValue" SG_ 2550833326 SBCU14_Accum_DchCap 2147483647;
BA_ "GenSigSendType" SG_ 2550833326 SBCU14_Accum_ChgCap 1;
BA_ "GenSigMaxValue" SG_ 2550833326 SBCU14_Accum_ChgCap 2147483647;
BA_ "GenSigSendType" SG_ 2550374574 SBCU14_SOH 1;
BA_ "GenSigMaxValue" SG_ 2550374574 SBCU14_SOH 4095;
BA_ "GenSigSendType" SG_ 2550374574 SBCU14_PowerSupply_Volt 1;
BA_ "GenSigMaxValue" SG_ 2550374574 SBCU14_PowerSupply_Volt 4095;
BA_ "GenSigSendType" SG_ 2550374574 SBCU14_Isolation 1;
BA_ "GenSigMaxValue" SG_ 2550374574 SBCU14_Isolation 65535;
BA_ "GenSigSendType" SG_ 2550374574 SBCU14_AI3_Value 1;
BA_ "GenSigMaxValue" SG_ 2550374574 SBCU14_AI3_Value 255;
BA_ "GenSigSendType" SG_ 2550374574 SBCU14_AI2_Value 1;
BA_ "GenSigMaxValue" SG_ 2550374574 SBCU14_AI2_Value 255;
BA_ "GenSigSendType" SG_ 2550374574 SBCU14_AI1_Value 1;
BA_ "GenSigMaxValue" SG_ 2550374574 SBCU14_AI1_Value 255;
BA_ "GenSigSendType" SG_ 2348982446 SBCU14_WorkMode 1;
BA_ "GenSigMaxValue" SG_ 2348982446 SBCU14_WorkMode 15;
BA_ "GenSigSendType" SG_ 2348982446 SBCU14_Ready 1;
BA_ "GenSigMaxValue" SG_ 2348982446 SBCU14_Ready 3;
BA_ "GenSigSendType" SG_ 2348982446 SBCU14_PreChgRelay_Status 1;
BA_ "GenSigMaxValue" SG_ 2348982446 SBCU14_PreChgRelay_Status 3;
BA_ "GenSigSendType" SG_ 2348982446 SBCU14_PosRelay_Status 1;
BA_ "GenSigMaxValue" SG_ 2348982446 SBCU14_PosRelay_Status 3;
BA_ "GenSigSendType" SG_ 2348982446 SBCU14_PosIso_Optical 1;
BA_ "GenSigMaxValue" SG_ 2348982446 SBCU14_PosIso_Optical 1;
BA_ "GenSigSendType" SG_ 2348982446 SBCU14_NegRelay_Status 1;
BA_ "GenSigMaxValue" SG_ 2348982446 SBCU14_NegRelay_Status 3;
BA_ "GenSigSendType" SG_ 2348982446 SBCU14_NegIso_Optical 1;
BA_ "GenSigMaxValue" SG_ 2348982446 SBCU14_NegIso_Optical 1;
BA_ "GenSigSendType" SG_ 2348982446 SBCU14_Life 1;
BA_ "GenSigMaxValue" SG_ 2348982446 SBCU14_Life 15;
BA_ "GenSigSendType" SG_ 2348982446 SBCU14_ISO_Status 1;
BA_ "GenSigMaxValue" SG_ 2348982446 SBCU14_ISO_Status 3;
BA_ "GenSigSendType" SG_ 2348982446 SBCU14_ISO_Allow 1;
BA_ "GenSigMaxValue" SG_ 2348982446 SBCU14_ISO_Allow 3;
BA_ "GenSigSendType" SG_ 2348982446 SBCU14_HVOff_Req 1;
BA_ "GenSigMaxValue" SG_ 2348982446 SBCU14_HVOff_Req 3;
BA_ "GenSigSendType" SG_ 2348982446 SBCU14_HV_Step 1;
BA_ "GenSigMaxValue" SG_ 2348982446 SBCU14_HV_Step 15;
BA_ "GenSigSendType" SG_ 2348982446 SBCU14_HeatRelay_Status 1;
BA_ "GenSigMaxValue" SG_ 2348982446 SBCU14_HeatRelay_Status 3;
BA_ "GenSigSendType" SG_ 2348982446 SBCU14_FcgRelay_Status 1;
BA_ "GenSigMaxValue" SG_ 2348982446 SBCU14_FcgRelay_Status 3;
BA_ "GenSigSendType" SG_ 2348982446 SBCU14_FaultLevel 1;
BA_ "GenSigMaxValue" SG_ 2348982446 SBCU14_FaultLevel 3;
BA_ "GenSigSendType" SG_ 2348982446 SBCU14_FaultCode 1;
BA_ "GenSigMaxValue" SG_ 2348982446 SBCU14_FaultCode 65535;
BA_ "GenSigSendType" SG_ 2348982446 SBCU14_FanRelay_Status 1;
BA_ "GenSigMaxValue" SG_ 2348982446 SBCU14_FanRelay_Status 3;
BA_ "GenSigSendType" SG_ 2348982446 SBCU14_DO3_Ctrl 1;
BA_ "GenSigMaxValue" SG_ 2348982446 SBCU14_DO3_Ctrl 1;
BA_ "GenSigSendType" SG_ 2348982446 SBCU14_DO2_Ctrl 1;
BA_ "GenSigMaxValue" SG_ 2348982446 SBCU14_DO2_Ctrl 1;
BA_ "GenSigSendType" SG_ 2348982446 SBCU14_DO1_Ctrl 1;
BA_ "GenSigMaxValue" SG_ 2348982446 SBCU14_DO1_Ctrl 1;
BA_ "GenSigSendType" SG_ 2348982446 SBCU14_DI5_Status 1;
BA_ "GenSigMaxValue" SG_ 2348982446 SBCU14_DI5_Status 1;
BA_ "GenSigSendType" SG_ 2348982446 SBCU14_DI4_Status 1;
BA_ "GenSigMaxValue" SG_ 2348982446 SBCU14_DI4_Status 1;
BA_ "GenSigSendType" SG_ 2348982446 SBCU14_DI3_Status 1;
BA_ "GenSigMaxValue" SG_ 2348982446 SBCU14_DI3_Status 1;
BA_ "GenSigSendType" SG_ 2348982446 SBCU14_DI2_Status 1;
BA_ "GenSigMaxValue" SG_ 2348982446 SBCU14_DI2_Status 1;
BA_ "GenSigSendType" SG_ 2348982446 SBCU14_DI1_Status 1;
BA_ "GenSigMaxValue" SG_ 2348982446 SBCU14_DI1_Status 1;
BA_ "GenSigSendType" SG_ 2348982446 SBCU14_BMS_RunStatus 1;
BA_ "GenSigMaxValue" SG_ 2348982446 SBCU14_BMS_RunStatus 15;
BA_ "GenSigSendType" SG_ 2550505646 SBCU14_DchPeakPower_Limit 1;
BA_ "GenSigMaxValue" SG_ 2550505646 SBCU14_DchPeakPower_Limit 65535;
BA_ "GenSigSendType" SG_ 2550505646 SBCU14_DchContinuousPower_Limit 1;
BA_ "GenSigMaxValue" SG_ 2550505646 SBCU14_DchContinuousPower_Limit 65535;
BA_ "GenSigSendType" SG_ 2550505646 SBCU14_ChgPeakPower_Limit 1;
BA_ "GenSigMaxValue" SG_ 2550505646 SBCU14_ChgPeakPower_Limit 65535;
BA_ "GenSigSendType" SG_ 2550505646 SBCU14_ChgContinuousPower_Limit 1;
BA_ "GenSigMaxValue" SG_ 2550505646 SBCU14_ChgContinuousPower_Limit 65535;
BA_ "GenSigSendType" SG_ 2550440110 SBCU14_DchPeakCurr_Limit 1;
BA_ "GenSigMaxValue" SG_ 2550440110 SBCU14_DchPeakCurr_Limit 65535;
BA_ "GenSigSendType" SG_ 2550440110 SBCU14_DchContinuousCurr_Limit 1;
BA_ "GenSigMaxValue" SG_ 2550440110 SBCU14_DchContinuousCurr_Limit 65535;
BA_ "GenSigSendType" SG_ 2550440110 SBCU14_ChgPeakCurr_Limit 1;
BA_ "GenSigMaxValue" SG_ 2550440110 SBCU14_ChgPeakCurr_Limit 65535;
BA_ "GenSigSendType" SG_ 2550440110 SBCU14_ChgContinuousCurr_Limit 1;
BA_ "GenSigMaxValue" SG_ 2550440110 SBCU14_ChgContinuousCurr_Limit 65535;
BA_ "GenSigSendType" SG_ 2550636718 SBCU14_CellVolt_Min_CellNO 1;
BA_ "GenSigMaxValue" SG_ 2550636718 SBCU14_CellVolt_Min_CellNO 255;
BA_ "GenSigSendType" SG_ 2550636718 SBCU14_CellVolt_Min_BMUNO 1;
BA_ "GenSigMaxValue" SG_ 2550636718 SBCU14_CellVolt_Min_BMUNO 255;
BA_ "GenSigSendType" SG_ 2550636718 SBCU14_CellVolt_Max_CellNO 1;
BA_ "GenSigMaxValue" SG_ 2550636718 SBCU14_CellVolt_Max_CellNO 255;
BA_ "GenSigSendType" SG_ 2550636718 SBCU14_CellVolt_Max_BMUNO 1;
BA_ "GenSigMaxValue" SG_ 2550636718 SBCU14_CellVolt_Max_BMUNO 255;
BA_ "GenSigSendType" SG_ 2550636718 SBCU14_CellTemp_Min_CellNO 1;
BA_ "GenSigMaxValue" SG_ 2550636718 SBCU14_CellTemp_Min_CellNO 255;
BA_ "GenSigSendType" SG_ 2550636718 SBCU14_CellTemp_Min_BMUNO 1;
BA_ "GenSigMaxValue" SG_ 2550636718 SBCU14_CellTemp_Min_BMUNO 255;
BA_ "GenSigSendType" SG_ 2550636718 SBCU14_CellTemp_Max_CellNO 1;
BA_ "GenSigMaxValue" SG_ 2550636718 SBCU14_CellTemp_Max_CellNO 255;
BA_ "GenSigSendType" SG_ 2550636718 SBCU14_CellTemp_Max_BMUNO 1;
BA_ "GenSigMaxValue" SG_ 2550636718 SBCU14_CellTemp_Max_BMUNO 255;
BA_ "GenSigSendType" SG_ 2550571182 SBCU14_CellVolt_Min 1;
BA_ "GenSigMaxValue" SG_ 2550571182 SBCU14_CellVolt_Min 65535;
BA_ "GenSigSendType" SG_ 2550571182 SBCU14_CellVolt_Mean 1;
BA_ "GenSigMaxValue" SG_ 2550571182 SBCU14_CellVolt_Mean 65535;
BA_ "GenSigSendType" SG_ 2550571182 SBCU14_CellVolt_Max 1;
BA_ "GenSigMaxValue" SG_ 2550571182 SBCU14_CellVolt_Max 65535;
BA_ "GenSigSendType" SG_ 2550571182 SBCU14_CellTemp_Min 1;
BA_ "GenSigMaxValue" SG_ 2550571182 SBCU14_CellTemp_Min 255;
BA_ "GenSigSendType" SG_ 2550571182 SBCU14_CellTemp_Max 1;
BA_ "GenSigMaxValue" SG_ 2550571182 SBCU14_CellTemp_Max 255;
BA_ "GenSigSendType" SG_ 2550702254 SBCU14_NTC2 1;
BA_ "GenSigMaxValue" SG_ 2550702254 SBCU14_NTC2 255;
BA_ "GenSigSendType" SG_ 2550702254 SBCU14_NTC1 1;
BA_ "GenSigMaxValue" SG_ 2550702254 SBCU14_NTC1 255;
BA_ "GenSigSendType" SG_ 2550702254 SBCU14_ISO_PosVolt 1;
BA_ "GenSigMaxValue" SG_ 2550702254 SBCU14_ISO_PosVolt 65535;
BA_ "GenSigSendType" SG_ 2550702254 SBCU14_ISO_NegVolt 1;
BA_ "GenSigMaxValue" SG_ 2550702254 SBCU14_ISO_NegVolt 65535;
BA_ "GenSigSendType" SG_ 2550702254 SBCU14_CellVolt_Sum 1;
BA_ "GenSigMaxValue" SG_ 2550702254 SBCU14_CellVolt_Sum 65535;
BA_ "GenSigSendType" SG_ 2566652078 SBCU14_CellBalance_Pack_NO 1;
BA_ "GenSigMaxValue" SG_ 2566652078 SBCU14_CellBalance_Pack_NO 255;
BA_ "GenSigSendType" SG_ 2566652078 SBCU14_CellBalance049 1;
BA_ "GenSigMaxValue" SG_ 2566652078 SBCU14_CellBalance049 255;
BA_ "GenSigSendType" SG_ 2566652078 SBCU14_CellBalance041 1;
BA_ "GenSigMaxValue" SG_ 2566652078 SBCU14_CellBalance041 255;
BA_ "GenSigSendType" SG_ 2566652078 SBCU14_CellBalance033 1;
BA_ "GenSigMaxValue" SG_ 2566652078 SBCU14_CellBalance033 255;
BA_ "GenSigSendType" SG_ 2566652078 SBCU14_CellBalance025 1;
BA_ "GenSigMaxValue" SG_ 2566652078 SBCU14_CellBalance025 255;
BA_ "GenSigSendType" SG_ 2566652078 SBCU14_CellBalance017 1;
BA_ "GenSigMaxValue" SG_ 2566652078 SBCU14_CellBalance017 255;
BA_ "GenSigSendType" SG_ 2566652078 SBCU14_CellBalance009 1;
BA_ "GenSigMaxValue" SG_ 2566652078 SBCU14_CellBalance009 255;
BA_ "GenSigSendType" SG_ 2566652078 SBCU14_CellBalance001 1;
BA_ "GenSigMaxValue" SG_ 2566652078 SBCU14_CellBalance001 255;
BA_ "GenSigSendType" SG_ 2565865646 SBCU14_CellVolt2_CellNO 1;
BA_ "GenSigMaxValue" SG_ 2565865646 SBCU14_CellVolt2_CellNO 255;
BA_ "GenSigSendType" SG_ 2565865646 SBCU14_CellVolt2_BMUNO 1;
BA_ "GenSigMaxValue" SG_ 2565865646 SBCU14_CellVolt2_BMUNO 255;
BA_ "GenSigSendType" SG_ 2565865646 SBCU14_CellVolt2 1;
BA_ "GenSigMaxValue" SG_ 2565865646 SBCU14_CellVolt2 65535;
BA_ "GenSigSendType" SG_ 2565865646 SBCU14_CellVolt1_CellNO 1;
BA_ "GenSigMaxValue" SG_ 2565865646 SBCU14_CellVolt1_CellNO 255;
BA_ "GenSigSendType" SG_ 2565865646 SBCU14_CellVolt1_BMUNO 1;
BA_ "GenSigMaxValue" SG_ 2565865646 SBCU14_CellVolt1_BMUNO 255;
BA_ "GenSigSendType" SG_ 2565865646 SBCU14_CellVolt1 1;
BA_ "GenSigMaxValue" SG_ 2565865646 SBCU14_CellVolt1 65535;
BA_ "GenSigSendType" SG_ 2550243502 SBCU14_SOC 1;
BA_ "GenSigMaxValue" SG_ 2550243502 SBCU14_SOC 65535;
BA_ "GenSigSendType" SG_ 2550243502 SBCU14_Pack_Volt 1;
BA_ "GenSigMaxValue" SG_ 2550243502 SBCU14_Pack_Volt 65535;
BA_ "GenSigSendType" SG_ 2550243502 SBCU14_LinkVolt 1;
BA_ "GenSigMaxValue" SG_ 2550243502 SBCU14_LinkVolt 65535;
BA_ "GenSigSendType" SG_ 2550243502 SBCU14_BusCurrent 1;
BA_ "GenSigMaxValue" SG_ 2550243502 SBCU14_BusCurrent 65535;
BA_ "GenSigStartValue" SG_ 2550243502 SBCU14_BusCurrent 32000;
BA_ "GenSigSendType" SG_ 2566389933 SBCU13_CellTemp_Rev 1;
BA_ "GenSigMaxValue" SG_ 2566389933 SBCU13_CellTemp_Rev 65535;
BA_ "GenSigSendType" SG_ 2566389933 SBCU13_CellTemp2_CellNO 1;
BA_ "GenSigMaxValue" SG_ 2566389933 SBCU13_CellTemp2_CellNO 255;
BA_ "GenSigSendType" SG_ 2566389933 SBCU13_CellTemp2_BMUNO 1;
BA_ "GenSigMaxValue" SG_ 2566389933 SBCU13_CellTemp2_BMUNO 255;
BA_ "GenSigSendType" SG_ 2566389933 SBCU13_CellTemp2 1;
BA_ "GenSigMaxValue" SG_ 2566389933 SBCU13_CellTemp2 255;
BA_ "GenSigSendType" SG_ 2566389933 SBCU13_CellTemp1_CellNO 1;
BA_ "GenSigMaxValue" SG_ 2566389933 SBCU13_CellTemp1_CellNO 255;
BA_ "GenSigSendType" SG_ 2566389933 SBCU13_CellTemp1_BMUNO 1;
BA_ "GenSigMaxValue" SG_ 2566389933 SBCU13_CellTemp1_BMUNO 255;
BA_ "GenSigSendType" SG_ 2566389933 SBCU13_CellTemp1 1;
BA_ "GenSigMaxValue" SG_ 2566389933 SBCU13_CellTemp1 255;
BA_ "GenSigSendType" SG_ 2550898861 SBCU13_Accum_DchEng 1;
BA_ "GenSigMaxValue" SG_ 2550898861 SBCU13_Accum_DchEng 2147483647;
BA_ "GenSigSendType" SG_ 2550898861 SBCU13_Accum_ChgEng 1;
BA_ "GenSigMaxValue" SG_ 2550898861 SBCU13_Accum_ChgEng 2147483647;
BA_ "GenSigSendType" SG_ 2550833325 SBCU13_Accum_DchCap 1;
BA_ "GenSigMaxValue" SG_ 2550833325 SBCU13_Accum_DchCap 2147483647;
BA_ "GenSigSendType" SG_ 2550833325 SBCU13_Accum_ChgCap 1;
BA_ "GenSigMaxValue" SG_ 2550833325 SBCU13_Accum_ChgCap 2147483647;
BA_ "GenSigSendType" SG_ 2550374573 SBCU13_SOH 1;
BA_ "GenSigMaxValue" SG_ 2550374573 SBCU13_SOH 4095;
BA_ "GenSigSendType" SG_ 2550374573 SBCU13_PowerSupply_Volt 1;
BA_ "GenSigMaxValue" SG_ 2550374573 SBCU13_PowerSupply_Volt 4095;
BA_ "GenSigSendType" SG_ 2550374573 SBCU13_Isolation 1;
BA_ "GenSigMaxValue" SG_ 2550374573 SBCU13_Isolation 65535;
BA_ "GenSigSendType" SG_ 2550374573 SBCU13_AI3_Value 1;
BA_ "GenSigMaxValue" SG_ 2550374573 SBCU13_AI3_Value 255;
BA_ "GenSigSendType" SG_ 2550374573 SBCU13_AI2_Value 1;
BA_ "GenSigMaxValue" SG_ 2550374573 SBCU13_AI2_Value 255;
BA_ "GenSigSendType" SG_ 2550374573 SBCU13_AI1_Value 1;
BA_ "GenSigMaxValue" SG_ 2550374573 SBCU13_AI1_Value 255;
BA_ "GenSigSendType" SG_ 2348982445 SBCU13_WorkMode 1;
BA_ "GenSigMaxValue" SG_ 2348982445 SBCU13_WorkMode 15;
BA_ "GenSigSendType" SG_ 2348982445 SBCU13_Ready 1;
BA_ "GenSigMaxValue" SG_ 2348982445 SBCU13_Ready 3;
BA_ "GenSigSendType" SG_ 2348982445 SBCU13_PreChgRelay_Status 1;
BA_ "GenSigMaxValue" SG_ 2348982445 SBCU13_PreChgRelay_Status 3;
BA_ "GenSigSendType" SG_ 2348982445 SBCU13_PosRelay_Status 1;
BA_ "GenSigMaxValue" SG_ 2348982445 SBCU13_PosRelay_Status 3;
BA_ "GenSigSendType" SG_ 2348982445 SBCU13_PosIso_Optical 1;
BA_ "GenSigMaxValue" SG_ 2348982445 SBCU13_PosIso_Optical 1;
BA_ "GenSigSendType" SG_ 2348982445 SBCU13_NegRelay_Status 1;
BA_ "GenSigMaxValue" SG_ 2348982445 SBCU13_NegRelay_Status 3;
BA_ "GenSigSendType" SG_ 2348982445 SBCU13_NegIso_Optical 1;
BA_ "GenSigMaxValue" SG_ 2348982445 SBCU13_NegIso_Optical 1;
BA_ "GenSigSendType" SG_ 2348982445 SBCU13_Life 1;
BA_ "GenSigMaxValue" SG_ 2348982445 SBCU13_Life 15;
BA_ "GenSigSendType" SG_ 2348982445 SBCU13_ISO_Status 1;
BA_ "GenSigMaxValue" SG_ 2348982445 SBCU13_ISO_Status 3;
BA_ "GenSigSendType" SG_ 2348982445 SBCU13_ISO_Allow 1;
BA_ "GenSigMaxValue" SG_ 2348982445 SBCU13_ISO_Allow 3;
BA_ "GenSigSendType" SG_ 2348982445 SBCU13_HVOff_Req 1;
BA_ "GenSigMaxValue" SG_ 2348982445 SBCU13_HVOff_Req 3;
BA_ "GenSigSendType" SG_ 2348982445 SBCU13_HV_Step 1;
BA_ "GenSigMaxValue" SG_ 2348982445 SBCU13_HV_Step 15;
BA_ "GenSigSendType" SG_ 2348982445 SBCU13_HeatRelay_Status 1;
BA_ "GenSigMaxValue" SG_ 2348982445 SBCU13_HeatRelay_Status 3;
BA_ "GenSigSendType" SG_ 2348982445 SBCU13_FcgRelay_Status 1;
BA_ "GenSigMaxValue" SG_ 2348982445 SBCU13_FcgRelay_Status 3;
BA_ "GenSigSendType" SG_ 2348982445 SBCU13_FaultLevel 1;
BA_ "GenSigMaxValue" SG_ 2348982445 SBCU13_FaultLevel 3;
BA_ "GenSigSendType" SG_ 2348982445 SBCU13_FaultCode 1;
BA_ "GenSigMaxValue" SG_ 2348982445 SBCU13_FaultCode 65535;
BA_ "GenSigSendType" SG_ 2348982445 SBCU13_FanRelay_Status 1;
BA_ "GenSigMaxValue" SG_ 2348982445 SBCU13_FanRelay_Status 3;
BA_ "GenSigSendType" SG_ 2348982445 SBCU13_DO3_Ctrl 1;
BA_ "GenSigMaxValue" SG_ 2348982445 SBCU13_DO3_Ctrl 1;
BA_ "GenSigSendType" SG_ 2348982445 SBCU13_DO2_Ctrl 1;
BA_ "GenSigMaxValue" SG_ 2348982445 SBCU13_DO2_Ctrl 1;
BA_ "GenSigSendType" SG_ 2348982445 SBCU13_DO1_Ctrl 1;
BA_ "GenSigMaxValue" SG_ 2348982445 SBCU13_DO1_Ctrl 1;
BA_ "GenSigSendType" SG_ 2348982445 SBCU13_DI5_Status 1;
BA_ "GenSigMaxValue" SG_ 2348982445 SBCU13_DI5_Status 1;
BA_ "GenSigSendType" SG_ 2348982445 SBCU13_DI4_Status 1;
BA_ "GenSigMaxValue" SG_ 2348982445 SBCU13_DI4_Status 1;
BA_ "GenSigSendType" SG_ 2348982445 SBCU13_DI3_Status 1;
BA_ "GenSigMaxValue" SG_ 2348982445 SBCU13_DI3_Status 1;
BA_ "GenSigSendType" SG_ 2348982445 SBCU13_DI2_Status 1;
BA_ "GenSigMaxValue" SG_ 2348982445 SBCU13_DI2_Status 1;
BA_ "GenSigSendType" SG_ 2348982445 SBCU13_DI1_Status 1;
BA_ "GenSigMaxValue" SG_ 2348982445 SBCU13_DI1_Status 1;
BA_ "GenSigSendType" SG_ 2348982445 SBCU13_BMS_RunStatus 1;
BA_ "GenSigMaxValue" SG_ 2348982445 SBCU13_BMS_RunStatus 15;
BA_ "GenSigSendType" SG_ 2550505645 SBCU13_DchPeakPower_Limit 1;
BA_ "GenSigMaxValue" SG_ 2550505645 SBCU13_DchPeakPower_Limit 65535;
BA_ "GenSigSendType" SG_ 2550505645 SBCU13_DchContinuousPower_Limit 1;
BA_ "GenSigMaxValue" SG_ 2550505645 SBCU13_DchContinuousPower_Limit 65535;
BA_ "GenSigSendType" SG_ 2550505645 SBCU13_ChgPeakPower_Limit 1;
BA_ "GenSigMaxValue" SG_ 2550505645 SBCU13_ChgPeakPower_Limit 65535;
BA_ "GenSigSendType" SG_ 2550505645 SBCU13_ChgContinuousPower_Limit 1;
BA_ "GenSigMaxValue" SG_ 2550505645 SBCU13_ChgContinuousPower_Limit 65535;
BA_ "GenSigSendType" SG_ 2550440109 SBCU13_DchPeakCurr_Limit 1;
BA_ "GenSigMaxValue" SG_ 2550440109 SBCU13_DchPeakCurr_Limit 65535;
BA_ "GenSigSendType" SG_ 2550440109 SBCU13_DchContinuousCurr_Limit 1;
BA_ "GenSigMaxValue" SG_ 2550440109 SBCU13_DchContinuousCurr_Limit 65535;
BA_ "GenSigSendType" SG_ 2550440109 SBCU13_ChgPeakCurr_Limit 1;
BA_ "GenSigMaxValue" SG_ 2550440109 SBCU13_ChgPeakCurr_Limit 65535;
BA_ "GenSigSendType" SG_ 2550440109 SBCU13_ChgContinuousCurr_Limit 1;
BA_ "GenSigMaxValue" SG_ 2550440109 SBCU13_ChgContinuousCurr_Limit 65535;
BA_ "GenSigSendType" SG_ 2550636717 SBCU13_CellVolt_Min_CellNO 1;
BA_ "GenSigMaxValue" SG_ 2550636717 SBCU13_CellVolt_Min_CellNO 255;
BA_ "GenSigSendType" SG_ 2550636717 SBCU13_CellVolt_Min_BMUNO 1;
BA_ "GenSigMaxValue" SG_ 2550636717 SBCU13_CellVolt_Min_BMUNO 255;
BA_ "GenSigSendType" SG_ 2550636717 SBCU13_CellVolt_Max_CellNO 1;
BA_ "GenSigMaxValue" SG_ 2550636717 SBCU13_CellVolt_Max_CellNO 255;
BA_ "GenSigSendType" SG_ 2550636717 SBCU13_CellVolt_Max_BMUNO 1;
BA_ "GenSigMaxValue" SG_ 2550636717 SBCU13_CellVolt_Max_BMUNO 255;
BA_ "GenSigSendType" SG_ 2550636717 SBCU13_CellTemp_Min_CellNO 1;
BA_ "GenSigMaxValue" SG_ 2550636717 SBCU13_CellTemp_Min_CellNO 255;
BA_ "GenSigSendType" SG_ 2550636717 SBCU13_CellTemp_Min_BMUNO 1;
BA_ "GenSigMaxValue" SG_ 2550636717 SBCU13_CellTemp_Min_BMUNO 255;
BA_ "GenSigSendType" SG_ 2550636717 SBCU13_CellTemp_Max_CellNO 1;
BA_ "GenSigMaxValue" SG_ 2550636717 SBCU13_CellTemp_Max_CellNO 255;
BA_ "GenSigSendType" SG_ 2550636717 SBCU13_CellTemp_Max_BMUNO 1;
BA_ "GenSigMaxValue" SG_ 2550636717 SBCU13_CellTemp_Max_BMUNO 255;
BA_ "GenSigSendType" SG_ 2550571181 SBCU13_CellVolt_Min 1;
BA_ "GenSigMaxValue" SG_ 2550571181 SBCU13_CellVolt_Min 65535;
BA_ "GenSigSendType" SG_ 2550571181 SBCU13_CellVolt_Mean 1;
BA_ "GenSigMaxValue" SG_ 2550571181 SBCU13_CellVolt_Mean 65535;
BA_ "GenSigSendType" SG_ 2550571181 SBCU13_CellVolt_Max 1;
BA_ "GenSigMaxValue" SG_ 2550571181 SBCU13_CellVolt_Max 65535;
BA_ "GenSigSendType" SG_ 2550571181 SBCU13_CellTemp_Min 1;
BA_ "GenSigMaxValue" SG_ 2550571181 SBCU13_CellTemp_Min 255;
BA_ "GenSigSendType" SG_ 2550571181 SBCU13_CellTemp_Max 1;
BA_ "GenSigMaxValue" SG_ 2550571181 SBCU13_CellTemp_Max 255;
BA_ "GenSigSendType" SG_ 2550702253 SBCU13_NTC2 1;
BA_ "GenSigMaxValue" SG_ 2550702253 SBCU13_NTC2 255;
BA_ "GenSigSendType" SG_ 2550702253 SBCU13_NTC1 1;
BA_ "GenSigMaxValue" SG_ 2550702253 SBCU13_NTC1 255;
BA_ "GenSigSendType" SG_ 2550702253 SBCU13_ISO_PosVolt 1;
BA_ "GenSigMaxValue" SG_ 2550702253 SBCU13_ISO_PosVolt 65535;
BA_ "GenSigSendType" SG_ 2550702253 SBCU13_ISO_NegVolt 1;
BA_ "GenSigMaxValue" SG_ 2550702253 SBCU13_ISO_NegVolt 65535;
BA_ "GenSigSendType" SG_ 2550702253 SBCU13_CellVolt_Sum 1;
BA_ "GenSigMaxValue" SG_ 2550702253 SBCU13_CellVolt_Sum 65535;
BA_ "GenSigSendType" SG_ 2566652077 SBCU13_CellBalance_Pack_NO 1;
BA_ "GenSigMaxValue" SG_ 2566652077 SBCU13_CellBalance_Pack_NO 255;
BA_ "GenSigSendType" SG_ 2566652077 SBCU13_CellBalance049 1;
BA_ "GenSigMaxValue" SG_ 2566652077 SBCU13_CellBalance049 255;
BA_ "GenSigSendType" SG_ 2566652077 SBCU13_CellBalance041 1;
BA_ "GenSigMaxValue" SG_ 2566652077 SBCU13_CellBalance041 255;
BA_ "GenSigSendType" SG_ 2566652077 SBCU13_CellBalance033 1;
BA_ "GenSigMaxValue" SG_ 2566652077 SBCU13_CellBalance033 255;
BA_ "GenSigSendType" SG_ 2566652077 SBCU13_CellBalance025 1;
BA_ "GenSigMaxValue" SG_ 2566652077 SBCU13_CellBalance025 255;
BA_ "GenSigSendType" SG_ 2566652077 SBCU13_CellBalance017 1;
BA_ "GenSigMaxValue" SG_ 2566652077 SBCU13_CellBalance017 255;
BA_ "GenSigSendType" SG_ 2566652077 SBCU13_CellBalance009 1;
BA_ "GenSigMaxValue" SG_ 2566652077 SBCU13_CellBalance009 255;
BA_ "GenSigSendType" SG_ 2566652077 SBCU13_CellBalance001 1;
BA_ "GenSigMaxValue" SG_ 2566652077 SBCU13_CellBalance001 255;
BA_ "GenSigSendType" SG_ 2565865645 SBCU13_CellVolt2_CellNO 1;
BA_ "GenSigMaxValue" SG_ 2565865645 SBCU13_CellVolt2_CellNO 255;
BA_ "GenSigSendType" SG_ 2565865645 SBCU13_CellVolt2_BMUNO 1;
BA_ "GenSigMaxValue" SG_ 2565865645 SBCU13_CellVolt2_BMUNO 255;
BA_ "GenSigSendType" SG_ 2565865645 SBCU13_CellVolt2 1;
BA_ "GenSigMaxValue" SG_ 2565865645 SBCU13_CellVolt2 65535;
BA_ "GenSigSendType" SG_ 2565865645 SBCU13_CellVolt1_CellNO 1;
BA_ "GenSigMaxValue" SG_ 2565865645 SBCU13_CellVolt1_CellNO 255;
BA_ "GenSigSendType" SG_ 2565865645 SBCU13_CellVolt1_BMUNO 1;
BA_ "GenSigMaxValue" SG_ 2565865645 SBCU13_CellVolt1_BMUNO 255;
BA_ "GenSigSendType" SG_ 2565865645 SBCU13_CellVolt1 1;
BA_ "GenSigMaxValue" SG_ 2565865645 SBCU13_CellVolt1 65535;
BA_ "GenSigSendType" SG_ 2550243501 SBCU13_SOC 1;
BA_ "GenSigMaxValue" SG_ 2550243501 SBCU13_SOC 65535;
BA_ "GenSigSendType" SG_ 2550243501 SBCU13_Pack_Volt 1;
BA_ "GenSigMaxValue" SG_ 2550243501 SBCU13_Pack_Volt 65535;
BA_ "GenSigSendType" SG_ 2550243501 SBCU13_LinkVolt 1;
BA_ "GenSigMaxValue" SG_ 2550243501 SBCU13_LinkVolt 65535;
BA_ "GenSigSendType" SG_ 2550243501 SBCU13_BusCurrent 1;
BA_ "GenSigMaxValue" SG_ 2550243501 SBCU13_BusCurrent 65535;
BA_ "GenSigStartValue" SG_ 2550243501 SBCU13_BusCurrent 32000;
BA_ "GenSigSendType" SG_ 2566389932 SBCU12_CellTemp_Rev 1;
BA_ "GenSigMaxValue" SG_ 2566389932 SBCU12_CellTemp_Rev 65535;
BA_ "GenSigSendType" SG_ 2566389932 SBCU12_CellTemp2_CellNO 1;
BA_ "GenSigMaxValue" SG_ 2566389932 SBCU12_CellTemp2_CellNO 255;
BA_ "GenSigSendType" SG_ 2566389932 SBCU12_CellTemp2_BMUNO 1;
BA_ "GenSigMaxValue" SG_ 2566389932 SBCU12_CellTemp2_BMUNO 255;
BA_ "GenSigSendType" SG_ 2566389932 SBCU12_CellTemp2 1;
BA_ "GenSigMaxValue" SG_ 2566389932 SBCU12_CellTemp2 255;
BA_ "GenSigSendType" SG_ 2566389932 SBCU12_CellTemp1_CellNO 1;
BA_ "GenSigMaxValue" SG_ 2566389932 SBCU12_CellTemp1_CellNO 255;
BA_ "GenSigSendType" SG_ 2566389932 SBCU12_CellTemp1_BMUNO 1;
BA_ "GenSigMaxValue" SG_ 2566389932 SBCU12_CellTemp1_BMUNO 255;
BA_ "GenSigSendType" SG_ 2566389932 SBCU12_CellTemp1 1;
BA_ "GenSigMaxValue" SG_ 2566389932 SBCU12_CellTemp1 255;
BA_ "GenSigSendType" SG_ 2550898860 SBCU12_Accum_DchEng 1;
BA_ "GenSigMaxValue" SG_ 2550898860 SBCU12_Accum_DchEng 2147483647;
BA_ "GenSigSendType" SG_ 2550898860 SBCU12_Accum_ChgEng 1;
BA_ "GenSigMaxValue" SG_ 2550898860 SBCU12_Accum_ChgEng 2147483647;
BA_ "GenSigSendType" SG_ 2550833324 SBCU12_Accum_DchCap 1;
BA_ "GenSigMaxValue" SG_ 2550833324 SBCU12_Accum_DchCap 2147483647;
BA_ "GenSigSendType" SG_ 2550833324 SBCU12_Accum_ChgCap 1;
BA_ "GenSigMaxValue" SG_ 2550833324 SBCU12_Accum_ChgCap 2147483647;
BA_ "GenSigSendType" SG_ 2550374572 SBCU12_SOH 1;
BA_ "GenSigMaxValue" SG_ 2550374572 SBCU12_SOH 4095;
BA_ "GenSigSendType" SG_ 2550374572 SBCU12_PowerSupply_Volt 1;
BA_ "GenSigMaxValue" SG_ 2550374572 SBCU12_PowerSupply_Volt 4095;
BA_ "GenSigSendType" SG_ 2550374572 SBCU12_Isolation 1;
BA_ "GenSigMaxValue" SG_ 2550374572 SBCU12_Isolation 65535;
BA_ "GenSigSendType" SG_ 2550374572 SBCU12_AI3_Value 1;
BA_ "GenSigMaxValue" SG_ 2550374572 SBCU12_AI3_Value 255;
BA_ "GenSigSendType" SG_ 2550374572 SBCU12_AI2_Value 1;
BA_ "GenSigMaxValue" SG_ 2550374572 SBCU12_AI2_Value 255;
BA_ "GenSigSendType" SG_ 2550374572 SBCU12_AI1_Value 1;
BA_ "GenSigMaxValue" SG_ 2550374572 SBCU12_AI1_Value 255;
BA_ "GenSigSendType" SG_ 2348982444 SBCU12_WorkMode 1;
BA_ "GenSigMaxValue" SG_ 2348982444 SBCU12_WorkMode 15;
BA_ "GenSigSendType" SG_ 2348982444 SBCU12_Ready 1;
BA_ "GenSigMaxValue" SG_ 2348982444 SBCU12_Ready 3;
BA_ "GenSigSendType" SG_ 2348982444 SBCU12_PreChgRelay_Status 1;
BA_ "GenSigMaxValue" SG_ 2348982444 SBCU12_PreChgRelay_Status 3;
BA_ "GenSigSendType" SG_ 2348982444 SBCU12_PosRelay_Status 1;
BA_ "GenSigMaxValue" SG_ 2348982444 SBCU12_PosRelay_Status 3;
BA_ "GenSigSendType" SG_ 2348982444 SBCU12_PosIso_Optical 1;
BA_ "GenSigMaxValue" SG_ 2348982444 SBCU12_PosIso_Optical 1;
BA_ "GenSigSendType" SG_ 2348982444 SBCU12_NegRelay_Status 1;
BA_ "GenSigMaxValue" SG_ 2348982444 SBCU12_NegRelay_Status 3;
BA_ "GenSigSendType" SG_ 2348982444 SBCU12_NegIso_Optical 1;
BA_ "GenSigMaxValue" SG_ 2348982444 SBCU12_NegIso_Optical 1;
BA_ "GenSigSendType" SG_ 2348982444 SBCU12_Life 1;
BA_ "GenSigMaxValue" SG_ 2348982444 SBCU12_Life 15;
BA_ "GenSigSendType" SG_ 2348982444 SBCU12_ISO_Status 1;
BA_ "GenSigMaxValue" SG_ 2348982444 SBCU12_ISO_Status 3;
BA_ "GenSigSendType" SG_ 2348982444 SBCU12_ISO_Allow 1;
BA_ "GenSigMaxValue" SG_ 2348982444 SBCU12_ISO_Allow 3;
BA_ "GenSigSendType" SG_ 2348982444 SBCU12_HVOff_Req 1;
BA_ "GenSigMaxValue" SG_ 2348982444 SBCU12_HVOff_Req 3;
BA_ "GenSigSendType" SG_ 2348982444 SBCU12_HV_Step 1;
BA_ "GenSigMaxValue" SG_ 2348982444 SBCU12_HV_Step 15;
BA_ "GenSigSendType" SG_ 2348982444 SBCU12_HeatRelay_Status 1;
BA_ "GenSigMaxValue" SG_ 2348982444 SBCU12_HeatRelay_Status 3;
BA_ "GenSigSendType" SG_ 2348982444 SBCU12_FcgRelay_Status 1;
BA_ "GenSigMaxValue" SG_ 2348982444 SBCU12_FcgRelay_Status 3;
BA_ "GenSigSendType" SG_ 2348982444 SBCU12_FaultLevel 1;
BA_ "GenSigMaxValue" SG_ 2348982444 SBCU12_FaultLevel 3;
BA_ "GenSigSendType" SG_ 2348982444 SBCU12_FaultCode 1;
BA_ "GenSigMaxValue" SG_ 2348982444 SBCU12_FaultCode 65535;
BA_ "GenSigSendType" SG_ 2348982444 SBCU12_FanRelay_Status 1;
BA_ "GenSigMaxValue" SG_ 2348982444 SBCU12_FanRelay_Status 3;
BA_ "GenSigSendType" SG_ 2348982444 SBCU12_DO3_Ctrl 1;
BA_ "GenSigMaxValue" SG_ 2348982444 SBCU12_DO3_Ctrl 1;
BA_ "GenSigSendType" SG_ 2348982444 SBCU12_DO2_Ctrl 1;
BA_ "GenSigMaxValue" SG_ 2348982444 SBCU12_DO2_Ctrl 1;
BA_ "GenSigSendType" SG_ 2348982444 SBCU12_DO1_Ctrl 1;
BA_ "GenSigMaxValue" SG_ 2348982444 SBCU12_DO1_Ctrl 1;
BA_ "GenSigSendType" SG_ 2348982444 SBCU12_DI5_Status 1;
BA_ "GenSigMaxValue" SG_ 2348982444 SBCU12_DI5_Status 1;
BA_ "GenSigSendType" SG_ 2348982444 SBCU12_DI4_Status 1;
BA_ "GenSigMaxValue" SG_ 2348982444 SBCU12_DI4_Status 1;
BA_ "GenSigSendType" SG_ 2348982444 SBCU12_DI3_Status 1;
BA_ "GenSigMaxValue" SG_ 2348982444 SBCU12_DI3_Status 1;
BA_ "GenSigSendType" SG_ 2348982444 SBCU12_DI2_Status 1;
BA_ "GenSigMaxValue" SG_ 2348982444 SBCU12_DI2_Status 1;
BA_ "GenSigSendType" SG_ 2348982444 SBCU12_DI1_Status 1;
BA_ "GenSigMaxValue" SG_ 2348982444 SBCU12_DI1_Status 1;
BA_ "GenSigSendType" SG_ 2348982444 SBCU12_BMS_RunStatus 1;
BA_ "GenSigMaxValue" SG_ 2348982444 SBCU12_BMS_RunStatus 15;
BA_ "GenSigSendType" SG_ 2550505644 SBCU12_DchPeakPower_Limit 1;
BA_ "GenSigMaxValue" SG_ 2550505644 SBCU12_DchPeakPower_Limit 65535;
BA_ "GenSigSendType" SG_ 2550505644 SBCU12_DchContinuousPower_Limit 1;
BA_ "GenSigMaxValue" SG_ 2550505644 SBCU12_DchContinuousPower_Limit 65535;
BA_ "GenSigSendType" SG_ 2550505644 SBCU12_ChgPeakPower_Limit 1;
BA_ "GenSigMaxValue" SG_ 2550505644 SBCU12_ChgPeakPower_Limit 65535;
BA_ "GenSigSendType" SG_ 2550505644 SBCU12_ChgContinuousPower_Limit 1;
BA_ "GenSigMaxValue" SG_ 2550505644 SBCU12_ChgContinuousPower_Limit 65535;
BA_ "GenSigSendType" SG_ 2550440108 SBCU12_DchPeakCurr_Limit 1;
BA_ "GenSigMaxValue" SG_ 2550440108 SBCU12_DchPeakCurr_Limit 65535;
BA_ "GenSigSendType" SG_ 2550440108 SBCU12_DchContinuousCurr_Limit 1;
BA_ "GenSigMaxValue" SG_ 2550440108 SBCU12_DchContinuousCurr_Limit 65535;
BA_ "GenSigSendType" SG_ 2550440108 SBCU12_ChgPeakCurr_Limit 1;
BA_ "GenSigMaxValue" SG_ 2550440108 SBCU12_ChgPeakCurr_Limit 65535;
BA_ "GenSigSendType" SG_ 2550440108 SBCU12_ChgContinuousCurr_Limit 1;
BA_ "GenSigMaxValue" SG_ 2550440108 SBCU12_ChgContinuousCurr_Limit 65535;
BA_ "GenSigSendType" SG_ 2550636716 SBCU12_CellVolt_Min_CellNO 1;
BA_ "GenSigMaxValue" SG_ 2550636716 SBCU12_CellVolt_Min_CellNO 255;
BA_ "GenSigSendType" SG_ 2550636716 SBCU12_CellVolt_Min_BMUNO 1;
BA_ "GenSigMaxValue" SG_ 2550636716 SBCU12_CellVolt_Min_BMUNO 255;
BA_ "GenSigSendType" SG_ 2550636716 SBCU12_CellVolt_Max_CellNO 1;
BA_ "GenSigMaxValue" SG_ 2550636716 SBCU12_CellVolt_Max_CellNO 255;
BA_ "GenSigSendType" SG_ 2550636716 SBCU12_CellVolt_Max_BMUNO 1;
BA_ "GenSigMaxValue" SG_ 2550636716 SBCU12_CellVolt_Max_BMUNO 255;
BA_ "GenSigSendType" SG_ 2550636716 SBCU12_CellTemp_Min_CellNO 1;
BA_ "GenSigMaxValue" SG_ 2550636716 SBCU12_CellTemp_Min_CellNO 255;
BA_ "GenSigSendType" SG_ 2550636716 SBCU12_CellTemp_Min_BMUNO 1;
BA_ "GenSigMaxValue" SG_ 2550636716 SBCU12_CellTemp_Min_BMUNO 255;
BA_ "GenSigSendType" SG_ 2550636716 SBCU12_CellTemp_Max_CellNO 1;
BA_ "GenSigMaxValue" SG_ 2550636716 SBCU12_CellTemp_Max_CellNO 255;
BA_ "GenSigSendType" SG_ 2550636716 SBCU12_CellTemp_Max_BMUNO 1;
BA_ "GenSigMaxValue" SG_ 2550636716 SBCU12_CellTemp_Max_BMUNO 255;
BA_ "GenSigSendType" SG_ 2550571180 SBCU12_CellVolt_Min 1;
BA_ "GenSigMaxValue" SG_ 2550571180 SBCU12_CellVolt_Min 65535;
BA_ "GenSigSendType" SG_ 2550571180 SBCU12_CellVolt_Mean 1;
BA_ "GenSigMaxValue" SG_ 2550571180 SBCU12_CellVolt_Mean 65535;
BA_ "GenSigSendType" SG_ 2550571180 SBCU12_CellVolt_Max 1;
BA_ "GenSigMaxValue" SG_ 2550571180 SBCU12_CellVolt_Max 65535;
BA_ "GenSigSendType" SG_ 2550571180 SBCU12_CellTemp_Min 1;
BA_ "GenSigMaxValue" SG_ 2550571180 SBCU12_CellTemp_Min 255;
BA_ "GenSigSendType" SG_ 2550571180 SBCU12_CellTemp_Max 1;
BA_ "GenSigMaxValue" SG_ 2550571180 SBCU12_CellTemp_Max 255;
BA_ "GenSigSendType" SG_ 2550702252 SBCU12_NTC2 1;
BA_ "GenSigMaxValue" SG_ 2550702252 SBCU12_NTC2 255;
BA_ "GenSigSendType" SG_ 2550702252 SBCU12_NTC1 1;
BA_ "GenSigMaxValue" SG_ 2550702252 SBCU12_NTC1 255;
BA_ "GenSigSendType" SG_ 2550702252 SBCU12_ISO_PosVolt 1;
BA_ "GenSigMaxValue" SG_ 2550702252 SBCU12_ISO_PosVolt 65535;
BA_ "GenSigSendType" SG_ 2550702252 SBCU12_ISO_NegVolt 1;
BA_ "GenSigMaxValue" SG_ 2550702252 SBCU12_ISO_NegVolt 65535;
BA_ "GenSigSendType" SG_ 2550702252 SBCU12_CellVolt_Sum 1;
BA_ "GenSigMaxValue" SG_ 2550702252 SBCU12_CellVolt_Sum 65535;
BA_ "GenSigSendType" SG_ 2566652076 SBCU12_CellBalance_Pack_NO 1;
BA_ "GenSigMaxValue" SG_ 2566652076 SBCU12_CellBalance_Pack_NO 255;
BA_ "GenSigSendType" SG_ 2566652076 SBCU12_CellBalance049 1;
BA_ "GenSigMaxValue" SG_ 2566652076 SBCU12_CellBalance049 255;
BA_ "GenSigSendType" SG_ 2566652076 SBCU12_CellBalance041 1;
BA_ "GenSigMaxValue" SG_ 2566652076 SBCU12_CellBalance041 255;
BA_ "GenSigSendType" SG_ 2566652076 SBCU12_CellBalance033 1;
BA_ "GenSigMaxValue" SG_ 2566652076 SBCU12_CellBalance033 255;
BA_ "GenSigSendType" SG_ 2566652076 SBCU12_CellBalance025 1;
BA_ "GenSigMaxValue" SG_ 2566652076 SBCU12_CellBalance025 255;
BA_ "GenSigSendType" SG_ 2566652076 SBCU12_CellBalance017 1;
BA_ "GenSigMaxValue" SG_ 2566652076 SBCU12_CellBalance017 255;
BA_ "GenSigSendType" SG_ 2566652076 SBCU12_CellBalance009 1;
BA_ "GenSigMaxValue" SG_ 2566652076 SBCU12_CellBalance009 255;
BA_ "GenSigSendType" SG_ 2566652076 SBCU12_CellBalance001 1;
BA_ "GenSigMaxValue" SG_ 2566652076 SBCU12_CellBalance001 255;
BA_ "GenSigSendType" SG_ 2565865644 SBCU12_CellVolt2_CellNO 1;
BA_ "GenSigMaxValue" SG_ 2565865644 SBCU12_CellVolt2_CellNO 255;
BA_ "GenSigSendType" SG_ 2565865644 SBCU12_CellVolt2_BMUNO 1;
BA_ "GenSigMaxValue" SG_ 2565865644 SBCU12_CellVolt2_BMUNO 255;
BA_ "GenSigSendType" SG_ 2565865644 SBCU12_CellVolt2 1;
BA_ "GenSigMaxValue" SG_ 2565865644 SBCU12_CellVolt2 65535;
BA_ "GenSigSendType" SG_ 2565865644 SBCU12_CellVolt1_CellNO 1;
BA_ "GenSigMaxValue" SG_ 2565865644 SBCU12_CellVolt1_CellNO 255;
BA_ "GenSigSendType" SG_ 2565865644 SBCU12_CellVolt1_BMUNO 1;
BA_ "GenSigMaxValue" SG_ 2565865644 SBCU12_CellVolt1_BMUNO 255;
BA_ "GenSigSendType" SG_ 2565865644 SBCU12_CellVolt1 1;
BA_ "GenSigMaxValue" SG_ 2565865644 SBCU12_CellVolt1 65535;
BA_ "GenSigSendType" SG_ 2550243500 SBCU12_SOC 1;
BA_ "GenSigMaxValue" SG_ 2550243500 SBCU12_SOC 65535;
BA_ "GenSigSendType" SG_ 2550243500 SBCU12_Pack_Volt 1;
BA_ "GenSigMaxValue" SG_ 2550243500 SBCU12_Pack_Volt 65535;
BA_ "GenSigSendType" SG_ 2550243500 SBCU12_LinkVolt 1;
BA_ "GenSigMaxValue" SG_ 2550243500 SBCU12_LinkVolt 65535;
BA_ "GenSigSendType" SG_ 2550243500 SBCU12_BusCurrent 1;
BA_ "GenSigMaxValue" SG_ 2550243500 SBCU12_BusCurrent 65535;
BA_ "GenSigStartValue" SG_ 2550243500 SBCU12_BusCurrent 32000;
BA_ "GenSigSendType" SG_ 2550898859 SBCU11_Accum_DchEng 1;
BA_ "GenSigMaxValue" SG_ 2550898859 SBCU11_Accum_DchEng 2147483647;
BA_ "GenSigSendType" SG_ 2550898859 SBCU11_Accum_ChgEng 1;
BA_ "GenSigMaxValue" SG_ 2550898859 SBCU11_Accum_ChgEng 2147483647;
BA_ "GenSigSendType" SG_ 2550833323 SBCU11_Accum_DchCap 1;
BA_ "GenSigMaxValue" SG_ 2550833323 SBCU11_Accum_DchCap 2147483647;
BA_ "GenSigSendType" SG_ 2550833323 SBCU11_Accum_ChgCap 1;
BA_ "GenSigMaxValue" SG_ 2550833323 SBCU11_Accum_ChgCap 2147483647;
BA_ "GenSigSendType" SG_ 2550374571 SBCU11_SOH 1;
BA_ "GenSigMaxValue" SG_ 2550374571 SBCU11_SOH 4095;
BA_ "GenSigSendType" SG_ 2550374571 SBCU11_PowerSupply_Volt 1;
BA_ "GenSigMaxValue" SG_ 2550374571 SBCU11_PowerSupply_Volt 4095;
BA_ "GenSigSendType" SG_ 2550374571 SBCU11_Isolation 1;
BA_ "GenSigMaxValue" SG_ 2550374571 SBCU11_Isolation 65535;
BA_ "GenSigSendType" SG_ 2550374571 SBCU11_AI3_Value 1;
BA_ "GenSigMaxValue" SG_ 2550374571 SBCU11_AI3_Value 255;
BA_ "GenSigSendType" SG_ 2550374571 SBCU11_AI2_Value 1;
BA_ "GenSigMaxValue" SG_ 2550374571 SBCU11_AI2_Value 255;
BA_ "GenSigSendType" SG_ 2550374571 SBCU11_AI1_Value 1;
BA_ "GenSigMaxValue" SG_ 2550374571 SBCU11_AI1_Value 255;
BA_ "GenSigSendType" SG_ 2348982443 SBCU11_WorkMode 1;
BA_ "GenSigMaxValue" SG_ 2348982443 SBCU11_WorkMode 15;
BA_ "GenSigSendType" SG_ 2348982443 SBCU11_Ready 1;
BA_ "GenSigMaxValue" SG_ 2348982443 SBCU11_Ready 3;
BA_ "GenSigSendType" SG_ 2348982443 SBCU11_PreChgRelay_Status 1;
BA_ "GenSigMaxValue" SG_ 2348982443 SBCU11_PreChgRelay_Status 3;
BA_ "GenSigSendType" SG_ 2348982443 SBCU11_PosRelay_Status 1;
BA_ "GenSigMaxValue" SG_ 2348982443 SBCU11_PosRelay_Status 3;
BA_ "GenSigSendType" SG_ 2348982443 SBCU11_PosIso_Optical 1;
BA_ "GenSigMaxValue" SG_ 2348982443 SBCU11_PosIso_Optical 1;
BA_ "GenSigSendType" SG_ 2348982443 SBCU11_NegRelay_Status 1;
BA_ "GenSigMaxValue" SG_ 2348982443 SBCU11_NegRelay_Status 3;
BA_ "GenSigSendType" SG_ 2348982443 SBCU11_NegIso_Optical 1;
BA_ "GenSigMaxValue" SG_ 2348982443 SBCU11_NegIso_Optical 1;
BA_ "GenSigSendType" SG_ 2348982443 SBCU11_Life 1;
BA_ "GenSigMaxValue" SG_ 2348982443 SBCU11_Life 15;
BA_ "GenSigSendType" SG_ 2348982443 SBCU11_ISO_Status 1;
BA_ "GenSigMaxValue" SG_ 2348982443 SBCU11_ISO_Status 3;
BA_ "GenSigSendType" SG_ 2348982443 SBCU11_ISO_Allow 1;
BA_ "GenSigMaxValue" SG_ 2348982443 SBCU11_ISO_Allow 3;
BA_ "GenSigSendType" SG_ 2348982443 SBCU11_HVOff_Req 1;
BA_ "GenSigMaxValue" SG_ 2348982443 SBCU11_HVOff_Req 3;
BA_ "GenSigSendType" SG_ 2348982443 SBCU11_HV_Step 1;
BA_ "GenSigMaxValue" SG_ 2348982443 SBCU11_HV_Step 15;
BA_ "GenSigSendType" SG_ 2348982443 SBCU11_HeatRelay_Status 1;
BA_ "GenSigMaxValue" SG_ 2348982443 SBCU11_HeatRelay_Status 3;
BA_ "GenSigSendType" SG_ 2348982443 SBCU11_FcgRelay_Status 1;
BA_ "GenSigMaxValue" SG_ 2348982443 SBCU11_FcgRelay_Status 3;
BA_ "GenSigSendType" SG_ 2348982443 SBCU11_FaultLevel 1;
BA_ "GenSigMaxValue" SG_ 2348982443 SBCU11_FaultLevel 3;
BA_ "GenSigSendType" SG_ 2348982443 SBCU11_FaultCode 1;
BA_ "GenSigMaxValue" SG_ 2348982443 SBCU11_FaultCode 65535;
BA_ "GenSigSendType" SG_ 2348982443 SBCU11_FanRelay_Status 1;
BA_ "GenSigMaxValue" SG_ 2348982443 SBCU11_FanRelay_Status 3;
BA_ "GenSigSendType" SG_ 2348982443 SBCU11_DO3_Ctrl 1;
BA_ "GenSigMaxValue" SG_ 2348982443 SBCU11_DO3_Ctrl 1;
BA_ "GenSigSendType" SG_ 2348982443 SBCU11_DO2_Ctrl 1;
BA_ "GenSigMaxValue" SG_ 2348982443 SBCU11_DO2_Ctrl 1;
BA_ "GenSigSendType" SG_ 2348982443 SBCU11_DO1_Ctrl 1;
BA_ "GenSigMaxValue" SG_ 2348982443 SBCU11_DO1_Ctrl 1;
BA_ "GenSigSendType" SG_ 2348982443 SBCU11_DI5_Status 1;
BA_ "GenSigMaxValue" SG_ 2348982443 SBCU11_DI5_Status 1;
BA_ "GenSigSendType" SG_ 2348982443 SBCU11_DI4_Status 1;
BA_ "GenSigMaxValue" SG_ 2348982443 SBCU11_DI4_Status 1;
BA_ "GenSigSendType" SG_ 2348982443 SBCU11_DI3_Status 1;
BA_ "GenSigMaxValue" SG_ 2348982443 SBCU11_DI3_Status 1;
BA_ "GenSigSendType" SG_ 2348982443 SBCU11_DI2_Status 1;
BA_ "GenSigMaxValue" SG_ 2348982443 SBCU11_DI2_Status 1;
BA_ "GenSigSendType" SG_ 2348982443 SBCU11_DI1_Status 1;
BA_ "GenSigMaxValue" SG_ 2348982443 SBCU11_DI1_Status 1;
BA_ "GenSigSendType" SG_ 2348982443 SBCU11_BMS_RunStatus 1;
BA_ "GenSigMaxValue" SG_ 2348982443 SBCU11_BMS_RunStatus 15;
BA_ "GenSigSendType" SG_ 2550505643 SBCU11_DchPeakPower_Limit 1;
BA_ "GenSigMaxValue" SG_ 2550505643 SBCU11_DchPeakPower_Limit 65535;
BA_ "GenSigSendType" SG_ 2550505643 SBCU11_DchContinuousPower_Limit 1;
BA_ "GenSigMaxValue" SG_ 2550505643 SBCU11_DchContinuousPower_Limit 65535;
BA_ "GenSigSendType" SG_ 2550505643 SBCU11_ChgPeakPower_Limit 1;
BA_ "GenSigMaxValue" SG_ 2550505643 SBCU11_ChgPeakPower_Limit 65535;
BA_ "GenSigSendType" SG_ 2550505643 SBCU11_ChgContinuousPower_Limit 1;
BA_ "GenSigMaxValue" SG_ 2550505643 SBCU11_ChgContinuousPower_Limit 65535;
BA_ "GenSigSendType" SG_ 2550440107 SBCU11_DchPeakCurr_Limit 1;
BA_ "GenSigMaxValue" SG_ 2550440107 SBCU11_DchPeakCurr_Limit 65535;
BA_ "GenSigSendType" SG_ 2550440107 SBCU11_DchContinuousCurr_Limit 1;
BA_ "GenSigMaxValue" SG_ 2550440107 SBCU11_DchContinuousCurr_Limit 65535;
BA_ "GenSigSendType" SG_ 2550440107 SBCU11_ChgPeakCurr_Limit 1;
BA_ "GenSigMaxValue" SG_ 2550440107 SBCU11_ChgPeakCurr_Limit 65535;
BA_ "GenSigSendType" SG_ 2550440107 SBCU11_ChgContinuousCurr_Limit 1;
BA_ "GenSigMaxValue" SG_ 2550440107 SBCU11_ChgContinuousCurr_Limit 65535;
BA_ "GenSigSendType" SG_ 2550636715 SBCU11_CellVolt_Min_CellNO 1;
BA_ "GenSigMaxValue" SG_ 2550636715 SBCU11_CellVolt_Min_CellNO 255;
BA_ "GenSigSendType" SG_ 2550636715 SBCU11_CellVolt_Min_BMUNO 1;
BA_ "GenSigMaxValue" SG_ 2550636715 SBCU11_CellVolt_Min_BMUNO 255;
BA_ "GenSigSendType" SG_ 2550636715 SBCU11_CellVolt_Max_CellNO 1;
BA_ "GenSigMaxValue" SG_ 2550636715 SBCU11_CellVolt_Max_CellNO 255;
BA_ "GenSigSendType" SG_ 2550636715 SBCU11_CellVolt_Max_BMUNO 1;
BA_ "GenSigMaxValue" SG_ 2550636715 SBCU11_CellVolt_Max_BMUNO 255;
BA_ "GenSigSendType" SG_ 2550636715 SBCU11_CellTemp_Min_CellNO 1;
BA_ "GenSigMaxValue" SG_ 2550636715 SBCU11_CellTemp_Min_CellNO 255;
BA_ "GenSigSendType" SG_ 2550636715 SBCU11_CellTemp_Min_BMUNO 1;
BA_ "GenSigMaxValue" SG_ 2550636715 SBCU11_CellTemp_Min_BMUNO 255;
BA_ "GenSigSendType" SG_ 2550636715 SBCU11_CellTemp_Max_CellNO 1;
BA_ "GenSigMaxValue" SG_ 2550636715 SBCU11_CellTemp_Max_CellNO 255;
BA_ "GenSigSendType" SG_ 2550636715 SBCU11_CellTemp_Max_BMUNO 1;
BA_ "GenSigMaxValue" SG_ 2550636715 SBCU11_CellTemp_Max_BMUNO 255;
BA_ "GenSigSendType" SG_ 2550571179 SBCU11_CellVolt_Min 1;
BA_ "GenSigMaxValue" SG_ 2550571179 SBCU11_CellVolt_Min 65535;
BA_ "GenSigSendType" SG_ 2550571179 SBCU11_CellVolt_Mean 1;
BA_ "GenSigMaxValue" SG_ 2550571179 SBCU11_CellVolt_Mean 65535;
BA_ "GenSigSendType" SG_ 2550571179 SBCU11_CellVolt_Max 1;
BA_ "GenSigMaxValue" SG_ 2550571179 SBCU11_CellVolt_Max 65535;
BA_ "GenSigSendType" SG_ 2550571179 SBCU11_CellTemp_Min 1;
BA_ "GenSigMaxValue" SG_ 2550571179 SBCU11_CellTemp_Min 255;
BA_ "GenSigSendType" SG_ 2550571179 SBCU11_CellTemp_Max 1;
BA_ "GenSigMaxValue" SG_ 2550571179 SBCU11_CellTemp_Max 255;
BA_ "GenSigSendType" SG_ 2550702251 SBCU11_NTC2 1;
BA_ "GenSigMaxValue" SG_ 2550702251 SBCU11_NTC2 255;
BA_ "GenSigSendType" SG_ 2550702251 SBCU11_NTC1 1;
BA_ "GenSigMaxValue" SG_ 2550702251 SBCU11_NTC1 255;
BA_ "GenSigSendType" SG_ 2550702251 SBCU11_ISO_PosVolt 1;
BA_ "GenSigMaxValue" SG_ 2550702251 SBCU11_ISO_PosVolt 65535;
BA_ "GenSigSendType" SG_ 2550702251 SBCU11_ISO_NegVolt 1;
BA_ "GenSigMaxValue" SG_ 2550702251 SBCU11_ISO_NegVolt 65535;
BA_ "GenSigSendType" SG_ 2550702251 SBCU11_CellVolt_Sum 1;
BA_ "GenSigMaxValue" SG_ 2550702251 SBCU11_CellVolt_Sum 65535;
BA_ "GenSigSendType" SG_ 2566652075 SBCU11_CellBalance_Pack_NO 1;
BA_ "GenSigMaxValue" SG_ 2566652075 SBCU11_CellBalance_Pack_NO 255;
BA_ "GenSigSendType" SG_ 2566652075 SBCU11_CellBalance049 1;
BA_ "GenSigMaxValue" SG_ 2566652075 SBCU11_CellBalance049 255;
BA_ "GenSigSendType" SG_ 2566652075 SBCU11_CellBalance041 1;
BA_ "GenSigMaxValue" SG_ 2566652075 SBCU11_CellBalance041 255;
BA_ "GenSigSendType" SG_ 2566652075 SBCU11_CellBalance033 1;
BA_ "GenSigMaxValue" SG_ 2566652075 SBCU11_CellBalance033 255;
BA_ "GenSigSendType" SG_ 2566652075 SBCU11_CellBalance025 1;
BA_ "GenSigMaxValue" SG_ 2566652075 SBCU11_CellBalance025 255;
BA_ "GenSigSendType" SG_ 2566652075 SBCU11_CellBalance017 1;
BA_ "GenSigMaxValue" SG_ 2566652075 SBCU11_CellBalance017 255;
BA_ "GenSigSendType" SG_ 2566652075 SBCU11_CellBalance009 1;
BA_ "GenSigMaxValue" SG_ 2566652075 SBCU11_CellBalance009 255;
BA_ "GenSigSendType" SG_ 2566652075 SBCU11_CellBalance001 1;
BA_ "GenSigMaxValue" SG_ 2566652075 SBCU11_CellBalance001 255;
BA_ "GenSigSendType" SG_ 2565865643 SBCU11_CellVolt2_CellNO 1;
BA_ "GenSigMaxValue" SG_ 2565865643 SBCU11_CellVolt2_CellNO 255;
BA_ "GenSigSendType" SG_ 2565865643 SBCU11_CellVolt2_BMUNO 1;
BA_ "GenSigMaxValue" SG_ 2565865643 SBCU11_CellVolt2_BMUNO 255;
BA_ "GenSigSendType" SG_ 2565865643 SBCU11_CellVolt2 1;
BA_ "GenSigMaxValue" SG_ 2565865643 SBCU11_CellVolt2 65535;
BA_ "GenSigSendType" SG_ 2565865643 SBCU11_CellVolt1_CellNO 1;
BA_ "GenSigMaxValue" SG_ 2565865643 SBCU11_CellVolt1_CellNO 255;
BA_ "GenSigSendType" SG_ 2565865643 SBCU11_CellVolt1_BMUNO 1;
BA_ "GenSigMaxValue" SG_ 2565865643 SBCU11_CellVolt1_BMUNO 255;
BA_ "GenSigSendType" SG_ 2565865643 SBCU11_CellVolt1 1;
BA_ "GenSigMaxValue" SG_ 2565865643 SBCU11_CellVolt1 65535;
BA_ "GenSigSendType" SG_ 2550243499 SBCU11_SOC 1;
BA_ "GenSigMaxValue" SG_ 2550243499 SBCU11_SOC 65535;
BA_ "GenSigSendType" SG_ 2550243499 SBCU11_Pack_Volt 1;
BA_ "GenSigMaxValue" SG_ 2550243499 SBCU11_Pack_Volt 65535;
BA_ "GenSigSendType" SG_ 2550243499 SBCU11_LinkVolt 1;
BA_ "GenSigMaxValue" SG_ 2550243499 SBCU11_LinkVolt 65535;
BA_ "GenSigSendType" SG_ 2550243499 SBCU11_BusCurrent 1;
BA_ "GenSigMaxValue" SG_ 2550243499 SBCU11_BusCurrent 65535;
BA_ "GenSigStartValue" SG_ 2550243499 SBCU11_BusCurrent 32000;
